VERSION ""

NS_ :

BS_:

BU_: VDM CMR_DSMC SOBDMC_HPCM_FD1 IPMA_ADAS PSCM ABS_ESC TCCM TCM_DSL PCM_HEV PCM ECM_Diesel GENERIC_GWMWakeup GWM _delete TSTR

BO_ 90 Gear_Shift_by_Wire_FD1: 8 GWM
 SG_ TrnGsmNtmState_D_Actl : 55|2@0+ (1,0) [0|3] "SED"  ABS_ESC,PCM,PCM_HEV,TCM_DSL
 SG_ DrQltyDrv_D_StatGsm : 42|3@0+ (1,0) [0|7] "SED"  ABS_ESC,PCM,PCM_HEV,TCM_DSL,IPMA_ADAS
 SG_ TrnBtsiOvrrd_B_Stat : 43|1@0+ (1,0) [0|1] "SED"  PCM,PCM_HEV,TCM_DSL
 SG_ GsmGearMsgTxt_D_Rq : 63|2@0+ (1,0) [0|3] "SED" Vector__XXX
 SG_ TrnRng_D_RqGsm : 51|4@0+ (1,0) [0|15] "SED"  PCM,TCM_DSL
 SG_ PrkBrkActv_D_RqGsmGear : 53|2@0+ (1,0) [0|3] "SED"  ABS_ESC
 SG_ TrnValidGearRq_D_Stat : 25|2@0+ (1,0) [0|3] "SED"  PCM,PCM_HEV,TCM_DSL
 SG_ TrnGearRqCnt_B_Actl : 26|1@0+ (1,0) [0|1] "unitless"  PCM,PCM_HEV,TCM_DSL
 SG_ TrnGearButtn_U_Actl : 23|8@0+ (0.05,0) [0|12.7] "VOLT"  TCM_DSL
 SG_ TrnGearButtn_B_ActlR2 : 8|1@0+ (1,0) [0|1] "SED"  PCM,PCM_HEV,TCM_DSL
 SG_ TrnGearButtn_B_ActlR1 : 9|1@0+ (1,0) [0|1] "SED"  PCM,PCM_HEV,TCM_DSL
 SG_ TrnGearButtn_B_ActlR0 : 10|1@0+ (1,0) [0|1] "SED"  PCM,PCM_HEV,TCM_DSL
 SG_ TrnGearButtn_B_ActlP2 : 11|1@0+ (1,0) [0|1] "SED"  TCM_DSL,PCM,PCM_HEV
 SG_ TrnGearButtn_B_ActlP1 : 12|1@0+ (1,0) [0|1] "SED"  PCM,PCM_HEV,TCM_DSL
 SG_ TrnGearButtn_B_ActlP0 : 13|1@0+ (1,0) [0|1] "SED"  PCM,PCM_HEV,TCM_DSL
 SG_ TrnGearButtn_B_ActlN2 : 14|1@0+ (1,0) [0|1] "SED"  PCM,PCM_HEV,TCM_DSL
 SG_ TrnGearButtn_B_ActlN1 : 15|1@0+ (1,0) [0|1] "SED"  PCM,PCM_HEV,TCM_DSL
 SG_ TrnGearButtn_B_ActlN0 : 0|1@0+ (1,0) [0|1] "SED"  PCM,PCM_HEV,TCM_DSL
 SG_ TrnGearButtn_B_ActlM2 : 1|1@0+ (1,0) [0|1] "SED"  PCM,PCM_HEV,TCM_DSL
 SG_ TrnGearButtn_B_ActlM1 : 2|1@0+ (1,0) [0|1] "SED"  PCM,PCM_HEV,TCM_DSL
 SG_ TrnGearButtn_B_ActlM0 : 3|1@0+ (1,0) [0|1] "SED"  PCM,PCM_HEV,TCM_DSL
 SG_ TrnGearButtn_B_ActlD2 : 4|1@0+ (1,0) [0|1] "SED"  PCM,PCM_HEV,TCM_DSL
 SG_ TrnGearButtn_B_ActlD1 : 5|1@0+ (1,0) [0|1] "SED"  PCM,PCM_HEV,TCM_DSL
 SG_ TrnGearButtn_B_ActlD0 : 6|1@0+ (1,0) [0|1] "SED"  PCM,PCM_HEV,TCM_DSL
 SG_ TrnGear_No_Cs : 39|8@0+ (1,0) [0|255] "Unitless"  SOBDMC_HPCM_FD1,PCM,PCM_HEV,TCM_DSL
 SG_ TrnGear_No_Cnt : 47|4@0+ (1,0) [0|15] "Unitless"  SOBDMC_HPCM_FD1,PCM,PCM_HEV,TCM_DSL
 SG_ TrnGear_D_RqDrv : 31|5@0+ (1,0) [0|31] "SED"  SOBDMC_HPCM_FD1,PCM,PCM_HEV,TCM_DSL
 SG_ BrkSwtchPos_B_ActlGsm : 7|1@0+ (1,0) [0|1] "SED"  PCM,PCM_HEV,TCM_DSL

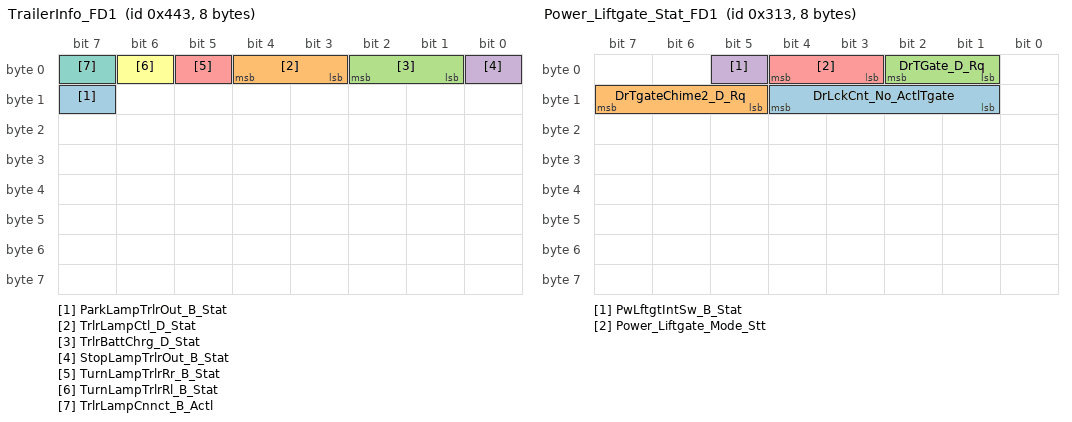
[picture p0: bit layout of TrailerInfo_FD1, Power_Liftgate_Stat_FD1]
BO_ 1091 TrailerInfo_FD1: 8 GWM
 SG_ ParkLampTrlrOut_B_Stat : 15|1@0+ (1,0) [0|1] "SED" Vector__XXX
 SG_ TrlrLampCtl_D_Stat : 4|2@0+ (1,0) [0|3] "SED" Vector__XXX
 SG_ TrlrBattChrg_D_Stat : 2|2@0+ (1,0) [0|3] "SED" Vector__XXX
 SG_ StopLampTrlrOut_B_Stat : 0|1@0+ (1,0) [0|1] "SED" Vector__XXX
 SG_ TurnLampTrlrRr_B_Stat : 5|1@0+ (1,0) [0|1] "SED" Vector__XXX
 SG_ TurnLampTrlrRl_B_Stat : 6|1@0+ (1,0) [0|1] "SED" Vector__XXX
 SG_ TrlrLampCnnct_B_Actl : 7|1@0+ (1,0) [0|1] "SED"  VDM,PCM_HEV,ECM_Diesel,PCM,TCM_DSL,ABS_ESC,IPMA_ADAS,PSCM

BO_ 138 ActiveFrontStrg_Stat2_FD1: 8 GWM
 SG_ SteWhlRelCalib_T_Actl : 7|8@0+ (1,0) [0|255] "ms" Vector__XXX
 SG_ SteWhlRelCalib_An_Sns : 15|15@0+ (0.1,-1600) [-1600|1676.5] "deg"  CMR_DSMC,PSCM,TCCM

BO_ 131 Steering_Data_FD1: 8 GWM
 SG_ AccButtnGapDecPress : 12|1@0+ (1,0) [0|1] "SED"  IPMA_ADAS
 SG_ HeadLghtHiCtrl_D_RqAhb : 43|3@0+ (1,0) [0|7] "SED" Vector__XXX
 SG_ AhbStat_B_Dsply : 33|1@0+ (1,0) [0|1] "SED" Vector__XXX
 SG_ WiprFrontSwtch_D_Stat : 47|4@0+ (1,0) [0|15] "SED" Vector__XXX
 SG_ HeadLghtHiOn_B_StatAhb : 34|1@0+ (1,0) [0|1] "SED"  IPMA_ADAS
 SG_ HeadLghtHiFlash_D_Actl : 36|2@0+ (1,0) [0|3] "SED"  IPMA_ADAS
 SG_ TjaButtnOnOffPress : 40|1@0+ (1,0) [0|1] "SED"  IPMA_ADAS
 SG_ AccButtnGapTogglePress : 32|1@0+ (1,0) [0|1] "SED"  IPMA_ADAS
 SG_ HeadLghtHiFlash_D_Stat : 7|2@0+ (1,0) [0|3] "SED" Vector__XXX
 SG_ WiprFront_D_Stat : 3|4@0+ (1,0) [0|15] "SED"  ABS_ESC,IPMA_ADAS,PCM,PCM_HEV
 SG_ TurnLghtSwtch_D_Stat : 5|2@0+ (1,0) [0|3] "SED"  IPMA_ADAS,PSCM
 SG_ LghtAmb_D_Sns : 15|3@0+ (1,0) [0|7] "SED"  IPMA_ADAS
 SG_ AccButtnGapIncPress : 11|1@0+ (1,0) [0|1] "SED"  IPMA_ADAS
 SG_ AslButtnOnOffPress : 9|1@0+ (1,0) [0|1] "SED"  ECM_Diesel,PCM,PCM_HEV
 SG_ AslButtnOnOffCnclPress : 10|1@0+ (1,0) [0|1] "SED"  ECM_Diesel,PCM,PCM_HEV
 SG_ CcButtnOnPress : 37|1@0+ (1,0) [0|1] "SED"  ECM_Diesel,IPMA_ADAS,PCM,PCM_HEV
 SG_ CcButtnOnOffPress : 38|1@0+ (1,0) [0|1] "SED"  ECM_Diesel,IPMA_ADAS,PCM,PCM_HEV
 SG_ CcButtnOnOffCnclPress : 39|1@0+ (1,0) [0|1] "SED"  ECM_Diesel,IPMA_ADAS,PCM,PCM_HEV
 SG_ CcButtnOffPress : 24|1@0+ (1,0) [0|1] "SED"  ECM_Diesel,IPMA_ADAS,PCM,PCM_HEV
 SG_ CcAsllButtnResPress : 25|1@0+ (1,0) [0|1] "SED"  ECM_Diesel,IPMA_ADAS,PCM,PCM_HEV
 SG_ CcAslButtnSetPress : 26|1@0+ (1,0) [0|1] "SED" Vector__XXX
 SG_ CcAslButtnSetIncPress : 27|1@0+ (1,0) [0|1] "SED"  ABS_ESC,ECM_Diesel,IPMA_ADAS,PCM,PCM_HEV
 SG_ CcAslButtnSetDecPress : 28|1@0+ (1,0) [0|1] "SED"  ABS_ESC,ECM_Diesel,IPMA_ADAS,PCM,PCM_HEV
 SG_ CcAslButtnResIncPress : 29|1@0+ (1,0) [0|1] "SED"  ABS_ESC,ECM_Diesel,IPMA_ADAS,PCM,PCM_HEV
 SG_ CcAslButtnResDecPress : 30|1@0+ (1,0) [0|1] "SED" Vector__XXX
 SG_ CcAslButtnOnPress : 31|1@0+ (1,0) [0|1] "SED"  ECM_Diesel,IPMA_ADAS,PCM,PCM_HEV
 SG_ CcAslButtnOnOffCncl : 16|1@0+ (1,0) [0|1] "SED" Vector__XXX
 SG_ CcAslButtnOffCnclPress : 17|1@0+ (1,0) [0|1] "SED" Vector__XXX
 SG_ CcAslButtnIndxIncPress : 18|1@0+ (1,0) [0|1] "SED"  ECM_Diesel,PCM,PCM_HEV
 SG_ CcAslButtnIndxDecPress : 19|1@0+ (1,0) [0|1] "SED"  ECM_Diesel,PCM,PCM_HEV
 SG_ CcAslButtnDeny_B_Actl : 20|1@0+ (1,0) [0|1] "SED"  ECM_Diesel,IPMA_ADAS,PCM,PCM_HEV
 SG_ CcAslButtnCnclResPress : 21|1@0+ (1,0) [0|1] "SED"  ECM_Diesel,IPMA_ADAS,PCM,PCM_HEV
 SG_ CcAslButtnCnclPress : 8|1@0+ (1,0) [0|1] "SED"  ECM_Diesel,IPMA_ADAS,PCM,PCM_HEV
 SG_ LaSwtchPos_D_Stat : 23|2@0+ (1,0) [0|3] "SED"  IPMA_ADAS

BO_ 787 Power_Liftgate_Stat_FD1: 8 GWM
 SG_ DrLckCnt_No_ActlTgate : 12|4@0+ (1,0) [0|15] "unitless" Vector__XXX
 SG_ DrTgateChime2_D_Rq : 15|3@0+ (1,0) [0|7] "SED" Vector__XXX
 SG_ DrTGate_D_Rq : 2|2@0+ (1,0) [0|3] "SED"  ECM_Diesel
 SG_ PwLftgtIntSw_B_Stat : 5|1@0+ (1,0) [0|1] "SED" Vector__XXX
 SG_ Power_Liftgate_Mode_Stt : 4|2@0+ (1,0) [0|3] "SED" Vector__XXX

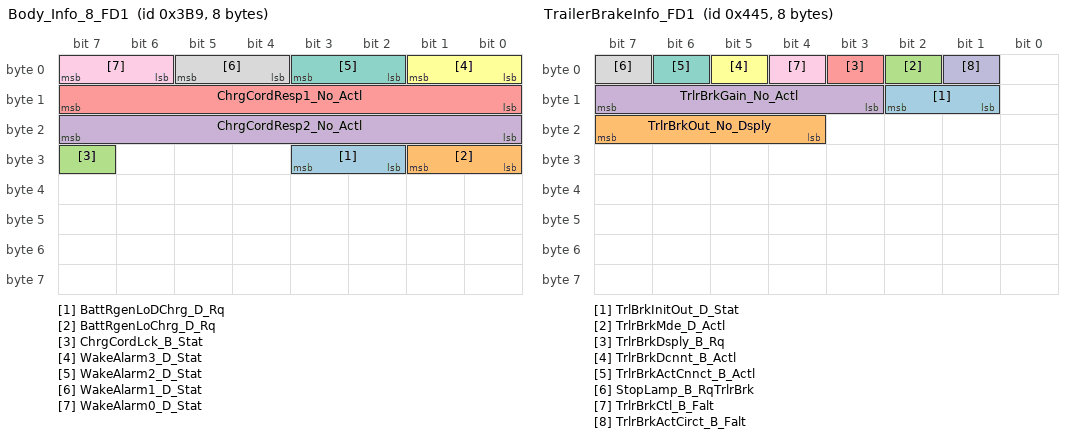
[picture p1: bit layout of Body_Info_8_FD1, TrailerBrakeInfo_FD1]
BO_ 953 Body_Info_8_FD1: 8 GWM
 SG_ BattRgenLoDChrg_D_Rq : 27|2@0+ (1,0) [0|3] "SED"  PCM_HEV,PCM
 SG_ BattRgenLoChrg_D_Rq : 25|2@0+ (1,0) [0|3] "SED"  PCM_HEV,PCM
 SG_ ChrgCordLck_B_Stat : 31|1@0+ (1,0) [0|1] "SED" Vector__XXX
 SG_ ChrgCordResp2_No_Actl : 23|8@0+ (1,0) [0|255] "unitless" Vector__XXX
 SG_ ChrgCordResp1_No_Actl : 15|8@0+ (1,0) [0|255] "unitless" Vector__XXX
 SG_ WakeAlarm3_D_Stat : 1|2@0+ (1,0) [0|3] "SED" Vector__XXX
 SG_ WakeAlarm2_D_Stat : 3|2@0+ (1,0) [0|3] "SED" Vector__XXX
 SG_ WakeAlarm1_D_Stat : 5|2@0+ (1,0) [0|3] "SED"  ECM_Diesel,PCM_HEV
 SG_ WakeAlarm0_D_Stat : 7|2@0+ (1,0) [0|3] "SED"  SOBDMC_HPCM_FD1

BO_ 1093 TrailerBrakeInfo_FD1: 8 GWM
 SG_ TrlBrkInitOut_D_Stat : 10|2@0+ (1,0) [0|3] "SED" Vector__XXX
 SG_ TrlrBrkOut_No_Dsply : 23|4@0+ (1,0) [0|15] "unitless" Vector__XXX
 SG_ TrlrBrkMde_D_Actl : 2|1@0+ (1,0) [0|1] "SED" Vector__XXX
 SG_ TrlrBrkGain_No_Actl : 15|5@0+ (0.5,0) [0|15.5] "unitless" Vector__XXX
 SG_ TrlrBrkDsply_B_Rq : 3|1@0+ (1,0) [0|1] "SED" Vector__XXX
 SG_ TrlrBrkDcnnt_B_Actl : 5|1@0+ (1,0) [0|1] "SED"  VDM
 SG_ TrlrBrkActCnnct_B_Actl : 6|1@0+ (1,0) [0|1] "SED"  VDM,ECM_Diesel,PCM,TCM_DSL,ABS_ESC,PSCM,TCCM,IPMA_ADAS
 SG_ StopLamp_B_RqTrlrBrk : 7|1@0+ (1,0) [0|1] "SED" Vector__XXX
 SG_ TrlrBrkCtl_B_Falt : 4|1@0+ (1,0) [0|1] "SED"  IPMA_ADAS
 SG_ TrlrBrkActCirct_B_Falt : 1|1@0+ (1,0) [0|1] "SED"  IPMA_ADAS

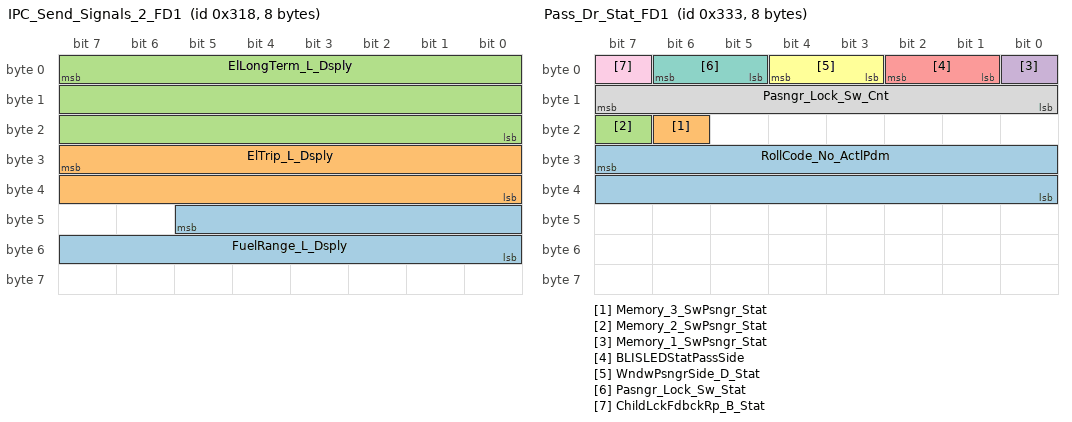
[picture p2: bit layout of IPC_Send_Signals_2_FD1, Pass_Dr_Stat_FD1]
BO_ 792 IPC_Send_Signals_2_FD1: 8 GWM
 SG_ FuelRange_L_Dsply : 45|14@0+ (0.1,0) [0|1638.3] "km"  ECM_Diesel
 SG_ ElTrip_L_Dsply : 31|16@0+ (0.1,0) [0|6553.3] "unitless" Vector__XXX
 SG_ ElLongTerm_L_Dsply : 7|24@0+ (0.1,0) [0|1677721.3] "unitless" Vector__XXX

BO_ 968 Cluster_Lighting_Rq_FD1: 8 GWM
 SG_ SlMde_D_Rq : 27|2@0+ (1,0) [0|3] "SED"  ECM_Diesel
 SG_ IsaOffst_D_Rq : 31|4@0+ (1,0) [0|15] "SED"  ECM_Diesel

BO_ 819 Pass_Dr_Stat_FD1: 8 GWM
 SG_ RollCode_No_ActlPdm : 31|16@0+ (1,0) [0|65535] "Unitless" Vector__XXX
 SG_ Memory_3_SwPsngr_Stat : 22|1@0+ (1,0) [0|1] "SED" Vector__XXX
 SG_ Memory_2_SwPsngr_Stat : 23|1@0+ (1,0) [0|1] "SED" Vector__XXX
 SG_ Memory_1_SwPsngr_Stat : 0|1@0+ (1,0) [0|1] "SED" Vector__XXX
 SG_ BLISLEDStatPassSide : 2|2@0+ (1,0) [0|3] "SED"  IPMA_ADAS
 SG_ WndwPsngrSide_D_Stat : 4|2@0+ (1,0) [0|3] "SED"  ECM_Diesel,PCM
 SG_ Pasngr_Lock_Sw_Stat : 6|2@0+ (1,0) [0|3] "SED" Vector__XXX
 SG_ Pasngr_Lock_Sw_Cnt : 15|8@0+ (1,0) [0|255] "Cnt" Vector__XXX
 SG_ ChildLckFdbckRp_B_Stat : 7|1@0+ (1,0) [0|1] "SED" Vector__XXX

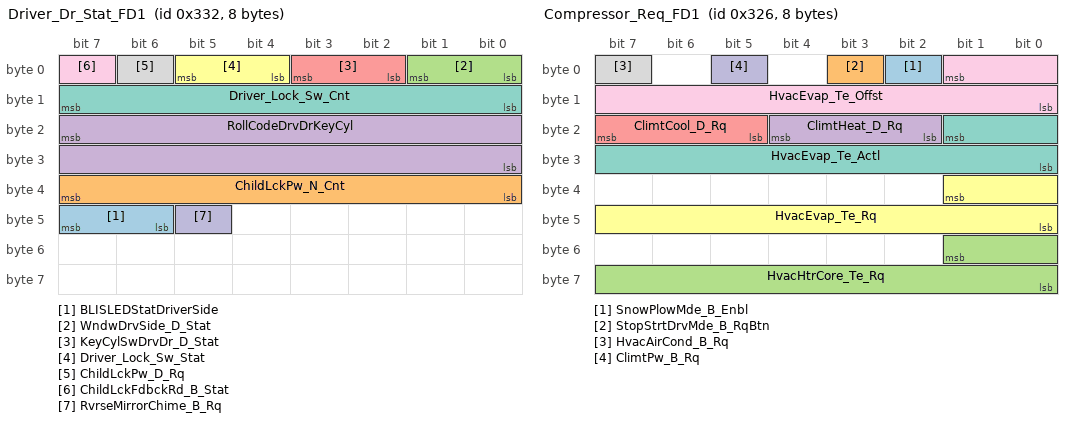
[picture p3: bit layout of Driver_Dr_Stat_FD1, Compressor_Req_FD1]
BO_ 818 Driver_Dr_Stat_FD1: 8 GWM
 SG_ BLISLEDStatDriverSide : 47|2@0+ (1,0) [0|3] "SED"  IPMA_ADAS
 SG_ ChildLckPw_N_Cnt : 39|8@0+ (1,0) [0|255] "unitless" Vector__XXX
 SG_ WndwDrvSide_D_Stat : 1|2@0+ (1,0) [0|3] "SED"  ECM_Diesel,PCM
 SG_ RollCodeDrvDrKeyCyl : 23|16@0+ (1,0) [0|65535] "Unitless" Vector__XXX
 SG_ KeyCylSwDrvDr_D_Stat : 3|2@0+ (1,0) [0|3] "SED" Vector__XXX
 SG_ Driver_Lock_Sw_Stat : 5|2@0+ (1,0) [0|3] "SED" Vector__XXX
 SG_ Driver_Lock_Sw_Cnt : 15|8@0+ (1,0) [0|255] "Cnt" Vector__XXX
 SG_ ChildLckPw_D_Rq : 6|1@0+ (1,0) [0|1] "SED" Vector__XXX
 SG_ ChildLckFdbckRd_B_Stat : 7|1@0+ (1,0) [0|1] "SED" Vector__XXX
 SG_ RvrseMirrorChime_B_Rq : 45|1@0+ (1,0) [0|1] "SED" Vector__XXX

BO_ 806 Compressor_Req_FD1: 8 GWM
 SG_ SnowPlowMde_B_Enbl : 2|1@0+ (1,0) [0|1] "SED" Vector__XXX
 SG_ StopStrtDrvMde_B_RqBtn : 3|1@0+ (1,0) [0|1] "SED"  ECM_Diesel,PCM
 SG_ HvacHtrCore_Te_Rq : 49|10@0+ (0.25,-50) [-50|205.75] "degC"  PCM_HEV,SOBDMC_HPCM_FD1,ECM_Diesel
 SG_ ClimtHeat_D_Rq : 20|3@0+ (1,0) [0|7] "SED"  SOBDMC_HPCM_FD1,ECM_Diesel,PCM,PCM_HEV
 SG_ ClimtCool_D_Rq : 23|3@0+ (1,0) [0|7] "SED"  SOBDMC_HPCM_FD1,ECM_Diesel,PCM,PCM_HEV
 SG_ HvacEvap_Te_Rq : 33|10@0+ (0.125,-50) [-50|77.875] "Degrees C"  SOBDMC_HPCM_FD1,ECM_Diesel,PCM,PCM_HEV
 SG_ HvacEvap_Te_Actl : 17|10@0+ (0.125,-50) [-50|77.75] "Degrees C"  SOBDMC_HPCM_FD1,ECM_Diesel,PCM,PCM_HEV
 SG_ HvacAirCond_B_Rq : 7|1@0+ (1,0) [0|1] "SED"  ECM_Diesel,PCM,PCM_HEV
 SG_ HvacEvap_Te_Offst : 1|10@0+ (0.125,-50) [-50|77.875] "Degrees C"  ECM_Diesel,PCM,PCM_HEV
 SG_ ClimtPw_B_Rq : 5|1@0+ (1,0) [0|1] "SED"  ECM_Diesel,PCM

BO_ 765 Mc_Send_Signals_2_FD1: 8 GWM
 SG_ Mc_VehTimeFrmtUsrSel_St : 1|2@0+ (1,0) [0|3] "SED" Vector__XXX
 SG_ Running_Board_Cmd : 21|2@0+ (1,0) [0|3] "SED" Vector__XXX
 SG_ EngExhMdeQuiet_D2_Rq : 55|3@0+ (1,0) [0|7] "SED"  PCM
 SG_ EdmSailMde_B_RqDrv : 48|1@0+ (1,0) [0|1] "SED"  ECM_Diesel
 SG_ DrvInputRequired_B_Rq : 32|1@0+ (1,0) [0|1] "SED" Vector__XXX
 SG_ AwdRnge_D_ActlIpc : 29|3@0+ (1,0) [0|7] "SED" Vector__XXX
 SG_ BalrSwtch_D_Stat : 57|2@0+ (1,0) [0|3] "SED"  IPMA_ADAS
 SG_ BalrMde_D_Rq : 59|2@0+ (1,0) [0|3] "SED"  IPMA_ADAS
 SG_ WaitToStartLamp_D_Falt : 50|2@0+ (1,0) [0|3] "SED"  ECM_Diesel
 SG_ EsaOn_B_Rq : 15|1@0+ (1,0) [0|1] "SED"  PSCM
 SG_ BttOn_B_Rq : 26|1@0+ (1,0) [0|1] "SED"  IPMA_ADAS
 SG_ Btt_L_Actl : 39|7@0+ (0.1,0) [0|12.5] "meter"  IPMA_ADAS
 SG_ SelDrvMdeTxtReset_B_Rq : 40|1@0+ (1,0) [0|1] "SED"  ABS_ESC
 SG_ SelDrvMdeDsply_B_Avail : 41|1@0+ (1,0) [0|1] "SED"  ABS_ESC
 SG_ Mc_VehUntTrpCoUsrSel_St : 23|1@0+ (1,0) [0|1] "SED" Vector__XXX
 SG_ Mc_VehUnitTempUsrSel_St : 22|1@0+ (1,0) [0|1] "SED" Vector__XXX
 SG_ Mc_VehLangUsrSel_St : 7|6@0+ (1,0) [0|63] "SED" Vector__XXX

BO_ 559 ElecHorizon_Data2_FD1: 8 GWM
 SG_ EhData2_No_Actl : 7|64@0+ (1,0) [0|1.84467440737096E+019] "unitless"  IPMA_ADAS,ECM_Diesel

BO_ 558 ElecHorizon_Data1_FD1: 8 GWM
 SG_ EhData1_No_Actl : 7|64@0+ (1,0) [0|1.84467440737096E+019] "unitless"  IPMA_ADAS,ECM_Diesel

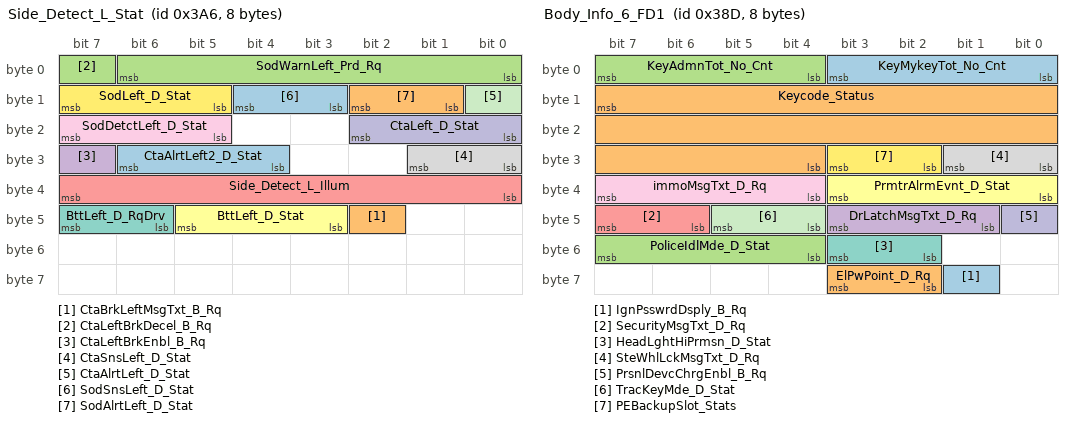
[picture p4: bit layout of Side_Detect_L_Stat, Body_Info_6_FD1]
BO_ 934 Side_Detect_L_Stat: 8 IPMA_ADAS
 SG_ CtaAlrtLeft2_D_Stat : 30|3@0+ (1,0) [0|7] "SED"  GWM
 SG_ CtaBrkLeftMsgTxt_B_Rq : 42|1@0+ (1,0) [0|1] "SED"  GWM
 SG_ CtaLeftBrkDecel_B_Rq : 7|1@0+ (1,0) [0|1] "SED"  GWM,ABS_ESC
 SG_ CtaLeftBrkEnbl_B_Rq : 31|1@0+ (1,0) [0|1] "SED"  GWM,ABS_ESC
 SG_ Side_Detect_L_Illum : 39|8@0+ (1,0) [0|255] "Percent"  GWM
 SG_ BttLeft_D_Stat : 45|3@0+ (1,0) [0|7] "SED"  GWM
 SG_ BttLeft_D_RqDrv : 47|2@0+ (1,0) [0|3] "SED"  GWM
 SG_ CtaSnsLeft_D_Stat : 25|2@0+ (1,0) [0|3] "SED"  GWM
 SG_ SodDetctLeft_D_Stat : 23|3@0+ (1,0) [0|7] "SED"  GWM
 SG_ CtaLeft_D_Stat : 18|3@0+ (1,0) [0|7] "SED"  GWM
 SG_ CtaAlrtLeft_D_Stat : 8|1@0+ (1,0) [0|1] "SED"  GWM
 SG_ SodLeft_D_Stat : 15|3@0+ (1,0) [0|7] "SED"  GWM
 SG_ SodSnsLeft_D_Stat : 12|2@0+ (1,0) [0|3] "SED"  GWM
 SG_ SodAlrtLeft_D_Stat : 10|2@0+ (1,0) [0|3] "SED"  GWM
 SG_ SodWarnLeft_Prd_Rq : 6|7@0+ (1,0) [0|127] "millisecond"  GWM

BO_ 1072 Cluster_Info1_FD1: 8 GWM
 SG_ LscmbbStat_B_Actl : 2|1@0+ (1,0) [0|1] "SED" Vector__XXX
 SG_ HaDsplyCpblty_B_Stat : 42|1@0+ (1,0) [0|1] "SED"  IPMA_ADAS
 SG_ AccDeny_B_RqIpc : 7|1@0+ (1,0) [0|1] "SED"  IPMA_ADAS
 SG_ DrvSlipCtlMde_D_Rq : 33|2@0+ (1,0) [0|3] "SED"  ABS_ESC
 SG_ EngIdlShutDown_B_RqDrv : 3|1@0+ (1,0) [0|1] "SED"  ECM_Diesel,PCM,PCM_HEV
 SG_ HsaMde_D_Rq : 54|2@0+ (1,0) [0|3] "SED"  ABS_ESC
 SG_ NtrlTowMdeEnbl_B_RqDrv : 1|1@0+ (1,0) [0|1] "SED"  TCCM,TCM_DSL,PCM_HEV,PCM
 SG_ BulbChkActv_B_Stat : 55|1@0+ (1,0) [0|1] "SED" Vector__XXX
 SG_ ParkDetect_Stat : 52|1@0+ (1,0) [0|1] "SED"  PCM_HEV,PCM
 SG_ ReducedGuard_D_Rq : 51|2@0+ (1,0) [0|3] "SED" Vector__XXX
 SG_ TrlrBrkMde_D_Rq : 57|1@0+ (1,0) [0|1] "SED" Vector__XXX
 SG_ TRLR_SWAY_CONFIG_CMD : 56|1@0+ (1,0) [0|1] "SED"  ABS_ESC
 SG_ TRAILER_BRAKE_CONFIG : 37|1@0+ (1,0) [0|1] "SED" Vector__XXX
 SG_ Power_Liftgate_Mode_Cmd : 39|1@0+ (1,0) [0|1] "SED" Vector__XXX
 SG_ AccEnbl_B_RqDrv : 35|1@0+ (1,0) [0|1] "SED"  IPMA_ADAS
 SG_ OdometerMasterValue : 15|24@0+ (1,0) [0|16777214] "km"  VDM,SOBDMC_HPCM_FD1,TCCM,CMR_DSMC,ABS_ESC,ECM_Diesel,IPMA_ADAS,PCM,PCM_HEV,PSCM,TCM_DSL
 SG_ EngOilLife_B_RqReset : 43|1@0+ (1,0) [0|1] "SED"  ECM_Diesel,PCM,PCM_HEV
 SG_ ePRNDL_MODE : 0|1@0+ (1,0) [0|1] "SED"  PCM,PCM_HEV,TCM_DSL
 SG_ DrvSlipCtlMde_B_Rq2 : 34|1@0+ (1,0) [0|1] "SED"  ABS_ESC
 SG_ MetricActv_B_Actl : 6|1@0+ (1,0) [0|1] "SED"  ECM_Diesel,IPMA_ADAS,PCM,PCM_HEV
 SG_ KeyTypeChngMykey_D_Rq : 41|2@0+ (1,0) [0|3] "SED" Vector__XXX
 SG_ ManRgen_D_Rq : 5|2@0+ (1,0) [0|3] "SED"  ECM_Diesel

BO_ 909 Body_Info_6_FD1: 8 GWM
 SG_ IgnPsswrdDsply_B_Rq : 57|1@0+ (1,0) [0|1] "SED" Vector__XXX
 SG_ ElPwPoint_D_Rq : 59|2@0+ (1,0) [0|3] "SED" Vector__XXX
 SG_ PoliceIdlMde_D_Stat : 55|4@0+ (1,0) [0|15] "SED" Vector__XXX
 SG_ DrLatchMsgTxt_D_Rq : 43|3@0+ (1,0) [0|7] "SED" Vector__XXX
 SG_ SecurityMsgTxt_D_Rq : 47|2@0+ (1,0) [0|3] "SED" Vector__XXX
 SG_ PrmtrAlrmEvnt_D_Stat : 35|4@0+ (1,0) [0|15] "SED" Vector__XXX
 SG_ HeadLghtHiPrmsn_D_Stat : 51|2@0+ (1,0) [0|3] "SED"  IPMA_ADAS
 SG_ SteWhlLckMsgTxt_D_Rq : 25|2@0+ (1,0) [0|3] "SED" Vector__XXX
 SG_ immoMsgTxt_D_Rq : 39|4@0+ (1,0) [0|15] "SED" Vector__XXX
 SG_ PrsnlDevcChrgEnbl_B_Rq : 40|1@0+ (1,0) [0|1] "SED" Vector__XXX
 SG_ TracKeyMde_D_Stat : 45|2@0+ (1,0) [0|3] "SED" Vector__XXX
 SG_ PEBackupSlot_Stats : 27|2@0+ (1,0) [0|3] "SED" Vector__XXX
 SG_ KeyMykeyTot_No_Cnt : 3|4@0+ (1,0) [0|15] "Counts" Vector__XXX
 SG_ Keycode_Status : 15|20@0+ (1,0) [0|1048575] "unitless" Vector__XXX
 SG_ KeyAdmnTot_No_Cnt : 7|4@0+ (1,0) [0|15] "Counts" Vector__XXX

BO_ 963 BCM_Lamp_Stat_FD1: 8 GWM
 SG_ Illuminated_Entry_Stat : 63|2@0+ (1,0) [0|3] "SED" Vector__XXX
 SG_ Dr_Courtesy_Light_Stat : 49|2@0+ (1,0) [0|3] "SED" Vector__XXX
 SG_ Courtesy_Delay_Status : 51|2@0+ (1,0) [0|3] "SED" Vector__XXX
 SG_ ImpactEvntFdbck_D_Stat : 53|2@0+ (1,0) [0|3] "SED"  CMR_DSMC
 SG_ WrlssAcsyChrgInhbt_B_Rq : 40|1@0+ (1,0) [0|1] "SED" Vector__XXX
 SG_ PudLampPsngr_D_Rq : 57|2@0+ (1,0) [0|3] "SED" Vector__XXX
 SG_ HeadLampLoOut_B_Stat : 32|1@0+ (1,0) [0|1] "SED" Vector__XXX
 SG_ CrnrLghtRight_Pc_Rq : 47|7@0+ (1,0) [0|100] "percent" Vector__XXX
 SG_ CrnrLghtLeft_Pc_Rq : 39|7@0+ (1,0) [0|100] "percent" Vector__XXX
 SG_ HeadLghtHiFdbck_D_Stat : 55|2@0+ (1,0) [0|3] "SED" Vector__XXX
 SG_ PudLampDrv_D_Rq : 59|2@0+ (1,0) [0|3] "SED" Vector__XXX
 SG_ TrnNotInPrkChime_B_Rq : 24|1@0+ (1,0) [0|1] "SED" Vector__XXX
 SG_ PrkLightChime_B_Rq : 25|1@0+ (1,0) [0|1] "SED" Vector__XXX
 SG_ KeyInIgnWarn_B_Cmd : 27|1@0+ (1,0) [0|1] "SED" Vector__XXX
 SG_ HomeSafeLtChime_B_Rq : 28|1@0+ (1,0) [0|1] "SED" Vector__XXX
 SG_ StopLghtOn_B_Stat : 8|1@0+ (1,0) [0|1] "SED" Vector__XXX
 SG_ RvrseLghtOn_B_Stat : 9|1@0+ (1,0) [0|1] "SED" Vector__XXX
 SG_ PrkLght_D_Stat : 13|2@0+ (1,0) [0|3] "SED" Vector__XXX
 SG_ HeadLghtSwtch_D_Stat : 15|2@0+ (1,0) [0|3] "SED"  IPMA_ADAS
 SG_ HeadLampLoFrOn_B_Stat : 2|1@0+ (1,0) [0|1] "SED"  IPMA_ADAS
 SG_ HeadLampLoFlOn_B_Stat : 3|1@0+ (1,0) [0|1] "SED"  IPMA_ADAS
 SG_ HeadLampLoActv_B_Stat : 4|1@0+ (1,0) [0|1] "SED"  IPMA_ADAS,PCM,ECM_Diesel
 SG_ Headlamp_On_Wrning_Cmd : 29|1@0+ (1,0) [0|1] "SED" Vector__XXX
 SG_ Park_Brake_Chime_Rqst : 26|1@0+ (1,0) [0|1] "SED" Vector__XXX
 SG_ HeadLghtHiOn_B_Stat : 1|1@0+ (1,0) [0|1] "SED"  ECM_Diesel,IPMA_ADAS,PCM
 SG_ BrkWarnInd_B_Rq : 20|1@0+ (1,0) [0|1] "SED" Vector__XXX
 SG_ Brk_Fluid_Lvl_Low : 31|2@0+ (1,0) [0|3] "SED" Vector__XXX
 SG_ ReducedGuard_D_Stat : 19|2@0+ (1,0) [0|3] "SED" Vector__XXX
 SG_ Perimeter_Alarm_Status : 17|2@0+ (1,0) [0|3] "SED"  ABS_ESC
 SG_ Courtesy_BSave_Stat : 7|2@0+ (1,0) [0|3] "SED" Vector__XXX
 SG_ DrTgateLck_D_Stat : 61|2@0+ (1,0) [0|3] "SED" Vector__XXX
 SG_ WndwGlbl_D_Cmd : 23|3@0+ (1,0) [0|7] "SED" Vector__XXX
 SG_ PudLamp_D_Rq : 11|2@0+ (1,0) [0|3] "SED" Vector__XXX
 SG_ DayRnngLampOn_B_Stat : 5|1@0+ (1,0) [0|1] "SED" Vector__XXX
 SG_ PerimeterAlarmChimeRq : 0|1@0+ (1,0) [0|1] "SED" Vector__XXX

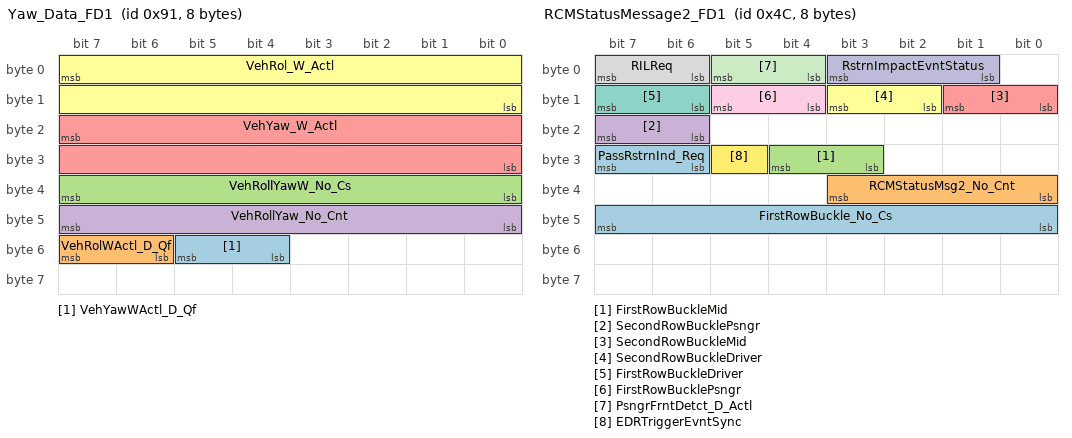
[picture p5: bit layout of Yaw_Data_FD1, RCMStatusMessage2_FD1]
BO_ 145 Yaw_Data_FD1: 8 GWM
 SG_ VehYawWActl_D_Qf : 53|2@0+ (1,0) [0|3] "SED"  VDM,IPMA_ADAS,ABS_ESC
 SG_ VehRolWActl_D_Qf : 55|2@0+ (1,0) [0|3] "SED"  VDM,IPMA_ADAS,ABS_ESC
 SG_ VehRollYawW_No_Cs : 39|8@0+ (1,0) [0|255] "Unitless"  IPMA_ADAS,ABS_ESC
 SG_ VehRollYaw_No_Cnt : 47|8@0+ (1,0) [0|255] "Unitless"  VDM,IPMA_ADAS,ABS_ESC
 SG_ VehYaw_W_Actl : 23|16@0+ (0.0002,-6.5) [-6.5|6.6066] "rad/s"  VDM,ABS_ESC,PSCM,IPMA_ADAS
 SG_ VehRol_W_Actl : 7|16@0+ (0.0002,-6.5) [-6.5|6.6066] "rad/s"  VDM,ABS_ESC,IPMA_ADAS

BO_ 76 RCMStatusMessage2_FD1: 8 GWM
 SG_ FirstRowBuckle_No_Cs : 47|8@0+ (1,0) [0|255] "unitless"  IPMA_ADAS
 SG_ RCMStatusMsg2_No_Cnt : 35|4@0+ (1,0) [0|15] "Unitless"  IPMA_ADAS
 SG_ FirstRowBuckleMid : 28|2@0+ (1,0) [0|3] "SED"  IPMA_ADAS
 SG_ SecondRowBucklePsngr : 23|2@0+ (1,0) [0|3] "SED" Vector__XXX
 SG_ SecondRowBuckleMid : 9|2@0+ (1,0) [0|3] "SED" Vector__XXX
 SG_ SecondRowBuckleDriver : 11|2@0+ (1,0) [0|3] "SED" Vector__XXX
 SG_ FirstRowBuckleDriver : 15|2@0+ (1,0) [0|3] "SED"  CMR_DSMC,ABS_ESC,IPMA_ADAS,ECM_Diesel,PCM,PCM_HEV,TCM_DSL
 SG_ RILReq : 7|2@0+ (1,0) [0|3] "SED" Vector__XXX
 SG_ FirstRowBucklePsngr : 13|2@0+ (1,0) [0|3] "SED"  IPMA_ADAS
 SG_ RstrnImpactEvntStatus : 3|3@0+ (1,0) [0|7] "SED"  CMR_DSMC,SOBDMC_HPCM_FD1,ABS_ESC,IPMA_ADAS,ECM_Diesel,PCM,PCM_HEV,TCM_DSL
 SG_ PsngrFrntDetct_D_Actl : 5|2@0+ (1,0) [0|3] "SED" Vector__XXX
 SG_ EDRTriggerEvntSync : 29|1@0+ (1,0) [0|1] "SED"  IPMA_ADAS
 SG_ PassRstrnInd_Req : 31|2@0+ (1,0) [0|3] "SED" Vector__XXX

BO_ 65 Global_PATS_Cntrl_Info_FD1: 8 GWM
 SG_ immoControlData_T1 : 15|40@0+ (1,0) [0|1099511627775] "Encrypted"  ECM_Diesel,PCM,PCM_HEV
 SG_ immoControlCmd_T1 : 7|3@0+ (1,0) [0|7] "SED"  ECM_Diesel,PCM,PCM_HEV

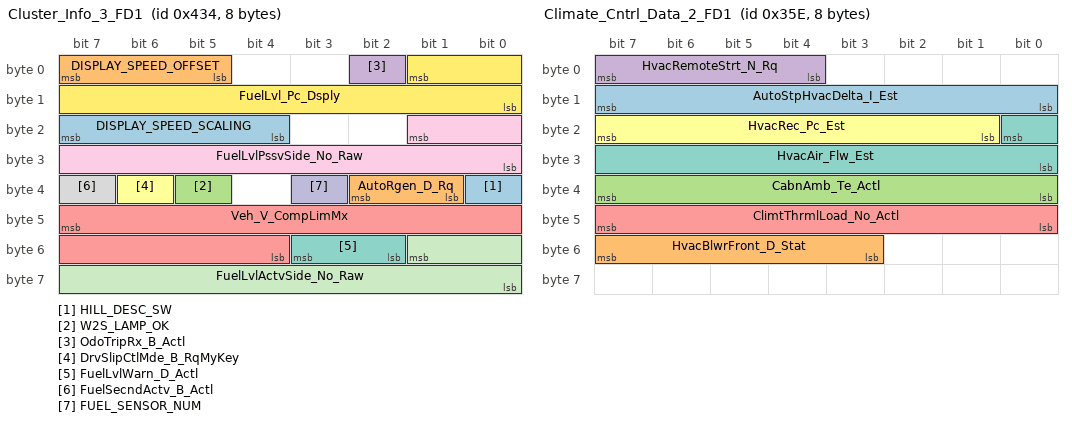
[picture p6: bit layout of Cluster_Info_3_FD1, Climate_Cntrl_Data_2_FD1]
BO_ 1076 Cluster_Info_3_FD1: 8 GWM
 SG_ HILL_DESC_SW : 32|1@0+ (1,0) [0|1] "SED"  ABS_ESC
 SG_ AutoRgen_D_Rq : 34|2@0+ (1,0) [0|3] "SED"  ECM_Diesel
 SG_ W2S_LAMP_OK : 37|1@0+ (1,0) [0|1] "SED" Vector__XXX
 SG_ OdoTripRx_B_Actl : 2|1@0+ (1,0) [0|1] "SED"  ECM_Diesel,PCM,PCM_HEV
 SG_ Veh_V_CompLimMx : 47|12@0+ (0.1,0) [0|409.5] "km/h"  ECM_Diesel,PCM,PCM_HEV
 SG_ DrvSlipCtlMde_B_RqMyKey : 38|1@0+ (1,0) [0|1] "SED"  ABS_ESC
 SG_ FuelLvlWarn_D_Actl : 51|2@0+ (1,0) [0|3] "SED" Vector__XXX
 SG_ FuelSecndActv_B_Actl : 39|1@0+ (1,0) [0|1] "SED" Vector__XXX
 SG_ FuelLvlPssvSide_No_Raw : 17|10@0+ (1,0) [0|1023] "Unitless"  ECM_Diesel,PCM,PCM_HEV
 SG_ FUEL_SENSOR_NUM : 35|1@0+ (1,0) [0|1] "SED"  ECM_Diesel,PCM,PCM_HEV
 SG_ FuelLvlActvSide_No_Raw : 49|10@0+ (1,0) [0|1023] "Unitless"  ECM_Diesel,PCM,PCM_HEV
 SG_ FuelLvl_Pc_Dsply : 1|10@0+ (0.108696,-5.217408) [-5.217408|105.9786] "Percent"  VDM,ECM_Diesel
 SG_ DISPLAY_SPEED_SCALING : 23|4@0+ (0.5,100) [100|107.5] "%"  IPMA_ADAS,ECM_Diesel,PCM,PCM_HEV
 SG_ DISPLAY_SPEED_OFFSET : 7|3@0+ (0.5,0) [0|3.5] "kph"  IPMA_ADAS,ECM_Diesel,PCM,PCM_HEV

BO_ 862 Climate_Cntrl_Data_2_FD1: 8 GWM
 SG_ AutoStpHvacDelta_I_Est : 15|8@0+ (1,-192) [-192|62] "ampere" Vector__XXX
 SG_ HvacBlwrFront_D_Stat : 55|5@0+ (1,0) [0|31] "SED"  ECM_Diesel,PCM,PCM_HEV
 SG_ CabnAmb_Te_Actl : 39|8@0+ (0.5,-57) [-57|70] "degreesC"  SOBDMC_HPCM_FD1,PCM_HEV
 SG_ HvacRemoteStrt_N_Rq : 7|4@0+ (100,450) [450|1950] "RPM"  ECM_Diesel,PCM,PCM_HEV
 SG_ ClimtThrmlLoad_No_Actl : 47|8@0+ (1,0) [0|254] "unitless"  SOBDMC_HPCM_FD1,PCM_HEV
 SG_ HvacRec_Pc_Est : 23|7@0+ (1,0) [0|127] "Percent"  PCM_HEV,SOBDMC_HPCM_FD1
 SG_ HvacAir_Flw_Est : 16|9@0+ (0.5,0) [0|255.5] "liter/second"  PCM_HEV,SOBDMC_HPCM_FD1

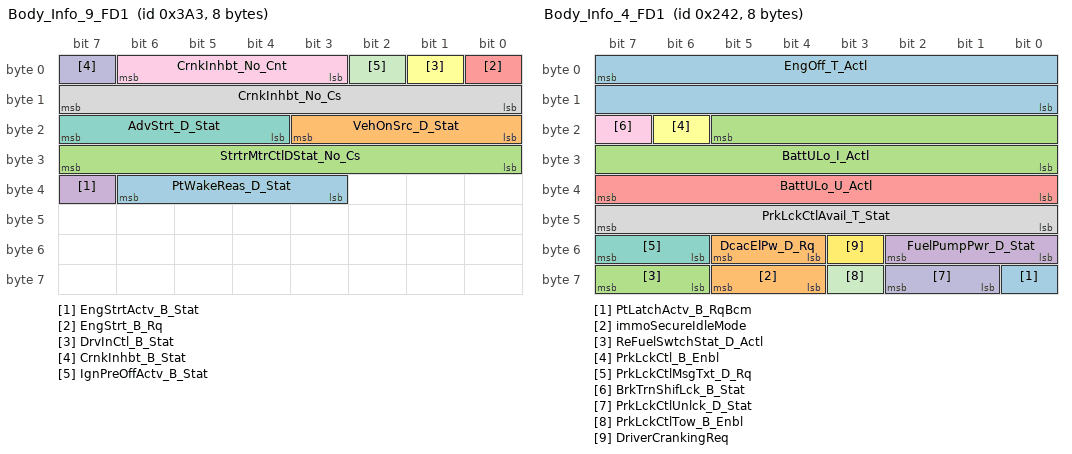
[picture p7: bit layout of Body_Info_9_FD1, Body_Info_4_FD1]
BO_ 931 Body_Info_9_FD1: 8 GWM
 SG_ PtWakeReas_D_Stat : 38|4@0+ (1,0) [0|15] "SED"  PCM_HEV
 SG_ VehOnSrc_D_Stat : 19|4@0+ (1,0) [0|15] "SED"  SOBDMC_HPCM_FD1,ABS_ESC,PCM_HEV,ECM_Diesel,PCM
 SG_ StrtrMtrCtlDStat_No_Cs : 31|8@0+ (1,0) [0|255] "unitless"  SOBDMC_HPCM_FD1,PCM_HEV,ECM_Diesel,PCM
 SG_ EngStrtActv_B_Stat : 39|1@0+ (1,0) [0|1] "SED"  SOBDMC_HPCM_FD1,PCM_HEV,ECM_Diesel,PCM
 SG_ EngStrt_B_Rq : 0|1@0+ (1,0) [0|1] "SED"  SOBDMC_HPCM_FD1,PCM_HEV,ECM_Diesel,PCM
 SG_ DrvInCtl_B_Stat : 1|1@0+ (1,0) [0|1] "SED"  SOBDMC_HPCM_FD1,ECM_Diesel,PCM,PCM_HEV
 SG_ AdvStrt_D_Stat : 23|4@0+ (1,0) [0|15] "SED"  SOBDMC_HPCM_FD1,PCM_HEV,ECM_Diesel,PCM
 SG_ CrnkInhbt_No_Cs : 15|8@0+ (1,0) [0|255] "Unitless"  ECM_Diesel,PCM,PCM_HEV
 SG_ CrnkInhbt_No_Cnt : 6|4@0+ (1,0) [0|15] "Unitless"  SOBDMC_HPCM_FD1,ECM_Diesel,PCM,PCM_HEV
 SG_ CrnkInhbt_B_Stat : 7|1@0+ (1,0) [0|1] "SED"  SOBDMC_HPCM_FD1,ECM_Diesel,PCM,PCM_HEV
 SG_ IgnPreOffActv_B_Stat : 2|1@0+ (1,0) [0|1] "SED"  PCM,PCM_HEV,TCM_DSL

BO_ 578 Body_Info_4_FD1: 8 GWM
 SG_ PtLatchActv_B_RqBcm : 56|1@0+ (1,0) [0|1] "SED"  ECM_Diesel,PCM,PCM_HEV,TCM_DSL
 SG_ immoSecureIdleMode : 61|2@0+ (1,0) [0|3] "SED"  ECM_Diesel,PCM,PCM_HEV
 SG_ ReFuelSwtchStat_D_Actl : 63|2@0+ (1,0) [0|3] "SED" Vector__XXX
 SG_ FuelPumpPwr_D_Stat : 50|3@0+ (1,0) [0|7] "SED"  ECM_Diesel,PCM,PCM_HEV
 SG_ BattULo_U_Actl : 39|8@0+ (0.0625,0) [0|15.875] "volt"  CMR_DSMC,SOBDMC_HPCM_FD1,ABS_ESC,IPMA_ADAS,PSCM,ECM_Diesel,PCM,PCM_HEV
 SG_ PrkLckCtl_B_Enbl : 22|1@0+ (1,0) [0|1] "SED" Vector__XXX
 SG_ PrkLckCtlMsgTxt_D_Rq : 55|2@0+ (1,0) [0|3] "SED" Vector__XXX
 SG_ PrkLckCtlAvail_T_Stat : 47|8@0+ (1,0) [0|255] "second" Vector__XXX
 SG_ BrkTrnShifLck_B_Stat : 23|1@0+ (1,0) [0|1] "SED"  PCM,PCM_HEV,TCM_DSL
 SG_ PrkLckCtlUnlck_D_Stat : 58|2@0+ (1,0) [0|3] "SED" Vector__XXX
 SG_ PrkLckCtlTow_B_Enbl : 59|1@0+ (1,0) [0|1] "SED" Vector__XXX
 SG_ DriverCrankingReq : 51|1@0+ (1,0) [0|1] "SED"  ECM_Diesel,PCM,PCM_HEV
 SG_ EngOff_T_Actl : 7|16@0+ (1,0) [0|65534] "second^0.5"  ABS_ESC,IPMA_ADAS,TCCM,ECM_Diesel,PCM,PCM_HEV,TCM_DSL
 SG_ DcacElPw_D_Rq : 53|2@0+ (1,0) [0|3] "SED"  ECM_Diesel,PCM
 SG_ BattULo_I_Actl : 21|14@0+ (0.0625,-512) [-512|511.875] "ampere"  ECM_Diesel,PCM,PCM_HEV

BO_ 947 BodyInfo_3_FD1: 8 GWM
 SG_ ValetMode_D_Mem : 16|1@0+ (1,0) [0|1] "SED" Vector__XXX
 SG_ DimmingLvlEvnt_No_Actl : 18|2@0+ (1,0) [0|3] "unitless" Vector__XXX
 SG_ DrStatDrvErrCnt_B_Stat : 19|1@0+ (1,0) [0|1] "SED"  ECM_Diesel,PCM,PCM_HEV
 SG_ TurnLghtRight_D_Rq : 63|2@0+ (1,0) [0|3] "SED"  CMR_DSMC,IPMA_ADAS
 SG_ TurnLghtRightOn_B_Stat : 35|1@0+ (1,0) [0|1] "SED" Vector__XXX
 SG_ TurnLghtLeftOn_B_Stat : 54|1@0+ (1,0) [0|1] "SED" Vector__XXX
 SG_ FogLghtRearOn_B_Stat : 1|1@0+ (1,0) [0|1] "SED"  IPMA_ADAS
 SG_ Backlit_LED_Status : 23|4@0+ (1,0) [0|15] "SED" Vector__XXX
 SG_ TurnLghtLeft_D_Rq : 9|2@0+ (1,0) [0|3] "SED"  CMR_DSMC,IPMA_ADAS
 SG_ FogLghtFrontOn_B_Stat : 56|1@0+ (1,0) [0|1] "SED"  IPMA_ADAS
 SG_ IgnKeyType_D_Actl : 39|4@0+ (1,0) [0|15] "SED"  ABS_ESC,ECM_Diesel,IPMA_ADAS,PCM,PCM_HEV
 SG_ Parklamp_Status : 3|2@0+ (1,0) [0|3] "SED"  IPMA_ADAS
 SG_ Litval : 47|8@0+ (1,0) [0|253] "SED"  IPMA_ADAS
 SG_ Key_In_Ignition_Stat : 11|1@0+ (1,0) [0|1] "SED"  ABS_ESC
 SG_ Ignition_Status : 7|4@0+ (1,0) [0|15] "SED"  VDM,CMR_DSMC,SOBDMC_HPCM_FD1,ABS_ESC,ECM_Diesel,IPMA_ADAS,PCM,PCM_HEV,PSCM,TCCM,TCM_DSL
 SG_ Dimming_Lvl : 31|8@0+ (1,0) [0|253] "SED"  IPMA_ADAS
 SG_ Day_Night_Status : 15|2@0+ (1,0) [0|3] "SED"  CMR_DSMC,ECM_Diesel,IPMA_ADAS,PCM
 SG_ Remote_Start_Status : 13|2@0+ (1,0) [0|3] "SED"  CMR_DSMC,IPMA_ADAS
 SG_ DrStatTgate_B_Actl : 0|1@0+ (1,0) [0|1] "SED"  IPMA_ADAS
 SG_ DrStatRr_B_Actl : 49|1@0+ (1,0) [0|1] "SED"  ABS_ESC,IPMA_ADAS
 SG_ DrStatRl_B_Actl : 48|1@0+ (1,0) [0|1] "SED"  ABS_ESC,IPMA_ADAS
 SG_ DrStatPsngr_B_Actl : 60|1@0+ (1,0) [0|1] "SED"  CMR_DSMC,ABS_ESC,IPMA_ADAS
 SG_ DrStatInnrTgate_B_Actl : 58|1@0+ (1,0) [0|1] "SED"  IPMA_ADAS
 SG_ DrStatHood_B_Actl : 59|1@0+ (1,0) [0|1] "SED" Vector__XXX
 SG_ DrStatDrv_B_Actl : 61|1@0+ (1,0) [0|1] "SED"  CMR_DSMC,ABS_ESC,ECM_Diesel,IPMA_ADAS,PCM,PCM_HEV,TCCM
 SG_ PrkBrkActv_B_Actl : 55|1@0+ (1,0) [0|1] "SED"  ABS_ESC,ECM_Diesel,IPMA_ADAS,PCM,PCM_HEV,TCCM,TCM_DSL
 SG_ LifeCycMde_D_Actl : 53|4@0+ (1,0) [0|15] "SED"  VDM,SOBDMC_HPCM_FD1,ABS_ESC,ECM_Diesel,IPMA_ADAS,PCM,PCM_HEV,PSCM,TCM_DSL
 SG_ Delay_Accy : 57|1@0+ (1,0) [0|1] "SED" Vector__XXX
 SG_ CrashEvnt_D_Stat : 34|2@0+ (1,0) [0|3] "SED" Vector__XXX
 SG_ FuelPmpInhbt_B_Stat : 32|1@0+ (1,0) [0|1] "SED" Vector__XXX
 SG_ BodySrvcRqd_B_Rq : 10|1@0+ (1,0) [0|1] "SED" Vector__XXX

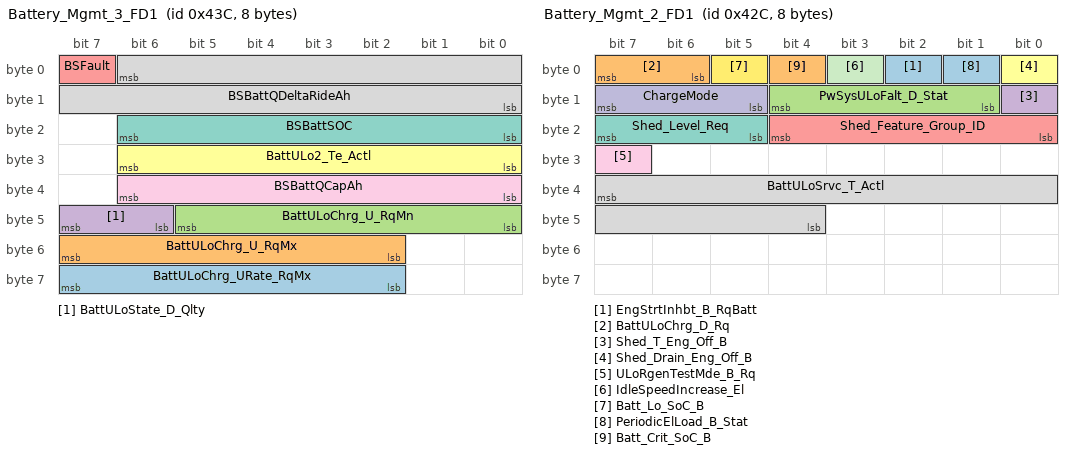
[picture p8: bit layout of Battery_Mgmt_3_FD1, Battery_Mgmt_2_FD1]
BO_ 1084 Battery_Mgmt_3_FD1: 8 GWM
 SG_ BattULoChrg_URate_RqMx : 63|6@0+ (0.1,0) [0|6.3] "volts/second"  ECM_Diesel,PCM,PCM_HEV
 SG_ BattULoChrg_U_RqMx : 55|6@0+ (0.1,10.6) [10.6|16.9] "volt"  ECM_Diesel,PCM,PCM_HEV
 SG_ BattULoChrg_U_RqMn : 45|6@0+ (0.1,10.6) [10.6|16.9] "volt"  ECM_Diesel,PCM,PCM_HEV
 SG_ BattULoState_D_Qlty : 47|2@0+ (1,0) [0|3] "SED"  ECM_Diesel,PCM,PCM_HEV
 SG_ BSFault : 7|1@0+ (1,0) [0|1] "SED"  ECM_Diesel,PCM,PCM_HEV
 SG_ BattULo2_Te_Actl : 30|7@0+ (1,-40) [-40|86] "degC"  ECM_Diesel,PCM,PCM_HEV
 SG_ BSBattSOC : 22|7@0+ (1,0) [0|127] "%"  ECM_Diesel,PCM,PCM_HEV
 SG_ BSBattQDeltaRideAh : 6|15@0+ (0.0078125,-100) [-100|155.9921875] "ampere*hour"  ECM_Diesel,PCM,PCM_HEV
 SG_ BSBattQCapAh : 38|7@0+ (1,0) [0|127] "ampere*hour"  ECM_Diesel,PCM,PCM_HEV

BO_ 1068 Battery_Mgmt_2_FD1: 8 GWM
 SG_ EngStrtInhbt_B_RqBatt : 2|1@0+ (1,0) [0|1] "SED"  ECM_Diesel,PCM
 SG_ BattULoChrg_D_Rq : 7|2@0+ (1,0) [0|3] "SED"  ECM_Diesel,PCM
 SG_ PwSysULoFalt_D_Stat : 12|4@0+ (1,0) [0|15] "SED" Vector__XXX
 SG_ Shed_T_Eng_Off_B : 8|1@0+ (1,0) [0|1] "SED" Vector__XXX
 SG_ Shed_Feature_Group_ID : 20|5@0+ (1,0) [0|31] "SED"  ECM_Diesel,PCM,PCM_HEV,IPMA_ADAS
 SG_ Shed_Drain_Eng_Off_B : 0|1@0+ (1,0) [0|1] "SED" Vector__XXX
 SG_ Shed_Level_Req : 23|3@0+ (1,0) [0|7] "SED"  ECM_Diesel,PCM,PCM_HEV,IPMA_ADAS
 SG_ BattULoSrvc_T_Actl : 39|12@0+ (1,0) [0|4095] "days" Vector__XXX
 SG_ ULoRgenTestMde_B_Rq : 31|1@0+ (1,0) [0|1] "SED"  ECM_Diesel,PCM
 SG_ ChargeMode : 15|3@0+ (1,0) [0|7] "SED"  ECM_Diesel,PCM
 SG_ IdleSpeedIncrease_El : 3|1@0+ (1,0) [0|1] "SED" Vector__XXX
 SG_ Batt_Lo_SoC_B : 5|1@0+ (1,0) [0|1] "SED" Vector__XXX
 SG_ PeriodicElLoad_B_Stat : 1|1@0+ (1,0) [0|1] "SED"  ECM_Diesel
 SG_ Batt_Crit_SoC_B : 4|1@0+ (1,0) [0|1] "SED" Vector__XXX

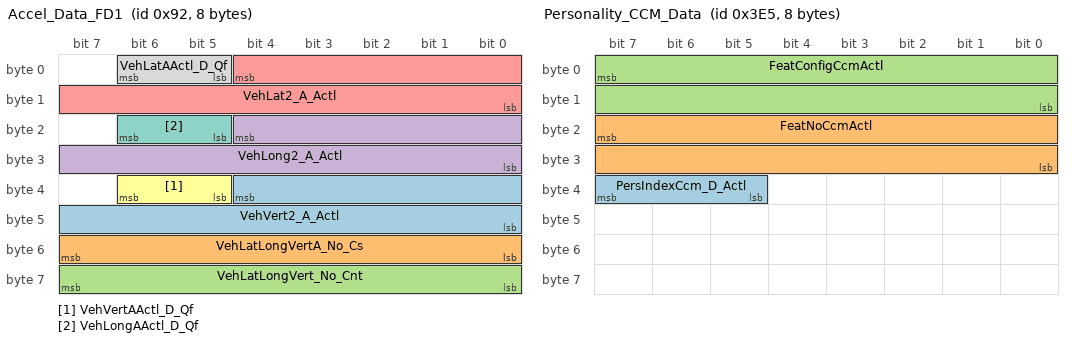
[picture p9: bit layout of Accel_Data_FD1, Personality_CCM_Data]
BO_ 146 Accel_Data_FD1: 8 GWM
 SG_ VehVert2_A_Actl : 36|13@0+ (0.01,-40) [-40|41.89] "m/s^2"  VDM,TCCM,IPMA_ADAS,ABS_ESC,ECM_Diesel
 SG_ VehLatLongVertA_No_Cs : 55|8@0+ (1,0) [0|255] "Unitless"  TCCM,IPMA_ADAS,ABS_ESC
 SG_ VehLatLongVert_No_Cnt : 63|8@0+ (1,0) [0|255] "Unitless"  VDM,TCCM,IPMA_ADAS,ABS_ESC
 SG_ VehLong2_A_Actl : 20|13@0+ (0.01,-40) [-40|41.89] "m/s^2"  VDM,TCCM,ABS_ESC,ECM_Diesel,IPMA_ADAS
 SG_ VehLat2_A_Actl : 4|13@0+ (0.01,-40) [-40|41.89] "m/s^2"  VDM,TCCM,ABS_ESC,ECM_Diesel,IPMA_ADAS
 SG_ VehVertAActl_D_Qf : 38|2@0+ (1,0) [0|3] "SED"  VDM,TCCM,IPMA_ADAS,ABS_ESC
 SG_ VehLongAActl_D_Qf : 22|2@0+ (1,0) [0|3] "SED"  IPMA_ADAS,VDM,TCCM,ABS_ESC,ECM_Diesel
 SG_ VehLatAActl_D_Qf : 6|2@0+ (1,0) [0|3] "SED"  IPMA_ADAS,VDM,TCCM,ABS_ESC

BO_ 1900 TesterPhysicalResCCM: 64 IPMA_ADAS
 SG_ TesterPhysicalResCCM : 7|64@0+ (1,0) [0|1.84467E+019] "unitless"  TSTR

BO_ 1806 TesterPhysicalResIPMA: 64 IPMA_ADAS
 SG_ TesterPhysicalResIPMA : 7|64@0+ (1,0) [0|1.84467E+019] "unitless"  TSTR

BO_ 997 Personality_CCM_Data: 8 IPMA_ADAS
 SG_ PersIndexCcm_D_Actl : 39|3@0+ (1,0) [0|7] "SED"  GWM
 SG_ FeatNoCcmActl : 23|16@0+ (1,0) [0|65535] "Number"  GWM
 SG_ FeatConfigCcmActl : 7|16@0+ (1,0) [0|65535] "Undefined"  GWM

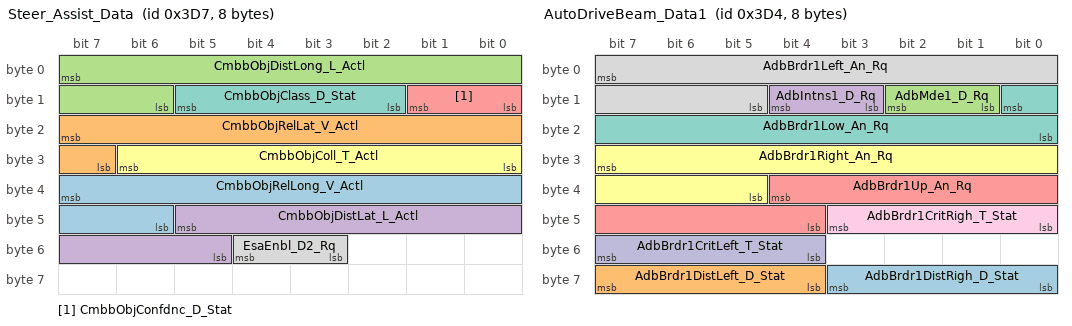
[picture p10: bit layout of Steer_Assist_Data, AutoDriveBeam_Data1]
BO_ 983 Steer_Assist_Data: 8 IPMA_ADAS
 SG_ CmbbObjRelLong_V_Actl : 39|10@0+ (0.1,-102.1) [-102.1|0] "meters/sec"  PSCM
 SG_ CmbbObjRelLat_V_Actl : 23|9@0+ (0.1,-25.5) [-25.5|25.4] "meters/sec"  PSCM
 SG_ CmbbObjDistLong_L_Actl : 7|10@0+ (0.1,0) [0|102.1] "meter"  PSCM
 SG_ CmbbObjDistLat_L_Actl : 45|9@0+ (0.1,-25.5) [-25.5|25.4] "meter"  PSCM
 SG_ CmbbObjConfdnc_D_Stat : 9|2@0+ (1,0) [0|3] "SED"  PSCM
 SG_ CmbbObjColl_T_Actl : 30|7@0+ (0.05,0) [0|6.25] "second"  PSCM
 SG_ CmbbObjClass_D_Stat : 13|4@0+ (1,0) [0|15] "SED"  PSCM
 SG_ EsaEnbl_D2_Rq : 52|2@0+ (1,0) [0|3] "SED"  PSCM

BO_ 980 AutoDriveBeam_Data1: 8 IPMA_ADAS
 SG_ AdbBrdr1DistRigh_D_Stat : 59|4@0+ (1,0) [0|15] "SED"  GWM
 SG_ AdbBrdr1DistLeft_D_Stat : 63|4@0+ (1,0) [0|15] "SED"  GWM
 SG_ AdbMde1_D_Rq : 10|2@0+ (1,0) [0|3] "SED"  GWM
 SG_ AdbIntns1_D_Rq : 12|2@0+ (1,0) [0|3] "SED"  GWM
 SG_ AdbBrdr1Up_An_Rq : 36|9@0+ (0.02,-8) [-8|2.18] "degrees"  GWM
 SG_ AdbBrdr1Right_An_Rq : 31|11@0+ (0.02,-20) [-20|20.9] "degrees"  GWM
 SG_ AdbBrdr1Low_An_Rq : 8|9@0+ (0.02,-8) [-8|2.18] "degrees"  GWM
 SG_ AdbBrdr1Left_An_Rq : 7|11@0+ (0.02,-20) [-20|20.9] "degrees"  GWM
 SG_ AdbBrdr1CritRigh_T_Stat : 43|4@0+ (100,0) [0|1500] "millisecond"  GWM
 SG_ AdbBrdr1CritLeft_T_Stat : 55|4@0+ (100,0) [0|1500] "millisecond"  GWM

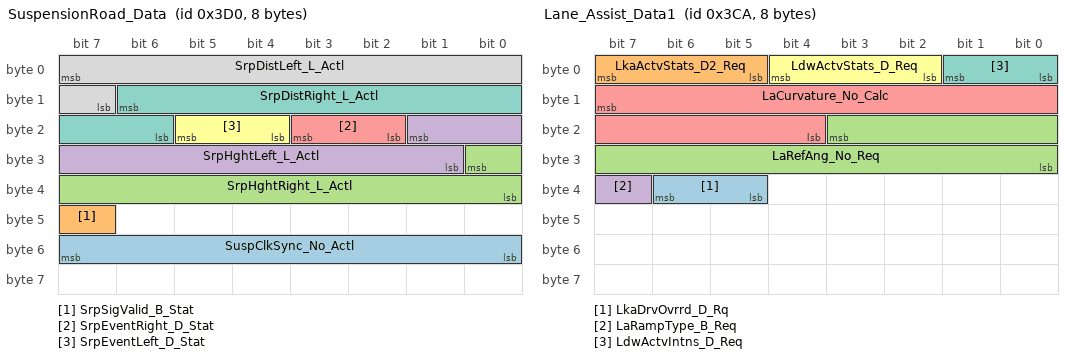
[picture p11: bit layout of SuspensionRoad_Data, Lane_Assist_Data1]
BO_ 976 SuspensionRoad_Data: 8 IPMA_ADAS
 SG_ SuspClkSync_No_Actl : 55|8@0+ (1,0) [0|253] "unitless"  GWM
 SG_ SrpSigValid_B_Stat : 47|1@0+ (1,0) [0|1] "SED"  GWM
 SG_ SrpHghtRight_L_Actl : 24|9@0+ (0.000625,-0.16) [-0.16|0.158125] "meter"  GWM
 SG_ SrpHghtLeft_L_Actl : 17|9@0+ (0.000625,-0.16) [-0.16|0.158125] "meter"  GWM
 SG_ SrpEventRight_D_Stat : 19|2@0+ (1,0) [0|3] "SED"  GWM
 SG_ SrpEventLeft_D_Stat : 21|2@0+ (1,0) [0|3] "SED"  GWM
 SG_ SrpDistRight_L_Actl : 14|9@0+ (0.02,0) [0|10.18] "meter"  GWM
 SG_ SrpDistLeft_L_Actl : 7|9@0+ (0.02,0) [0|10.18] "meter"  GWM

BO_ 973 Traffic_RecognitnData: 8 IPMA_ADAS
 SG_ LaSysOffStat_D_Dsply : 58|2@0+ (1,0) [0|3] "SED"  GWM
 SG_ TsrVl2PrmntMsgTxt_D_Rq : 60|2@0+ (1,0) [0|3] "SED"  GWM
 SG_ TsrVl1PrmntMsgTxt_D_Rq : 41|2@0+ (1,0) [0|3] "SED"  GWM
 SG_ TsrVl2RstrcMsgTxt2_D_Rq : 63|3@0+ (1,0) [0|7] "SED"  GWM
 SG_ TsrVl1RstrcMsgTxt2_D_Rq : 51|3@0+ (1,0) [0|7] "SED"  GWM
 SG_ TsrOvtkMsgTxt2_D_Rq : 55|4@0+ (1,0) [0|15] "SED"  GWM
 SG_ WwaWarn_B_Rq : 48|1@0+ (1,0) [0|1] "SED"  GWM
 SG_ TsrVlUnitMsgTxt_D_Rq : 43|2@0+ (1,0) [0|3] "SED"  GWM
 SG_ TsrVLim2MsgTxt_D_Rq : 39|8@0+ (1,0) [0|255] "SED"  GWM
 SG_ TsrVLim1MsgTxt_D_Rq : 31|8@0+ (1,0) [0|255] "SED"  GWM
 SG_ TsrVl2StatMsgTxt_D_Rq : 47|2@0+ (1,0) [0|3] "SED"  GWM
 SG_ TsrVl2RstrcMsgTxt_D_Rq : 17|2@0+ (1,0) [0|3] "SED"  GWM
 SG_ TsrVl1StatMsgTxt_D_Rq : 21|2@0+ (1,0) [0|3] "SED"  GWM
 SG_ TsrVl1RstrcMsgTxt_D_Rq : 23|2@0+ (1,0) [0|3] "SED"  GWM
 SG_ TsrStatMsgTxt_D_Rq : 10|3@0+ (1,0) [0|7] "SED"  GWM
 SG_ TsrOvtkStatMsgTxt_D_Rq : 1|2@0+ (1,0) [0|3] "SED"  GWM
 SG_ TsrOvtkMsgTxt_D_Rq : 15|3@0+ (1,0) [0|7] "SED"  GWM
 SG_ TsrOswWarnMsgTxt_D_Rq : 3|2@0+ (1,0) [0|3] "SED"  GWM
 SG_ TsrMsgTxt_D_Rq : 7|4@0+ (1,0) [0|15] "SED"  GWM

BO_ 970 Lane_Assist_Data1: 8 IPMA_ADAS
 SG_ LkaDrvOvrrd_D_Rq : 38|2@0+ (1,0) [0|3] "SED"  PSCM
 SG_ LkaActvStats_D2_Req : 7|3@0+ (1,0) [0|7] "SED"  PSCM
 SG_ LaRefAng_No_Req : 19|12@0+ (0.05,-102.4) [-102.4|102.3] "mrad"  PSCM
 SG_ LaRampType_B_Req : 39|1@0+ (1,0) [0|1] "SED"  PSCM
 SG_ LaCurvature_No_Calc : 15|12@0+ (5E-006,-0.01024) [-0.01024|0.01023] "1/m"  PSCM
 SG_ LdwActvStats_D_Req : 4|3@0+ (1,0) [0|7] "SED"  PSCM
 SG_ LdwActvIntns_D_Req : 1|2@0+ (1,0) [0|3] "SED"  PSCM

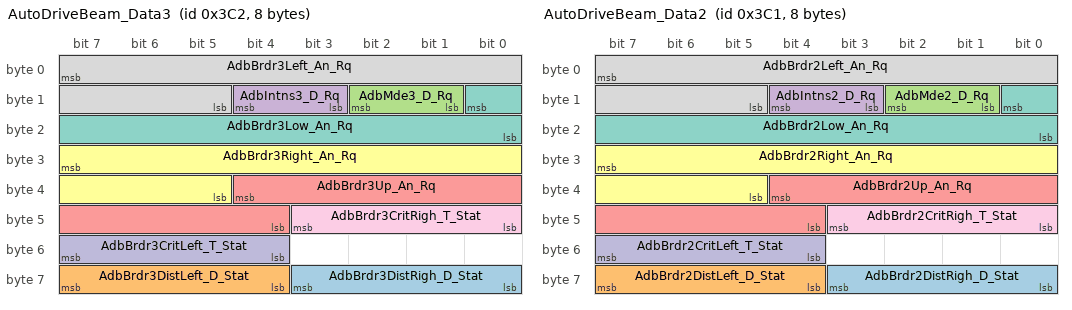
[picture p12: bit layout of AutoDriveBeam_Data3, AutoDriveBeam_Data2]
BO_ 962 AutoDriveBeam_Data3: 8 IPMA_ADAS
 SG_ AdbBrdr3DistRigh_D_Stat : 59|4@0+ (1,0) [0|15] "SED"  GWM
 SG_ AdbBrdr3DistLeft_D_Stat : 63|4@0+ (1,0) [0|15] "SED"  GWM
 SG_ AdbMde3_D_Rq : 10|2@0+ (1,0) [0|3] "SED"  GWM
 SG_ AdbIntns3_D_Rq : 12|2@0+ (1,0) [0|3] "SED"  GWM
 SG_ AdbBrdr3Up_An_Rq : 36|9@0+ (0.02,-8) [-8|2.18] "degrees"  GWM
 SG_ AdbBrdr3Right_An_Rq : 31|11@0+ (0.02,-20) [-20|20.9] "degrees"  GWM
 SG_ AdbBrdr3Low_An_Rq : 8|9@0+ (0.02,-8) [-8|2.18] "degrees"  GWM
 SG_ AdbBrdr3Left_An_Rq : 7|11@0+ (0.02,-20) [-20|20.9] "degrees"  GWM
 SG_ AdbBrdr3CritRigh_T_Stat : 43|4@0+ (100,0) [0|1500] "millisecond"  GWM
 SG_ AdbBrdr3CritLeft_T_Stat : 55|4@0+ (100,0) [0|1500] "millisecond"  GWM

BO_ 961 AutoDriveBeam_Data2: 8 IPMA_ADAS
 SG_ AdbBrdr2DistRigh_D_Stat : 59|4@0+ (1,0) [0|15] "SED"  GWM
 SG_ AdbBrdr2DistLeft_D_Stat : 63|4@0+ (1,0) [0|15] "SED"  GWM
 SG_ AdbMde2_D_Rq : 10|2@0+ (1,0) [0|3] "SED"  GWM
 SG_ AdbIntns2_D_Rq : 12|2@0+ (1,0) [0|3] "SED"  GWM
 SG_ AdbBrdr2Up_An_Rq : 36|9@0+ (0.02,-8) [-8|2.18] "degrees"  GWM
 SG_ AdbBrdr2Right_An_Rq : 31|11@0+ (0.02,-20) [-20|20.9] "degrees"  GWM
 SG_ AdbBrdr2Low_An_Rq : 8|9@0+ (0.02,-8) [-8|2.18] "degrees"  GWM
 SG_ AdbBrdr2Left_An_Rq : 7|11@0+ (0.02,-20) [-20|20.9] "degrees"  GWM
 SG_ AdbBrdr2CritRigh_T_Stat : 43|4@0+ (100,0) [0|1500] "millisecond"  GWM
 SG_ AdbBrdr2CritLeft_T_Stat : 55|4@0+ (100,0) [0|1500] "millisecond"  GWM

BO_ 394 ACCDATA_3: 8 IPMA_ADAS
 SG_ HaDsply_No_Cs : 63|8@0+ (1,0) [0|255] "Unitless"  GWM
 SG_ HaDsply_No_Cnt : 4|4@0+ (1,0) [0|15] "Unitless"  GWM
 SG_ AccStopStat_D_Dsply : 41|2@0+ (1,0) [0|3] "SED"  GWM
 SG_ AccTrgDist2_D_Dsply : 27|4@0+ (1,0) [0|15] "SED"  GWM
 SG_ AccStopRes_B_Dsply : 54|1@0+ (1,0) [0|1] "SED"  GWM
 SG_ TjaWarn_D_Rq : 50|3@0+ (1,0) [0|7] "SED"  GWM
 SG_ Tja_D_Stat : 44|3@0+ (1,0) [0|7] "SED"  CMR_DSMC,GWM
 SG_ TjaMsgTxt_D_Dsply : 53|3@0+ (1,0) [0|7] "SED"  GWM
 SG_ IaccLamp_D_Rq : 46|2@0+ (1,0) [0|3] "SED"  GWM
 SG_ AccMsgTxt_D2_Rq : 31|4@0+ (1,0) [0|15] "SED"  GWM
 SG_ FcwDeny_B_Dsply : 10|1@0+ (1,0) [0|1] "SED"  GWM
 SG_ FcwMemStat_B_Actl : 13|1@0+ (1,0) [0|1] "SED"  GWM
 SG_ AccTGap_B_Dsply : 35|1@0+ (1,0) [0|1] "SED"  GWM
 SG_ CadsAlignIncplt_B_Actl : 11|1@0+ (1,0) [0|1] "SED"  GWM
 SG_ AccFllwMde_B_Dsply : 17|1@0+ (1,0) [0|1] "SED"  GWM
 SG_ CadsRadrBlck_B_Actl : 22|1@0+ (1,0) [0|1] "SED"  GWM
 SG_ CmbbPostEvnt_B_Dsply : 15|1@0+ (1,0) [0|1] "SED"  GWM
 SG_ AccStopMde_B_Dsply : 0|1@0+ (1,0) [0|1] "SED"  GWM
 SG_ FcwMemSens_D_Actl : 20|2@0+ (1,0) [0|3] "SED"  GWM
 SG_ FcwMsgTxt_D_Rq : 7|3@0+ (1,0) [0|7] "SED"  GWM
 SG_ AccWarn_D_Dsply : 39|2@0+ (1,0) [0|3] "SED"  GWM
 SG_ FcwVisblWarn_B_Rq : 47|1@0+ (1,0) [0|1] "SED"  GWM
 SG_ FcwAudioWarn_B_Rq : 8|1@0+ (1,0) [0|1] "SED"  GWM
 SG_ AccTGap_D_Dsply : 34|3@0+ (1,0) [0|7] "SED"  GWM
 SG_ AccMemEnbl_B_RqDrv : 36|1@0+ (1,0) [0|1] "SED"  GWM

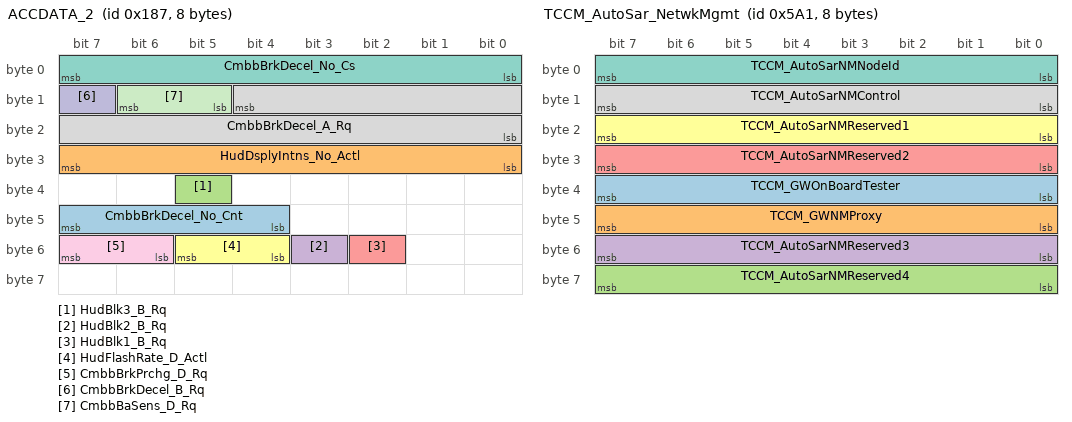
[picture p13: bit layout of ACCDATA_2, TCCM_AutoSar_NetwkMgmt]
BO_ 391 ACCDATA_2: 8 IPMA_ADAS
 SG_ CmbbBrkDecel_No_Cnt : 47|4@0+ (1,0) [0|15] "Unitless"  GWM,ABS_ESC
 SG_ HudDsplyIntns_No_Actl : 31|8@0+ (0.5,0) [0|100] "%"  GWM
 SG_ HudBlk3_B_Rq : 37|1@0+ (1,0) [0|1] "SED"  GWM
 SG_ HudBlk2_B_Rq : 51|1@0+ (1,0) [0|1] "SED"  GWM
 SG_ HudBlk1_B_Rq : 50|1@0+ (1,0) [0|1] "SED"  GWM
 SG_ HudFlashRate_D_Actl : 53|2@0+ (1,0) [0|3] "SED"  GWM
 SG_ CmbbBrkDecel_No_Cs : 7|8@0+ (1,0) [0|255] "Unitless"  GWM,ABS_ESC
 SG_ CmbbBrkDecel_A_Rq : 12|13@0+ (0.0039,-20) [-20|11.9449] "m/s^2"  ABS_ESC,GWM
 SG_ CmbbBrkPrchg_D_Rq : 55|2@0+ (1,0) [0|3] "SED"  ABS_ESC,GWM
 SG_ CmbbBrkDecel_B_Rq : 15|1@0+ (1,0) [0|1] "SED"  CMR_DSMC,ABS_ESC,GWM
 SG_ CmbbBaSens_D_Rq : 14|2@0+ (1,0) [0|3] "SED"  ABS_ESC,GWM

BO_ 390 ACCDATA: 8 IPMA_ADAS
 SG_ AccBrkPulse_B_Rq : 36|1@0+ (1,0) [0|1] "SED"  ABS_ESC,GWM
 SG_ AccAutoResum_D_Rq : 7|2@0+ (1,0) [0|3] "SED"  PCM_HEV,PCM,ECM_Diesel
 SG_ AccBrkTot_A_Rq : 4|13@0+ (0.0039,-20) [-20|11.9449] "m/s^2"  GWM,ABS_ESC
 SG_ AccPrpl_A_Pred : 17|10@0+ (0.01,-5) [-5|5.23] "m/s^2"  GWM,ECM_Diesel,PCM,PCM_HEV
 SG_ AccVeh_V_Trg : 32|9@0+ (0.5,0) [0|255.5] "kph"  GWM,ECM_Diesel,PCM,PCM_HEV,TCM_DSL
 SG_ AccBrkPrkEl_B_Rq : 38|1@0+ (1,0) [0|1] "SED"  GWM,ABS_ESC
 SG_ Cmbb_B_Enbl : 50|1@0+ (1,0) [0|1] "SED"  GWM
 SG_ CmbbOvrrd_B_RqDrv : 51|1@0+ (1,0) [0|1] "SED"  GWM
 SG_ CmbbDeny_B_Actl : 37|1@0+ (1,0) [0|1] "SED"  GWM,ABS_ESC
 SG_ CmbbEngTqMn_B_Rq : 52|1@0+ (1,0) [0|1] "SED"  ECM_Diesel,PCM,PCM_HEV,GWM
 SG_ AccPrpl_A_Rq : 49|10@0+ (0.01,-5) [-5|5.23] "m/s^2"  GWM,ECM_Diesel,PCM,PCM_HEV
 SG_ AccDeny_B_Rq : 53|1@0+ (1,0) [0|1] "SED"  GWM,ECM_Diesel,PCM,PCM_HEV
 SG_ AccResumEnbl_B_Rq : 33|1@0+ (1,0) [0|1] "SED"  GWM,ECM_Diesel,PCM,PCM_HEV
 SG_ AccCancl_B_Rq : 39|1@0+ (1,0) [0|1] "SED"  GWM,ABS_ESC,ECM_Diesel,PCM,PCM_HEV
 SG_ AccBrkPrchg_B_Rq : 54|1@0+ (1,0) [0|1] "SED"  GWM,ABS_ESC
 SG_ AccBrkDecel_B_Rq : 55|1@0+ (1,0) [0|1] "SED"  GWM,ABS_ESC
 SG_ AccStopStat_B_Rq : 34|1@0+ (1,0) [0|1] "SED"  GWM,ECM_Diesel,PCM,PCM_HEV,ABS_ESC

BO_ 1441 TCCM_AutoSar_NetwkMgmt: 8 TCCM
 SG_ TCCM_GWOnBoardTester : 39|8@0+ (1,0) [0|255] "unitless" Vector__XXX
 SG_ TCCM_GWNMProxy : 47|8@0+ (1,0) [0|255] "unitless" Vector__XXX
 SG_ TCCM_AutoSarNMReserved4 : 63|8@0+ (1,0) [0|255] "unitless" Vector__XXX
 SG_ TCCM_AutoSarNMReserved3 : 55|8@0+ (1,0) [0|255] "unitless" Vector__XXX
 SG_ TCCM_AutoSarNMReserved2 : 31|8@0+ (1,0) [0|255] "unitless" Vector__XXX
 SG_ TCCM_AutoSarNMReserved1 : 23|8@0+ (1,0) [0|255] "unitless" Vector__XXX
 SG_ TCCM_AutoSarNMNodeId : 7|8@0+ (1,0) [0|255] "unitless" Vector__XXX
 SG_ TCCM_AutoSarNMControl : 15|8@0+ (1,0) [0|255] "unitless" Vector__XXX

BO_ 1787 TesterPhysicalResSODCMD: 64 IPMA_ADAS
 SG_ TesterPhysicalResSODCMD : 7|64@0+ (1,0) [0|1.84467E+019] "unitless"  TSTR

BO_ 1779 TesterPhysicalReqSODCMD: 64 TSTR
 SG_ TesterPhysicalReqSODCMD : 7|64@0+ (1,0) [0|1.84467E+019] "unitless"  IPMA_ADAS

BO_ 1786 TesterPhysicalResSODCMC: 64 IPMA_ADAS
 SG_ TesterPhysicalResSODCMC : 7|64@0+ (1,0) [0|1.84467E+019] "unitless"  TSTR

BO_ 1778 TesterPhysicalReqSODCMC: 64 TSTR
 SG_ TesterPhysicalReqSODCMC : 7|64@0+ (1,0) [0|1.84467E+019] "unitless"  IPMA_ADAS

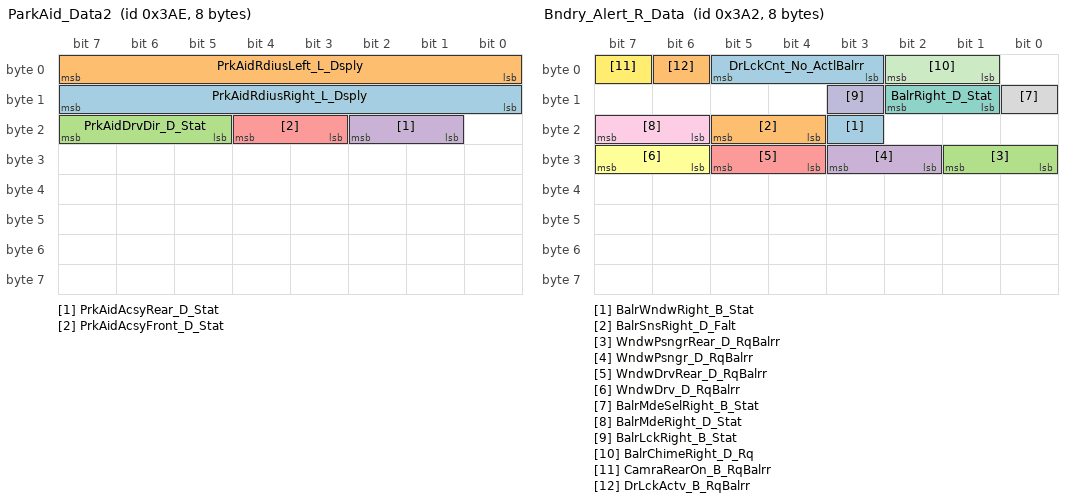
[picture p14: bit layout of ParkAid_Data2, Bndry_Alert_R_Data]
BO_ 942 ParkAid_Data2: 8 IPMA_ADAS
 SG_ PrkAidRdiusRight_L_Dsply : 15|8@0+ (1,0) [0|255] "unitless"  GWM
 SG_ PrkAidRdiusLeft_L_Dsply : 7|8@0+ (1,0) [0|255] "unitless"  GWM
 SG_ PrkAidDrvDir_D_Stat : 23|3@0+ (1,0) [0|7] "SED"  GWM
 SG_ PrkAidAcsyRear_D_Stat : 18|2@0+ (1,0) [0|3] "SED"  GWM
 SG_ PrkAidAcsyFront_D_Stat : 20|2@0+ (1,0) [0|3] "SED"  GWM

BO_ 930 Bndry_Alert_R_Data: 8 IPMA_ADAS
 SG_ BalrWndwRight_B_Stat : 19|1@0+ (1,0) [0|1] "SED"  GWM
 SG_ BalrSnsRight_D_Falt : 21|2@0+ (1,0) [0|3] "SED"  GWM
 SG_ WndwPsngrRear_D_RqBalrr : 25|2@0+ (1,0) [0|3] "SED"  GWM
 SG_ WndwPsngr_D_RqBalrr : 27|2@0+ (1,0) [0|3] "SED"  GWM
 SG_ WndwDrvRear_D_RqBalrr : 29|2@0+ (1,0) [0|3] "SED"  GWM
 SG_ WndwDrv_D_RqBalrr : 31|2@0+ (1,0) [0|3] "SED"  GWM
 SG_ BalrRight_D_Stat : 10|2@0+ (1,0) [0|3] "SED"  GWM
 SG_ BalrMdeSelRight_B_Stat : 8|1@0+ (1,0) [0|1] "SED"  GWM
 SG_ BalrMdeRight_D_Stat : 23|2@0+ (1,0) [0|3] "SED"  GWM
 SG_ BalrLckRight_B_Stat : 11|1@0+ (1,0) [0|1] "SED"  GWM
 SG_ BalrChimeRight_D_Rq : 2|2@0+ (1,0) [0|3] "SED"  GWM
 SG_ CamraRearOn_B_RqBalrr : 7|1@0+ (1,0) [0|1] "SED"  GWM
 SG_ DrLckCnt_No_ActlBalrr : 5|3@0+ (1,0) [0|7] "unitless"  GWM
 SG_ DrLckActv_B_RqBalrr : 6|1@0+ (1,0) [0|1] "SED"  GWM

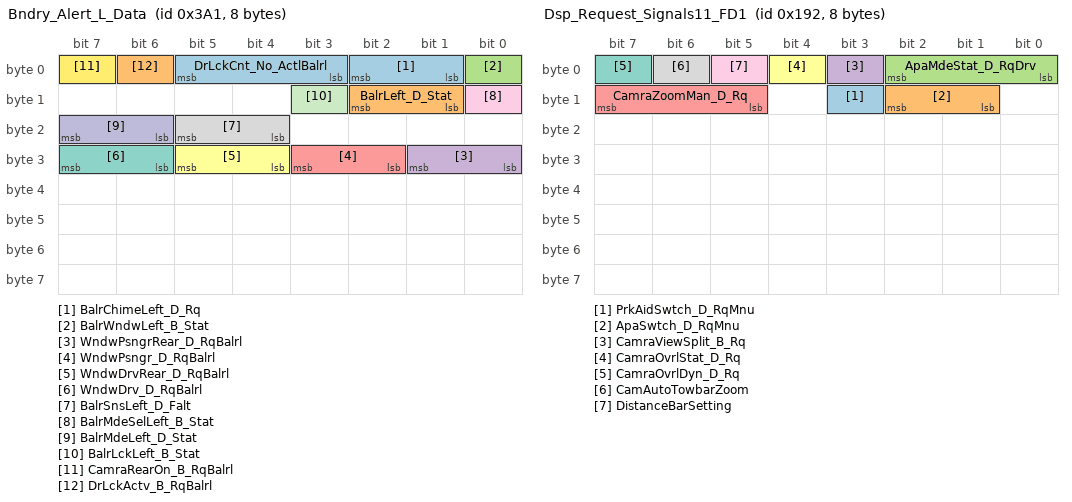
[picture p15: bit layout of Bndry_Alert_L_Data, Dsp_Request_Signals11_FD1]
BO_ 929 Bndry_Alert_L_Data: 8 IPMA_ADAS
 SG_ BalrChimeLeft_D_Rq : 2|2@0+ (1,0) [0|3] "SED"  GWM
 SG_ BalrLeft_D_Stat : 10|2@0+ (1,0) [0|3] "SED"  GWM
 SG_ BalrWndwLeft_B_Stat : 0|1@0+ (1,0) [0|1] "SED"  GWM
 SG_ WndwPsngrRear_D_RqBalrl : 25|2@0+ (1,0) [0|3] "SED"  GWM
 SG_ WndwPsngr_D_RqBalrl : 27|2@0+ (1,0) [0|3] "SED"  GWM
 SG_ WndwDrvRear_D_RqBalrl : 29|2@0+ (1,0) [0|3] "SED"  GWM
 SG_ WndwDrv_D_RqBalrl : 31|2@0+ (1,0) [0|3] "SED"  GWM
 SG_ BalrSnsLeft_D_Falt : 21|2@0+ (1,0) [0|3] "SED"  GWM
 SG_ BalrMdeSelLeft_B_Stat : 8|1@0+ (1,0) [0|1] "SED"  GWM
 SG_ BalrMdeLeft_D_Stat : 23|2@0+ (1,0) [0|3] "SED"  GWM
 SG_ BalrLckLeft_B_Stat : 11|1@0+ (1,0) [0|1] "SED"  GWM
 SG_ CamraRearOn_B_RqBalrl : 7|1@0+ (1,0) [0|1] "SED"  GWM
 SG_ DrLckCnt_No_ActlBalrl : 5|3@0+ (1,0) [0|7] "unitless"  GWM
 SG_ DrLckActv_B_RqBalrl : 6|1@0+ (1,0) [0|1] "SED"  GWM

BO_ 402 Dsp_Request_Signals11_FD1: 8 GWM
 SG_ PrkAidSwtch_D_RqMnu : 11|1@0+ (1,0) [0|1] "SED"  IPMA_ADAS
 SG_ ApaSwtch_D_RqMnu : 10|2@0+ (1,0) [0|3] "SED"  IPMA_ADAS
 SG_ ApaMdeStat_D_RqDrv : 2|3@0+ (1,0) [0|7] "SED"  IPMA_ADAS
 SG_ CamraViewSplit_B_Rq : 3|1@0+ (1,0) [0|1] "SED" Vector__XXX
 SG_ CamraZoomMan_D_Rq : 15|3@0+ (1,0) [0|7] "SED" Vector__XXX
 SG_ CamraOvrlStat_D_Rq : 4|1@0+ (1,0) [0|1] "SED" Vector__XXX
 SG_ CamraOvrlDyn_D_Rq : 7|1@0+ (1,0) [0|1] "SED" Vector__XXX
 SG_ CamAutoTowbarZoom : 6|1@0+ (1,0) [0|1] "SED" Vector__XXX
 SG_ DistanceBarSetting : 5|1@0+ (1,0) [0|1] "SED" Vector__XXX

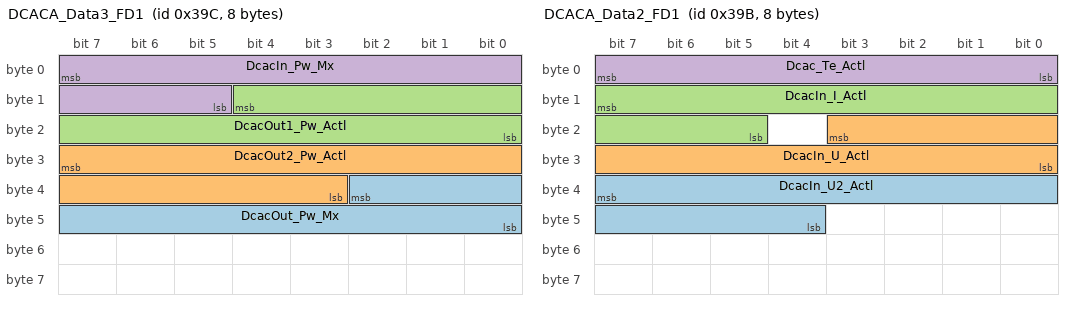
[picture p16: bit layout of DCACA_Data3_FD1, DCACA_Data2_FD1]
BO_ 924 DCACA_Data3_FD1: 8 GWM
 SG_ DcacOut_Pw_Mx : 34|11@0+ (5,0) [0|10225] "watts"  PCM,PCM_HEV
 SG_ DcacOut2_Pw_Actl : 31|13@0+ (1,0) [0|8189] "watts"  PCM_HEV
 SG_ DcacOut1_Pw_Actl : 12|13@0+ (1,0) [0|8189] "watts"  PCM,PCM_HEV
 SG_ DcacIn_Pw_Mx : 7|11@0+ (5,0) [0|10225] "watts"  PCM,PCM_HEV

BO_ 923 DCACA_Data2_FD1: 8 GWM
 SG_ DcacIn_U2_Actl : 39|12@0+ (0.01,0) [0|40.93] "volt"  PCM
 SG_ DcacIn_U_Actl : 19|12@0+ (0.1,0) [0|409.3] "volt"  SOBDMC_HPCM_FD1,PCM,PCM_HEV
 SG_ DcacIn_I_Actl : 15|11@0+ (0.1,0) [0|204.5] "Amps"  SOBDMC_HPCM_FD1,PCM,PCM_HEV
 SG_ Dcac_Te_Actl : 7|8@0+ (1,-60) [-60|193] "degC"  PCM

BO_ 1998 TesterPhysicalResSODR: 64 IPMA_ADAS
 SG_ TesterPhysicalResSODR : 7|64@0+ (1,0) [0|1.84467E+019] "unitless"  TSTR

BO_ 1996 TesterPhysicalResSODL: 64 IPMA_ADAS
 SG_ TesterPhysicalResSODL : 7|64@0+ (1,0) [0|1.84467E+019] "unitless"  TSTR

BO_ 1988 TesterPhysicalReqSODL: 64 TSTR
 SG_ TesterPhysicalReqSODL : 7|64@0+ (1,0) [0|1.84467E+019] "unitless"  IPMA_ADAS

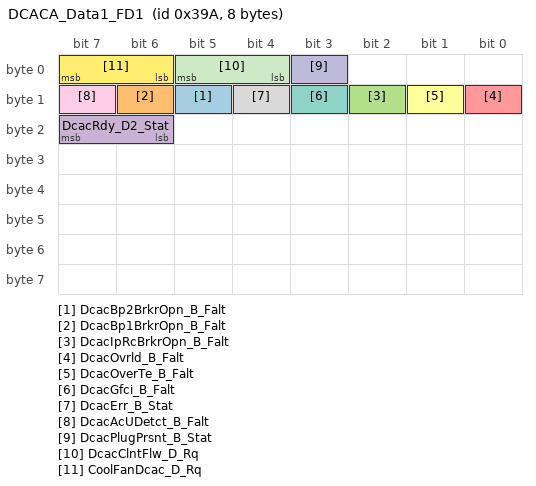
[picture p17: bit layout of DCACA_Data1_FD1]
BO_ 922 DCACA_Data1_FD1: 8 GWM
 SG_ DcacBp2BrkrOpn_B_Falt : 13|1@0+ (1,0) [0|1] "SED"  PCM,PCM_HEV
 SG_ DcacBp1BrkrOpn_B_Falt : 14|1@0+ (1,0) [0|1] "SED"  PCM,PCM_HEV
 SG_ DcacIpRcBrkrOpn_B_Falt : 10|1@0+ (1,0) [0|1] "SED"  PCM,PCM_HEV
 SG_ DcacRdy_D2_Stat : 23|2@0+ (1,0) [0|3] "SED"  PCM,PCM_HEV
 SG_ DcacOvrld_B_Falt : 8|1@0+ (1,0) [0|1] "SED"  PCM,PCM_HEV
 SG_ DcacOverTe_B_Falt : 9|1@0+ (1,0) [0|1] "SED"  PCM,PCM_HEV
 SG_ DcacGfci_B_Falt : 11|1@0+ (1,0) [0|1] "SED"  PCM,PCM_HEV
 SG_ DcacErr_B_Stat : 12|1@0+ (1,0) [0|1] "SED"  PCM,PCM_HEV
 SG_ DcacAcUDetct_B_Falt : 15|1@0+ (1,0) [0|1] "SED"  PCM,PCM_HEV
 SG_ DcacPlugPrsnt_B_Stat : 3|1@0+ (1,0) [0|1] "SED"  PCM,PCM_HEV
 SG_ DcacClntFlw_D_Rq : 5|2@0+ (1,0) [0|3] "SED"  SOBDMC_HPCM_FD1
 SG_ CoolFanDcac_D_Rq : 7|2@0+ (1,0) [0|3] "SED"  SOBDMC_HPCM_FD1

CM_ SG_ 90 TrnGsmNtmState_D_Actl "Signal not transmitted on vehicles that do not have shift by wire.";
CM_ SG_ 90 DrQltyDrv_D_StatGsm "Signal not transmitted on vehicles that do not have shift by wire.";
CM_ SG_ 90 TrnBtsiOvrrd_B_Stat "Signal not transmitted on vehicles that do not have shift by wire.";
CM_ SG_ 90 TrnValidGearRq_D_Stat "Signal not transmitted on vehicles that do not have shift by wire.";
CM_ SG_ 90 TrnGearRqCnt_B_Actl "Signal not transmitted on vehicles that do not have shift by wire.";
CM_ SG_ 90 TrnGearButtn_U_Actl "Signal not transmitted on vehicles that do not have shift by wire.";
CM_ SG_ 90 TrnGearButtn_B_ActlR2 "Signal not transmitted on vehicles that do not have shift by wire.";
CM_ SG_ 90 TrnGearButtn_B_ActlR1 "Signal not transmitted on vehicles that do not have shift by wire.";
CM_ SG_ 90 TrnGearButtn_B_ActlR0 "Signal not transmitted on vehicles that do not have shift by wire.";
CM_ SG_ 90 TrnGearButtn_B_ActlP2 "Signal not transmitted on vehicles that do not have shift by wire.";
CM_ SG_ 90 TrnGearButtn_B_ActlP1 "Signal not transmitted on vehicles that do not have shift by wire.";
CM_ SG_ 90 TrnGearButtn_B_ActlP0 "Signal not transmitted on vehicles that do not have shift by wire.";
CM_ SG_ 90 TrnGearButtn_B_ActlN2 "Signal not transmitted on vehicles that do not have shift by wire.";
CM_ SG_ 90 TrnGearButtn_B_ActlN1 "Signal not transmitted on vehicles that do not have shift by wire.";
CM_ SG_ 90 TrnGearButtn_B_ActlN0 "Signal not transmitted on vehicles that do not have shift by wire.";
CM_ SG_ 90 TrnGearButtn_B_ActlM2 "Signal not transmitted on vehicles that do not have shift by wire.";
CM_ SG_ 90 TrnGearButtn_B_ActlM1 "Signal not transmitted on vehicles that do not have shift by wire.";
CM_ SG_ 90 TrnGearButtn_B_ActlM0 "Signal not transmitted on vehicles that do not have shift by wire.";
CM_ SG_ 90 TrnGearButtn_B_ActlD2 "Signal not transmitted on vehicles that do not have shift by wire.";
CM_ SG_ 90 TrnGearButtn_B_ActlD1 "Signal not transmitted on vehicles that do not have shift by wire.";
CM_ SG_ 90 TrnGearButtn_B_ActlD0 "Signal not transmitted on vehicles that do not have shift by wire.";
CM_ SG_ 90 TrnGear_No_Cs "Signal not transmitted on vehicles that do not have shift by wire.";
CM_ SG_ 90 TrnGear_No_Cnt "Signal not transmitted on vehicles that do not have shift by wire.";
CM_ SG_ 90 TrnGear_D_RqDrv "Signal not transmitted on vehicles that do not have shift by wire.";
CM_ SG_ 90 BrkSwtchPos_B_ActlGsm "Signal not transmitted on vehicles that do not have shift by wire.";
CM_ SG_ 138 SteWhlRelCalib_An_Sns "Signal is not transmitted on vehicles where PSCM is transmitting the message that contains this signal.
Signal data set to 0x0 for ABS only vehicle option content";
CM_ SG_ 1093 StopLamp_B_RqTrlrBrk "Signal not transmitted on all variants.";
CM_ SG_ 792 ElTrip_L_Dsply "Key cycle trip distance driven with the engine off (Trip EV Miles)";
CM_ SG_ 792 ElLongTerm_L_Dsply "Long term distance distance driven with the engine off since the last long term reset (Long Term EV Miles).";
CM_ SG_ 765 Mc_VehTimeFrmtUsrSel_St "Object.BodyInterface.Settings.VehicleTimeFormatUserSelection";
CM_ SG_ 765 Mc_VehUntTrpCoUsrSel_St "Object.VehicleSettings.Disp_Miles_Kilometers.Rq";
CM_ SG_ 765 Mc_VehUnitTempUsrSel_St "Object.VehicleSettings.Disp_Temperature.Rq";
CM_ SG_ 765 Mc_VehLangUsrSel_St "Object.BodyInterface.Settings.VehicleLanguageUserSelection
Object Vehicle Settings.Disp_LangSel
";
CM_ BO_ 559 "APIM Tx";
CM_ BO_ 558 "APIM Tx";
CM_ SG_ 934 Side_Detect_L_Illum "DDMGenSigTimeoutTime=2000";
CM_ SG_ 934 SodLeft_D_Stat "IPCGenSigTimeoutTime=1600";
CM_ SG_ 934 SodSnsLeft_D_Stat "IPCGenSigTimeoutTime=1600";
CM_ SG_ 934 SodAlrtLeft_D_Stat "DDMGenSigTimeoutTime=2000";
CM_ SG_ 1072 MetricActv_B_Actl "0 =Inactive(English), 1=Active(Metric)";
CM_ SG_ 145 VehYaw_W_Actl "CCMGenSigTimeoutTime=1000";
CM_ BO_ 65 "Provide control function information to the target function of the Passive Anti-Theft Subsystem";
CM_ SG_ 931 CrnkInhbt_No_Cs "Signal not transmitted on gas and HEV variants.";
CM_ SG_ 931 CrnkInhbt_No_Cnt "Signal not transmitted on gas and HEV variants.";
CM_ SG_ 947 Dimming_Lvl "Refer to Vehicle Interior Illum Dimming Ctrl Sys Eng Spec, Table 2

";
CM_ SG_ 947 PrkBrkActv_B_Actl "Signal not transmitted on vehicles with electric park brake. ";
CM_ SG_ 394 HaDsply_No_Cs "Signal not transmitted on gas variants.";
CM_ SG_ 394 HaDsply_No_Cnt "Signal not transmitted on gas variants.";
CM_ SG_ 391 CmbbBrkDecel_A_Rq "ABSGenSigTimeoutTime=1000";
CM_ SG_ 391 CmbbBrkPrchg_D_Rq "ABSGenSigTimeoutTime=1000";
CM_ SG_ 391 CmbbBrkDecel_B_Rq "ABSGenSigTimeoutTime=1000";
CM_ SG_ 391 CmbbBaSens_D_Rq "ABSGenSigTimeoutTime=1000";
CM_ SG_ 390 AccBrkTot_A_Rq "ABSGenSigTimeoutTime=1000";
CM_ SG_ 390 AccBrkPrkEl_B_Rq "ABSGenSigTimeoutTime=1000";
CM_ SG_ 390 AccPrpl_A_Rq "PCMGenSigTimeoutTime=1000";
CM_ SG_ 390 AccBrkPrchg_B_Rq "ABSGenSigTimeoutTime=1000";
CM_ SG_ 390 AccBrkDecel_B_Rq "ABSGenSigTimeoutTime=1000";
CM_ SG_ 390 AccStopStat_B_Rq "ABSGenSigTimeoutTime=1000";
CM_ SG_ 942 PrkAidRdiusRight_L_Dsply "MSGDCR 679, set all signals to OnChange";
CM_ SG_ 942 PrkAidRdiusLeft_L_Dsply "MSGDCR 679, set all signals to OnChange";
CM_ SG_ 942 PrkAidDrvDir_D_Stat "MSGDCR 679, set all signals to OnChange";
CM_ BO_ 402 "FCDIM,APIM Tx";
BA_DEF_ SG_  "U_CD542_MY2021_Rx" ENUM  "No","Yes";
BA_DEF_ SG_  "U_CD542_MY2021_Tx" ENUM  "No","Yes";
BA_DEF_ SG_  "U_U55X_MY2022_Tx" ENUM  "No","Yes";
BA_DEF_ BO_  "OvtpPushApplication" ENUM  "FALSE","TRUE";
BA_DEF_ SG_  "ECGUsedRxSignal" ENUM  "No","Yes";
BA_DEF_ SG_  "ECGUsedTxSignal" ENUM  "No","Yes";
BA_DEF_ BO_  "VFrameFormat" ENUM  "StandardCAN","ExtendedCAN","reserved","reserved","reserved","reserved","reserved","reserved","reserved","reserved","reserved","reserved","reserved","reserved","StandardCAN_FD","ExtendedCAN_FD";
BA_DEF_ BO_  "FrameRouting" STRING ;
BA_DEF_ BO_  "FrameGatewayNetwork" STRING ;
BA_DEF_ BO_  "NetworkInitialization" ENUM  "No","Yes";
BA_DEF_ BO_  "FrameGatewayId" HEX 0 1407;
BA_DEF_ BO_  "EventRateOfChange" INT 10 10000;
BA_DEF_ BO_  "GenMsgStartDelayTime" INT 0 10000;
BA_DEF_ BO_  "GenMsgNrOfRepetition" INT 0 100;
BA_DEF_ BO_  "GenMsgDelayTime" INT 0 1000;
BA_DEF_ BO_  "GenMsgCycleTime" INT 0 100000;
BA_DEF_ BO_  "GenMsgSendType" ENUM  "FixedPeriodic","Event","EnabledPeriodic","NotUsed","NotUsed","EventPeriodic","NotUsed","NotUsed","NoMsgSendType";
BA_DEF_ SG_  "U_T6_MCA_MY2020_Tx" ENUM  "No","Yes";
BA_DEF_ SG_  "U_P702_MY2021_Tx" ENUM  "No","Yes";
BA_DEF_ SG_  "U_CX727_MY2021_Tx" ENUM  "No","Yes";
BA_DEF_ SG_  "U_T6_MCA_MY2020_Rx" ENUM  "No","Yes";
BA_DEF_ SG_  "U_P702_MY2021_Rx" ENUM  "No","Yes";
BA_DEF_ SG_  "U_CX727_MY2021_Rx" ENUM  "No","Yes";
BA_DEF_ SG_  "GenSigStartValue" HEX 0 268435455;
BA_DEF_ SG_  "MetaData" ENUM  "No","Yes";
BA_DEF_ SG_  "ContentDependant" ENUM  "No","Yes";
BA_DEF_ SG_  "GenSigStartValueInteger" INT 0 1000000000;
BA_DEF_ SG_  "UsedOnPgmDBC" ENUM  "No","Yes";
BA_DEF_ SG_  "CrossOver_InfoCAN" ENUM  "No","Yes";
BA_DEF_ SG_  "WakeupSignal" ENUM  "No","Yes";
BA_DEF_ SG_  "GenSigInactiveValue" INT 0 100000;
BA_DEF_ SG_  "GenSigSendType" ENUM  "Cyclic","OnWrite","vector_leerstring","OnChange","vector_leerstring","IfActive","vector_leerstring","NoSigSendType";
BA_DEF_ BO_  "SCP_FreshnessValueLength" INT 0 512;
BA_DEF_ BO_  "AuthFreshnessCounterSyncAttempt" INT 0 512;
BA_DEF_ BO_  "SCP_FreshnessValueTxLength" INT 0 512;
BA_DEF_ BO_  "SCP_AuthInfoTxLength" INT 0 512;
BA_DEF_ BO_  "ProgBWConditional" STRING ;
BA_DEF_ BO_  "NmAsrMessage" ENUM  "No","Yes";
BA_DEF_ BO_  "TpApplType" STRING ;
BA_DEF_ BO_  "DiagState" ENUM  "No","Yes";
BA_DEF_ BO_  "TpTxIndex" INT 0 536870911;
BA_DEF_ BO_  "DiagRequest" ENUM  "No","Yes";
BA_DEF_ BO_  "DiagResponse" ENUM  "No","Yes";
BA_DEF_ BO_  "GenMsgILSupport" ENUM  "No","Yes";
BA_DEF_DEF_  "U_CD542_MY2021_Rx" "No";
BA_DEF_DEF_  "U_CD542_MY2021_Tx" "No";
BA_DEF_DEF_  "U_U55X_MY2022_Tx" "No";
BA_DEF_DEF_  "OvtpPushApplication" "FALSE";
BA_DEF_DEF_  "ECGUsedRxSignal" "No";
BA_DEF_DEF_  "ECGUsedTxSignal" "No";
BA_DEF_DEF_  "VFrameFormat" "ExtendedCAN_FD";
BA_DEF_DEF_  "FrameRouting" "NONE";
BA_DEF_DEF_  "FrameGatewayNetwork" "NONE";
BA_DEF_DEF_  "NetworkInitialization" "Yes";
BA_DEF_DEF_  "FrameGatewayId" 0;
BA_DEF_DEF_  "EventRateOfChange" 10000;
BA_DEF_DEF_  "GenMsgStartDelayTime" 0;
BA_DEF_DEF_  "GenMsgNrOfRepetition" 1;
BA_DEF_DEF_  "GenMsgDelayTime" 20;
BA_DEF_DEF_  "GenMsgCycleTime" 0;
BA_DEF_DEF_  "GenMsgSendType" "NoMsgSendType";
BA_DEF_DEF_  "U_T6_MCA_MY2020_Tx" "No";
BA_DEF_DEF_  "U_P702_MY2021_Tx" "No";
BA_DEF_DEF_  "U_CX727_MY2021_Tx" "No";
BA_DEF_DEF_  "U_T6_MCA_MY2020_Rx" "No";
BA_DEF_DEF_  "U_P702_MY2021_Rx" "No";
BA_DEF_DEF_  "U_CX727_MY2021_Rx" "No";
BA_DEF_DEF_  "GenSigStartValue" 0;
BA_DEF_DEF_  "MetaData" "No";
BA_DEF_DEF_  "ContentDependant" "No";
BA_DEF_DEF_  "GenSigStartValueInteger" 0;
BA_DEF_DEF_  "UsedOnPgmDBC" "Yes";
BA_DEF_DEF_  "CrossOver_InfoCAN" "No";
BA_DEF_DEF_  "WakeupSignal" "No";
BA_DEF_DEF_  "GenSigInactiveValue" 0;
BA_DEF_DEF_  "GenSigSendType" "NoSigSendType";
BA_DEF_DEF_  "SCP_FreshnessValueLength" 64;
BA_DEF_DEF_  "AuthFreshnessCounterSyncAttempt" 2;
BA_DEF_DEF_  "SCP_FreshnessValueTxLength" 11;
BA_DEF_DEF_  "SCP_AuthInfoTxLength" 53;
BA_DEF_DEF_  "ProgBWConditional" "NONE";
BA_DEF_DEF_  "NmAsrMessage" "No";
BA_DEF_DEF_  "TpApplType" "";
BA_DEF_DEF_  "DiagState" "No";
BA_DEF_DEF_  "TpTxIndex" 0;
BA_DEF_DEF_  "DiagRequest" "No";
BA_DEF_DEF_  "DiagResponse" "No";
BA_DEF_DEF_  "GenMsgILSupport" "Yes";
BA_ "FrameGatewayNetwork" BO_ 90 "HS2_CAN";
BA_ "FrameGatewayId" BO_ 90 90;
BA_ "FrameRouting" BO_ 90 "";
BA_ "VFrameFormat" BO_ 90 14;
BA_ "FrameGatewayNetwork" BO_ 1091 "HS3_CAN";
BA_ "FrameGatewayId" BO_ 1091 1091;
BA_ "FrameRouting" BO_ 1091 "";
BA_ "VFrameFormat" BO_ 1091 14;
BA_ "FrameGatewayNetwork" BO_ 138 "HS2_CAN";
BA_ "FrameGatewayId" BO_ 138 138;
BA_ "FrameRouting" BO_ 138 "";
BA_ "VFrameFormat" BO_ 138 14;
BA_ "FrameGatewayNetwork" BO_ 131 "HS2_CAN";
BA_ "FrameGatewayId" BO_ 131 131;
BA_ "FrameRouting" BO_ 131 "";
BA_ "VFrameFormat" BO_ 131 14;
BA_ "FrameGatewayNetwork" BO_ 787 "MS2_CAN";
BA_ "FrameGatewayId" BO_ 787 787;
BA_ "FrameRouting" BO_ 787 "";
BA_ "VFrameFormat" BO_ 787 14;
BA_ "FrameGatewayNetwork" BO_ 953 "HS1_CAN";
BA_ "FrameGatewayId" BO_ 953 953;
BA_ "FrameRouting" BO_ 953 "";
BA_ "VFrameFormat" BO_ 953 14;
BA_ "FrameGatewayNetwork" BO_ 1093 "HS3_CAN";
BA_ "FrameGatewayId" BO_ 1093 1093;
BA_ "FrameRouting" BO_ 1093 "";
BA_ "VFrameFormat" BO_ 1093 14;
BA_ "FrameGatewayNetwork" BO_ 792 "HS3_CAN";
BA_ "FrameGatewayId" BO_ 792 792;
BA_ "FrameRouting" BO_ 792 "";
BA_ "VFrameFormat" BO_ 792 14;
BA_ "FrameGatewayNetwork" BO_ 968 "HS3_CAN";
BA_ "FrameGatewayId" BO_ 968 968;
BA_ "FrameRouting" BO_ 968 "";
BA_ "VFrameFormat" BO_ 968 14;
BA_ "FrameGatewayNetwork" BO_ 819 "MS1_CAN";
BA_ "FrameGatewayId" BO_ 819 819;
BA_ "FrameRouting" BO_ 819 "";
BA_ "VFrameFormat" BO_ 819 14;
BA_ "FrameGatewayNetwork" BO_ 818 "MS1_CAN";
BA_ "FrameGatewayId" BO_ 818 818;
BA_ "FrameRouting" BO_ 818 "";
BA_ "VFrameFormat" BO_ 818 14;
BA_ "FrameGatewayNetwork" BO_ 806 "MS1_CAN";
BA_ "FrameGatewayId" BO_ 806 806;
BA_ "FrameRouting" BO_ 806 "";
BA_ "VFrameFormat" BO_ 806 14;
BA_ "FrameGatewayNetwork" BO_ 765 "HS3_CAN";
BA_ "FrameGatewayId" BO_ 765 765;
BA_ "FrameRouting" BO_ 765 "";
BA_ "VFrameFormat" BO_ 765 14;
BA_ "FrameGatewayNetwork" BO_ 559 "HS3_CAN";
BA_ "FrameGatewayId" BO_ 559 559;
BA_ "FrameRouting" BO_ 559 "";
BA_ "VFrameFormat" BO_ 559 14;
BA_ "FrameGatewayNetwork" BO_ 558 "HS3_CAN";
BA_ "FrameGatewayId" BO_ 558 558;
BA_ "FrameRouting" BO_ 558 "";
BA_ "VFrameFormat" BO_ 558 14;
BA_ "GenMsgCycleTime" BO_ 934 200;
BA_ "GenMsgSendType" BO_ 934 5;
BA_ "FrameRouting" BO_ 934 "";
BA_ "VFrameFormat" BO_ 934 14;
BA_ "FrameGatewayNetwork" BO_ 1072 "HS3_CAN";
BA_ "FrameGatewayId" BO_ 1072 1072;
BA_ "FrameRouting" BO_ 1072 "";
BA_ "VFrameFormat" BO_ 1072 14;
BA_ "FrameGatewayNetwork" BO_ 909 "HS1_CAN";
BA_ "FrameGatewayId" BO_ 909 909;
BA_ "FrameRouting" BO_ 909 "";
BA_ "VFrameFormat" BO_ 909 14;
BA_ "FrameGatewayNetwork" BO_ 963 "HS1_CAN";
BA_ "FrameGatewayId" BO_ 963 963;
BA_ "FrameRouting" BO_ 963 "";
BA_ "VFrameFormat" BO_ 963 14;
BA_ "FrameGatewayNetwork" BO_ 145 "HS2_CAN";
BA_ "FrameGatewayId" BO_ 145 145;
BA_ "FrameRouting" BO_ 145 "";
BA_ "VFrameFormat" BO_ 145 14;
BA_ "FrameGatewayNetwork" BO_ 76 "HS2_CAN";
BA_ "FrameGatewayId" BO_ 76 76;
BA_ "FrameRouting" BO_ 76 "";
BA_ "VFrameFormat" BO_ 76 14;
BA_ "FrameGatewayNetwork" BO_ 65 "HS1_CAN";
BA_ "FrameGatewayId" BO_ 65 65;
BA_ "FrameRouting" BO_ 65 "";
BA_ "VFrameFormat" BO_ 65 14;
BA_ "FrameGatewayNetwork" BO_ 1076 "HS3_CAN";
BA_ "FrameGatewayId" BO_ 1076 1076;
BA_ "FrameRouting" BO_ 1076 "";
BA_ "VFrameFormat" BO_ 1076 14;
BA_ "FrameGatewayNetwork" BO_ 862 "MS1_CAN";
BA_ "FrameGatewayId" BO_ 862 862;
BA_ "FrameRouting" BO_ 862 "";
BA_ "VFrameFormat" BO_ 862 14;
BA_ "FrameGatewayNetwork" BO_ 931 "HS1_CAN";
BA_ "FrameGatewayId" BO_ 931 931;
BA_ "FrameRouting" BO_ 931 "";
BA_ "VFrameFormat" BO_ 931 14;
BA_ "FrameGatewayNetwork" BO_ 578 "HS1_CAN";
BA_ "FrameGatewayId" BO_ 578 578;
BA_ "FrameRouting" BO_ 578 "";
BA_ "VFrameFormat" BO_ 578 14;
BA_ "FrameGatewayNetwork" BO_ 947 "HS1_CAN";
BA_ "FrameGatewayId" BO_ 947 947;
BA_ "FrameRouting" BO_ 947 "";
BA_ "VFrameFormat" BO_ 947 14;
BA_ "FrameGatewayNetwork" BO_ 1084 "HS1_CAN";
BA_ "FrameGatewayId" BO_ 1084 1084;
BA_ "FrameRouting" BO_ 1084 "";
BA_ "VFrameFormat" BO_ 1084 14;
BA_ "FrameGatewayNetwork" BO_ 1068 "HS1_CAN";
BA_ "FrameGatewayId" BO_ 1068 1068;
BA_ "FrameRouting" BO_ 1068 "";
BA_ "VFrameFormat" BO_ 1068 14;
BA_ "FrameGatewayNetwork" BO_ 146 "HS2_CAN";
BA_ "FrameGatewayId" BO_ 146 146;
BA_ "FrameRouting" BO_ 146 "";
BA_ "VFrameFormat" BO_ 146 14;
BA_ "NetworkInitialization" BO_ 1900 0;
BA_ "GenMsgDelayTime" BO_ 1900 0;
BA_ "GenMsgSendType" BO_ 1900 1;
BA_ "DiagResponse" BO_ 1900 1;
BA_ "GenMsgILSupport" BO_ 1900 0;
BA_ "FrameRouting" BO_ 1900 "";
BA_ "VFrameFormat" BO_ 1900 14;
BA_ "NetworkInitialization" BO_ 1806 0;
BA_ "GenMsgDelayTime" BO_ 1806 0;
BA_ "GenMsgSendType" BO_ 1806 1;
BA_ "DiagResponse" BO_ 1806 1;
BA_ "GenMsgILSupport" BO_ 1806 0;
BA_ "FrameRouting" BO_ 1806 "";
BA_ "VFrameFormat" BO_ 1806 14;
BA_ "GenMsgCycleTime" BO_ 997 1000;
BA_ "GenMsgSendType" BO_ 997 5;
BA_ "FrameRouting" BO_ 997 "";
BA_ "VFrameFormat" BO_ 997 14;
BA_ "GenMsgCycleTime" BO_ 983 50;
BA_ "GenMsgSendType" BO_ 983 0;
BA_ "FrameRouting" BO_ 983 "";
BA_ "VFrameFormat" BO_ 983 14;
BA_ "GenMsgDelayTime" BO_ 980 10;
BA_ "GenMsgCycleTime" BO_ 980 30;
BA_ "GenMsgSendType" BO_ 980 0;
BA_ "FrameRouting" BO_ 980 "";
BA_ "VFrameFormat" BO_ 980 14;
BA_ "GenMsgCycleTime" BO_ 976 100;
BA_ "GenMsgSendType" BO_ 976 0;
BA_ "FrameRouting" BO_ 976 "";
BA_ "VFrameFormat" BO_ 976 14;
BA_ "GenMsgCycleTime" BO_ 973 1000;
BA_ "GenMsgSendType" BO_ 973 5;
BA_ "FrameRouting" BO_ 973 "";
BA_ "VFrameFormat" BO_ 973 14;
BA_ "GenMsgDelayTime" BO_ 970 10;
BA_ "GenMsgCycleTime" BO_ 970 30;
BA_ "GenMsgSendType" BO_ 970 0;
BA_ "FrameRouting" BO_ 970 "";
BA_ "VFrameFormat" BO_ 970 14;
BA_ "GenMsgCycleTime" BO_ 962 1000;
BA_ "GenMsgSendType" BO_ 962 5;
BA_ "FrameRouting" BO_ 962 "";
BA_ "VFrameFormat" BO_ 962 14;
BA_ "GenMsgCycleTime" BO_ 961 1000;
BA_ "GenMsgSendType" BO_ 961 5;
BA_ "FrameRouting" BO_ 961 "";
BA_ "VFrameFormat" BO_ 961 14;
BA_ "GenMsgCycleTime" BO_ 394 200;
BA_ "GenMsgSendType" BO_ 394 5;
BA_ "FrameRouting" BO_ 394 "";
BA_ "VFrameFormat" BO_ 394 14;
BA_ "GenMsgDelayTime" BO_ 391 10;
BA_ "GenMsgCycleTime" BO_ 391 20;
BA_ "GenMsgSendType" BO_ 391 0;
BA_ "FrameRouting" BO_ 391 "";
BA_ "VFrameFormat" BO_ 391 14;
BA_ "GenMsgDelayTime" BO_ 390 10;
BA_ "GenMsgCycleTime" BO_ 390 20;
BA_ "GenMsgSendType" BO_ 390 0;
BA_ "FrameRouting" BO_ 390 "";
BA_ "VFrameFormat" BO_ 390 14;
BA_ "NetworkInitialization" BO_ 1441 0;
BA_ "GenMsgCycleTime" BO_ 1441 1000;
BA_ "GenMsgSendType" BO_ 1441 0;
BA_ "NmAsrMessage" BO_ 1441 1;
BA_ "GenMsgILSupport" BO_ 1441 0;
BA_ "FrameRouting" BO_ 1441 "";
BA_ "VFrameFormat" BO_ 1441 14;
BA_ "GenMsgDelayTime" BO_ 1787 0;
BA_ "GenMsgSendType" BO_ 1787 1;
BA_ "DiagResponse" BO_ 1787 1;
BA_ "GenMsgILSupport" BO_ 1787 0;
BA_ "FrameRouting" BO_ 1787 "";
BA_ "VFrameFormat" BO_ 1787 14;
BA_ "GenMsgDelayTime" BO_ 1779 0;
BA_ "GenMsgSendType" BO_ 1779 1;
BA_ "DiagRequest" BO_ 1779 1;
BA_ "GenMsgILSupport" BO_ 1779 0;
BA_ "FrameRouting" BO_ 1779 "";
BA_ "VFrameFormat" BO_ 1779 14;
BA_ "GenMsgDelayTime" BO_ 1786 0;
BA_ "GenMsgSendType" BO_ 1786 1;
BA_ "DiagResponse" BO_ 1786 1;
BA_ "GenMsgILSupport" BO_ 1786 0;
BA_ "FrameRouting" BO_ 1786 "";
BA_ "VFrameFormat" BO_ 1786 14;
BA_ "GenMsgDelayTime" BO_ 1778 0;
BA_ "GenMsgSendType" BO_ 1778 1;
BA_ "DiagRequest" BO_ 1778 1;
BA_ "GenMsgILSupport" BO_ 1778 0;
BA_ "FrameRouting" BO_ 1778 "";
BA_ "VFrameFormat" BO_ 1778 14;
BA_ "GenMsgCycleTime" BO_ 942 200;
BA_ "GenMsgSendType" BO_ 942 5;
BA_ "FrameRouting" BO_ 942 "";
BA_ "VFrameFormat" BO_ 942 14;
BA_ "GenMsgCycleTime" BO_ 930 1000;
BA_ "GenMsgSendType" BO_ 930 5;
BA_ "FrameRouting" BO_ 930 "";
BA_ "VFrameFormat" BO_ 930 14;
BA_ "GenMsgCycleTime" BO_ 929 1000;
BA_ "GenMsgSendType" BO_ 929 5;
BA_ "FrameRouting" BO_ 929 "";
BA_ "VFrameFormat" BO_ 929 14;
BA_ "FrameGatewayNetwork" BO_ 402 "HS3_CAN";
BA_ "FrameGatewayId" BO_ 402 402;
BA_ "FrameRouting" BO_ 402 "";
BA_ "VFrameFormat" BO_ 402 14;
BA_ "FrameGatewayNetwork" BO_ 924 "HS1_CAN";
BA_ "FrameGatewayId" BO_ 924 924;
BA_ "FrameRouting" BO_ 924 "";
BA_ "VFrameFormat" BO_ 924 14;
BA_ "FrameGatewayNetwork" BO_ 923 "HS1_CAN";
BA_ "FrameGatewayId" BO_ 923 923;
BA_ "FrameRouting" BO_ 923 "";
BA_ "VFrameFormat" BO_ 923 14;
BA_ "NetworkInitialization" BO_ 1998 0;
BA_ "GenMsgDelayTime" BO_ 1998 0;
BA_ "GenMsgSendType" BO_ 1998 1;
BA_ "DiagResponse" BO_ 1998 1;
BA_ "GenMsgILSupport" BO_ 1998 0;
BA_ "FrameRouting" BO_ 1998 "";
BA_ "VFrameFormat" BO_ 1998 14;
BA_ "NetworkInitialization" BO_ 1996 0;
BA_ "GenMsgDelayTime" BO_ 1996 0;
BA_ "GenMsgSendType" BO_ 1996 1;
BA_ "DiagResponse" BO_ 1996 1;
BA_ "GenMsgILSupport" BO_ 1996 0;
BA_ "FrameRouting" BO_ 1996 "";
BA_ "VFrameFormat" BO_ 1996 14;
BA_ "NetworkInitialization" BO_ 1988 0;
BA_ "GenMsgDelayTime" BO_ 1988 0;
BA_ "GenMsgSendType" BO_ 1988 1;
BA_ "DiagRequest" BO_ 1988 1;
BA_ "GenMsgILSupport" BO_ 1988 0;
BA_ "FrameRouting" BO_ 1988 "";
BA_ "VFrameFormat" BO_ 1988 14;
BA_ "FrameGatewayNetwork" BO_ 922 "HS1_CAN";
BA_ "FrameGatewayId" BO_ 922 922;
BA_ "FrameRouting" BO_ 922 "";
BA_ "VFrameFormat" BO_ 922 14;
BA_ "U_CX727_MY2021_Rx" SG_ 90 TrnGsmNtmState_D_Actl 1;
BA_ "U_T6_MCA_MY2020_Rx" SG_ 90 TrnGsmNtmState_D_Actl 1;
BA_ "U_P702_MY2021_Rx" SG_ 90 TrnGsmNtmState_D_Actl 1;
BA_ "ContentDependant" SG_ 90 TrnGsmNtmState_D_Actl 1;
BA_ "CrossOver_InfoCAN" SG_ 90 TrnGsmNtmState_D_Actl 1;
BA_ "U_CX727_MY2021_Rx" SG_ 90 DrQltyDrv_D_StatGsm 1;
BA_ "U_T6_MCA_MY2020_Rx" SG_ 90 DrQltyDrv_D_StatGsm 1;
BA_ "U_P702_MY2021_Rx" SG_ 90 DrQltyDrv_D_StatGsm 1;
BA_ "GenSigStartValue" SG_ 90 DrQltyDrv_D_StatGsm 6;
BA_ "ContentDependant" SG_ 90 DrQltyDrv_D_StatGsm 1;
BA_ "U_T6_MCA_MY2020_Rx" SG_ 90 TrnBtsiOvrrd_B_Stat 1;
BA_ "U_P702_MY2021_Rx" SG_ 90 TrnBtsiOvrrd_B_Stat 1;
BA_ "ContentDependant" SG_ 90 TrnBtsiOvrrd_B_Stat 1;
BA_ "U_T6_MCA_MY2020_Rx" SG_ 90 TrnRng_D_RqGsm 1;
BA_ "U_P702_MY2021_Rx" SG_ 90 TrnRng_D_RqGsm 1;
BA_ "GenSigStartValue" SG_ 90 TrnRng_D_RqGsm 14;
BA_ "GenSigStartValueInteger" SG_ 90 TrnRng_D_RqGsm 14;
BA_ "U_P702_MY2021_Rx" SG_ 90 PrkBrkActv_D_RqGsmGear 1;
BA_ "U_CX727_MY2021_Rx" SG_ 90 PrkBrkActv_D_RqGsmGear 1;
BA_ "U_T6_MCA_MY2020_Rx" SG_ 90 TrnValidGearRq_D_Stat 1;
BA_ "U_P702_MY2021_Rx" SG_ 90 TrnValidGearRq_D_Stat 1;
BA_ "ContentDependant" SG_ 90 TrnValidGearRq_D_Stat 1;
BA_ "U_T6_MCA_MY2020_Rx" SG_ 90 TrnGearRqCnt_B_Actl 1;
BA_ "U_P702_MY2021_Rx" SG_ 90 TrnGearRqCnt_B_Actl 1;
BA_ "ContentDependant" SG_ 90 TrnGearRqCnt_B_Actl 1;
BA_ "U_T6_MCA_MY2020_Rx" SG_ 90 TrnGearButtn_U_Actl 1;
BA_ "U_P702_MY2021_Rx" SG_ 90 TrnGearButtn_U_Actl 1;
BA_ "ContentDependant" SG_ 90 TrnGearButtn_U_Actl 1;
BA_ "WakeupSignal" SG_ 90 TrnGearButtn_U_Actl 1;
BA_ "U_T6_MCA_MY2020_Rx" SG_ 90 TrnGearButtn_B_ActlR2 1;
BA_ "U_P702_MY2021_Rx" SG_ 90 TrnGearButtn_B_ActlR2 1;
BA_ "ContentDependant" SG_ 90 TrnGearButtn_B_ActlR2 1;
BA_ "WakeupSignal" SG_ 90 TrnGearButtn_B_ActlR2 1;
BA_ "U_T6_MCA_MY2020_Rx" SG_ 90 TrnGearButtn_B_ActlR1 1;
BA_ "U_P702_MY2021_Rx" SG_ 90 TrnGearButtn_B_ActlR1 1;
BA_ "ContentDependant" SG_ 90 TrnGearButtn_B_ActlR1 1;
BA_ "WakeupSignal" SG_ 90 TrnGearButtn_B_ActlR1 1;
BA_ "U_T6_MCA_MY2020_Rx" SG_ 90 TrnGearButtn_B_ActlR0 1;
BA_ "U_P702_MY2021_Rx" SG_ 90 TrnGearButtn_B_ActlR0 1;
BA_ "ContentDependant" SG_ 90 TrnGearButtn_B_ActlR0 1;
BA_ "WakeupSignal" SG_ 90 TrnGearButtn_B_ActlR0 1;
BA_ "U_T6_MCA_MY2020_Rx" SG_ 90 TrnGearButtn_B_ActlP2 1;
BA_ "U_P702_MY2021_Rx" SG_ 90 TrnGearButtn_B_ActlP2 1;
BA_ "ContentDependant" SG_ 90 TrnGearButtn_B_ActlP2 1;
BA_ "WakeupSignal" SG_ 90 TrnGearButtn_B_ActlP2 1;
BA_ "U_T6_MCA_MY2020_Rx" SG_ 90 TrnGearButtn_B_ActlP1 1;
BA_ "U_P702_MY2021_Rx" SG_ 90 TrnGearButtn_B_ActlP1 1;
BA_ "ContentDependant" SG_ 90 TrnGearButtn_B_ActlP1 1;
BA_ "WakeupSignal" SG_ 90 TrnGearButtn_B_ActlP1 1;
BA_ "U_T6_MCA_MY2020_Rx" SG_ 90 TrnGearButtn_B_ActlP0 1;
BA_ "U_P702_MY2021_Rx" SG_ 90 TrnGearButtn_B_ActlP0 1;
BA_ "ContentDependant" SG_ 90 TrnGearButtn_B_ActlP0 1;
BA_ "WakeupSignal" SG_ 90 TrnGearButtn_B_ActlP0 1;
BA_ "U_T6_MCA_MY2020_Rx" SG_ 90 TrnGearButtn_B_ActlN2 1;
BA_ "U_P702_MY2021_Rx" SG_ 90 TrnGearButtn_B_ActlN2 1;
BA_ "ContentDependant" SG_ 90 TrnGearButtn_B_ActlN2 1;
BA_ "WakeupSignal" SG_ 90 TrnGearButtn_B_ActlN2 1;
BA_ "U_T6_MCA_MY2020_Rx" SG_ 90 TrnGearButtn_B_ActlN1 1;
BA_ "U_P702_MY2021_Rx" SG_ 90 TrnGearButtn_B_ActlN1 1;
BA_ "ContentDependant" SG_ 90 TrnGearButtn_B_ActlN1 1;
BA_ "WakeupSignal" SG_ 90 TrnGearButtn_B_ActlN1 1;
BA_ "U_T6_MCA_MY2020_Rx" SG_ 90 TrnGearButtn_B_ActlN0 1;
BA_ "U_P702_MY2021_Rx" SG_ 90 TrnGearButtn_B_ActlN0 1;
BA_ "ContentDependant" SG_ 90 TrnGearButtn_B_ActlN0 1;
BA_ "WakeupSignal" SG_ 90 TrnGearButtn_B_ActlN0 1;
BA_ "U_T6_MCA_MY2020_Rx" SG_ 90 TrnGearButtn_B_ActlM2 1;
BA_ "U_P702_MY2021_Rx" SG_ 90 TrnGearButtn_B_ActlM2 1;
BA_ "ContentDependant" SG_ 90 TrnGearButtn_B_ActlM2 1;
BA_ "WakeupSignal" SG_ 90 TrnGearButtn_B_ActlM2 1;
BA_ "U_T6_MCA_MY2020_Rx" SG_ 90 TrnGearButtn_B_ActlM1 1;
BA_ "U_P702_MY2021_Rx" SG_ 90 TrnGearButtn_B_ActlM1 1;
BA_ "ContentDependant" SG_ 90 TrnGearButtn_B_ActlM1 1;
BA_ "WakeupSignal" SG_ 90 TrnGearButtn_B_ActlM1 1;
BA_ "U_T6_MCA_MY2020_Rx" SG_ 90 TrnGearButtn_B_ActlM0 1;
BA_ "U_P702_MY2021_Rx" SG_ 90 TrnGearButtn_B_ActlM0 1;
BA_ "ContentDependant" SG_ 90 TrnGearButtn_B_ActlM0 1;
BA_ "WakeupSignal" SG_ 90 TrnGearButtn_B_ActlM0 1;
BA_ "U_T6_MCA_MY2020_Rx" SG_ 90 TrnGearButtn_B_ActlD2 1;
BA_ "U_P702_MY2021_Rx" SG_ 90 TrnGearButtn_B_ActlD2 1;
BA_ "ContentDependant" SG_ 90 TrnGearButtn_B_ActlD2 1;
BA_ "WakeupSignal" SG_ 90 TrnGearButtn_B_ActlD2 1;
BA_ "U_T6_MCA_MY2020_Rx" SG_ 90 TrnGearButtn_B_ActlD1 1;
BA_ "U_P702_MY2021_Rx" SG_ 90 TrnGearButtn_B_ActlD1 1;
BA_ "ContentDependant" SG_ 90 TrnGearButtn_B_ActlD1 1;
BA_ "WakeupSignal" SG_ 90 TrnGearButtn_B_ActlD1 1;
BA_ "U_T6_MCA_MY2020_Rx" SG_ 90 TrnGearButtn_B_ActlD0 1;
BA_ "U_P702_MY2021_Rx" SG_ 90 TrnGearButtn_B_ActlD0 1;
BA_ "ContentDependant" SG_ 90 TrnGearButtn_B_ActlD0 1;
BA_ "WakeupSignal" SG_ 90 TrnGearButtn_B_ActlD0 1;
BA_ "U_T6_MCA_MY2020_Rx" SG_ 90 TrnGear_No_Cs 1;
BA_ "U_P702_MY2021_Rx" SG_ 90 TrnGear_No_Cs 1;
BA_ "MetaData" SG_ 90 TrnGear_No_Cs 1;
BA_ "ContentDependant" SG_ 90 TrnGear_No_Cs 1;
BA_ "U_T6_MCA_MY2020_Rx" SG_ 90 TrnGear_No_Cnt 1;
BA_ "U_P702_MY2021_Rx" SG_ 90 TrnGear_No_Cnt 1;
BA_ "MetaData" SG_ 90 TrnGear_No_Cnt 1;
BA_ "ContentDependant" SG_ 90 TrnGear_No_Cnt 1;
BA_ "U_T6_MCA_MY2020_Rx" SG_ 90 TrnGear_D_RqDrv 1;
BA_ "U_P702_MY2021_Rx" SG_ 90 TrnGear_D_RqDrv 1;
BA_ "ContentDependant" SG_ 90 TrnGear_D_RqDrv 1;
BA_ "WakeupSignal" SG_ 90 TrnGear_D_RqDrv 1;
BA_ "U_T6_MCA_MY2020_Rx" SG_ 90 BrkSwtchPos_B_ActlGsm 1;
BA_ "U_P702_MY2021_Rx" SG_ 90 BrkSwtchPos_B_ActlGsm 1;
BA_ "ContentDependant" SG_ 90 BrkSwtchPos_B_ActlGsm 1;
BA_ "CrossOver_InfoCAN" SG_ 1091 ParkLampTrlrOut_B_Stat 1;
BA_ "CrossOver_InfoCAN" SG_ 1091 TrlrLampCtl_D_Stat 1;
BA_ "CrossOver_InfoCAN" SG_ 1091 TrlrBattChrg_D_Stat 1;
BA_ "CrossOver_InfoCAN" SG_ 1091 StopLampTrlrOut_B_Stat 1;
BA_ "CrossOver_InfoCAN" SG_ 1091 TurnLampTrlrRr_B_Stat 1;
BA_ "CrossOver_InfoCAN" SG_ 1091 TurnLampTrlrRl_B_Stat 1;
BA_ "U_T6_MCA_MY2020_Rx" SG_ 1091 TrlrLampCnnct_B_Actl 1;
BA_ "U_CX727_MY2021_Rx" SG_ 1091 TrlrLampCnnct_B_Actl 1;
BA_ "U_P702_MY2021_Rx" SG_ 1091 TrlrLampCnnct_B_Actl 1;
BA_ "CrossOver_InfoCAN" SG_ 1091 TrlrLampCnnct_B_Actl 1;
BA_ "U_P702_MY2021_Rx" SG_ 138 SteWhlRelCalib_T_Actl 1;
BA_ "U_CX727_MY2021_Rx" SG_ 138 SteWhlRelCalib_An_Sns 1;
BA_ "U_P702_MY2021_Rx" SG_ 138 SteWhlRelCalib_An_Sns 1;
BA_ "ContentDependant" SG_ 138 SteWhlRelCalib_An_Sns 1;
BA_ "U_P702_MY2021_Rx" SG_ 131 HeadLghtHiCtrl_D_RqAhb 1;
BA_ "WakeupSignal" SG_ 131 HeadLghtHiCtrl_D_RqAhb 1;
BA_ "GenSigStartValue" SG_ 131 WiprFrontSwtch_D_Stat 9;
BA_ "GenSigStartValueInteger" SG_ 131 WiprFrontSwtch_D_Stat 9;
BA_ "CrossOver_InfoCAN" SG_ 131 HeadLghtHiOn_B_StatAhb 1;
BA_ "WakeupSignal" SG_ 131 HeadLghtHiOn_B_StatAhb 1;
BA_ "WakeupSignal" SG_ 131 HeadLghtHiFlash_D_Stat 1;
BA_ "U_CX727_MY2021_Rx" SG_ 131 WiprFront_D_Stat 1;
BA_ "U_T6_MCA_MY2020_Rx" SG_ 131 WiprFront_D_Stat 1;
BA_ "U_P702_MY2021_Rx" SG_ 131 WiprFront_D_Stat 1;
BA_ "GenSigStartValue" SG_ 131 WiprFront_D_Stat 15;
BA_ "GenSigStartValueInteger" SG_ 131 WiprFront_D_Stat 15;
BA_ "U_P702_MY2021_Rx" SG_ 131 TurnLghtSwtch_D_Stat 1;
BA_ "U_CX727_MY2021_Rx" SG_ 131 TurnLghtSwtch_D_Stat 1;
BA_ "CrossOver_InfoCAN" SG_ 131 TurnLghtSwtch_D_Stat 1;
BA_ "WakeupSignal" SG_ 131 TurnLghtSwtch_D_Stat 1;
BA_ "U_P702_MY2021_Rx" SG_ 131 LghtAmb_D_Sns 1;
BA_ "GenSigStartValue" SG_ 131 LghtAmb_D_Sns 7;
BA_ "GenSigStartValueInteger" SG_ 131 LghtAmb_D_Sns 7;
BA_ "U_T6_MCA_MY2020_Rx" SG_ 131 AslButtnOnOffPress 1;
BA_ "U_P702_MY2021_Rx" SG_ 131 AslButtnOnOffPress 1;
BA_ "U_T6_MCA_MY2020_Rx" SG_ 131 AslButtnOnOffCnclPress 1;
BA_ "U_P702_MY2021_Rx" SG_ 131 AslButtnOnOffCnclPress 1;
BA_ "U_T6_MCA_MY2020_Rx" SG_ 131 CcButtnOnPress 1;
BA_ "U_P702_MY2021_Rx" SG_ 131 CcButtnOnPress 1;
BA_ "U_T6_MCA_MY2020_Rx" SG_ 131 CcButtnOnOffPress 1;
BA_ "U_P702_MY2021_Rx" SG_ 131 CcButtnOnOffPress 1;
BA_ "U_T6_MCA_MY2020_Rx" SG_ 131 CcButtnOnOffCnclPress 1;
BA_ "U_P702_MY2021_Rx" SG_ 131 CcButtnOnOffCnclPress 1;
BA_ "U_T6_MCA_MY2020_Rx" SG_ 131 CcButtnOffPress 1;
BA_ "U_P702_MY2021_Rx" SG_ 131 CcButtnOffPress 1;
BA_ "U_T6_MCA_MY2020_Rx" SG_ 131 CcAsllButtnResPress 1;
BA_ "U_P702_MY2021_Rx" SG_ 131 CcAsllButtnResPress 1;
BA_ "U_T6_MCA_MY2020_Rx" SG_ 131 CcAslButtnSetIncPress 1;
BA_ "U_P702_MY2021_Rx" SG_ 131 CcAslButtnSetIncPress 1;
BA_ "U_T6_MCA_MY2020_Rx" SG_ 131 CcAslButtnSetDecPress 1;
BA_ "U_P702_MY2021_Rx" SG_ 131 CcAslButtnSetDecPress 1;
BA_ "U_T6_MCA_MY2020_Rx" SG_ 131 CcAslButtnResIncPress 1;
BA_ "U_P702_MY2021_Rx" SG_ 131 CcAslButtnResIncPress 1;
BA_ "U_T6_MCA_MY2020_Rx" SG_ 131 CcAslButtnOnPress 1;
BA_ "U_P702_MY2021_Rx" SG_ 131 CcAslButtnOnPress 1;
BA_ "U_T6_MCA_MY2020_Rx" SG_ 131 CcAslButtnIndxIncPress 1;
BA_ "U_P702_MY2021_Rx" SG_ 131 CcAslButtnIndxIncPress 1;
BA_ "U_T6_MCA_MY2020_Rx" SG_ 131 CcAslButtnIndxDecPress 1;
BA_ "U_P702_MY2021_Rx" SG_ 131 CcAslButtnIndxDecPress 1;
BA_ "U_T6_MCA_MY2020_Rx" SG_ 131 CcAslButtnDeny_B_Actl 1;
BA_ "U_P702_MY2021_Rx" SG_ 131 CcAslButtnDeny_B_Actl 1;
BA_ "U_T6_MCA_MY2020_Rx" SG_ 131 CcAslButtnCnclResPress 1;
BA_ "U_P702_MY2021_Rx" SG_ 131 CcAslButtnCnclResPress 1;
BA_ "U_T6_MCA_MY2020_Rx" SG_ 131 CcAslButtnCnclPress 1;
BA_ "U_P702_MY2021_Rx" SG_ 131 CcAslButtnCnclPress 1;
BA_ "WakeupSignal" SG_ 787 DrLckCnt_No_ActlTgate 1;
BA_ "WakeupSignal" SG_ 787 DrTgateChime2_D_Rq 1;
BA_ "U_T6_MCA_MY2020_Rx" SG_ 787 DrTGate_D_Rq 1;
BA_ "U_P702_MY2021_Rx" SG_ 787 DrTGate_D_Rq 1;
BA_ "WakeupSignal" SG_ 787 DrTGate_D_Rq 1;
BA_ "WakeupSignal" SG_ 787 PwLftgtIntSw_B_Stat 1;
BA_ "CrossOver_InfoCAN" SG_ 787 Power_Liftgate_Mode_Stt 1;
BA_ "U_P702_MY2021_Rx" SG_ 953 BattRgenLoDChrg_D_Rq 1;
BA_ "U_P702_MY2021_Rx" SG_ 953 BattRgenLoChrg_D_Rq 1;
BA_ "GenSigStartValue" SG_ 953 WakeAlarm3_D_Stat 3;
BA_ "GenSigStartValueInteger" SG_ 953 WakeAlarm3_D_Stat 3;
BA_ "GenSigStartValue" SG_ 953 WakeAlarm2_D_Stat 3;
BA_ "GenSigStartValueInteger" SG_ 953 WakeAlarm2_D_Stat 3;
BA_ "U_T6_MCA_MY2020_Rx" SG_ 953 WakeAlarm1_D_Stat 1;
BA_ "U_P702_MY2021_Rx" SG_ 953 WakeAlarm1_D_Stat 1;
BA_ "GenSigStartValue" SG_ 953 WakeAlarm1_D_Stat 3;
BA_ "GenSigStartValueInteger" SG_ 953 WakeAlarm1_D_Stat 3;
BA_ "GenSigStartValue" SG_ 953 WakeAlarm0_D_Stat 3;
BA_ "GenSigStartValueInteger" SG_ 953 WakeAlarm0_D_Stat 3;
BA_ "U_T6_MCA_MY2020_Rx" SG_ 1093 TrlrBrkActCnnct_B_Actl 1;
BA_ "U_CX727_MY2021_Rx" SG_ 1093 TrlrBrkActCnnct_B_Actl 1;
BA_ "U_P702_MY2021_Rx" SG_ 1093 TrlrBrkActCnnct_B_Actl 1;
BA_ "ContentDependant" SG_ 1093 StopLamp_B_RqTrlrBrk 1;
BA_ "U_T6_MCA_MY2020_Rx" SG_ 792 FuelRange_L_Dsply 1;
BA_ "U_P702_MY2021_Rx" SG_ 792 FuelRange_L_Dsply 1;
BA_ "ContentDependant" SG_ 792 ElTrip_L_Dsply 1;
BA_ "ContentDependant" SG_ 792 ElLongTerm_L_Dsply 1;
BA_ "U_T6_MCA_MY2020_Rx" SG_ 968 SlMde_D_Rq 1;
BA_ "U_P702_MY2021_Rx" SG_ 968 SlMde_D_Rq 1;
BA_ "GenSigStartValue" SG_ 968 SlMde_D_Rq 2;
BA_ "GenSigStartValueInteger" SG_ 968 SlMde_D_Rq 2;
BA_ "U_T6_MCA_MY2020_Rx" SG_ 968 IsaOffst_D_Rq 1;
BA_ "U_P702_MY2021_Rx" SG_ 968 IsaOffst_D_Rq 1;
BA_ "GenSigStartValue" SG_ 968 IsaOffst_D_Rq 14;
BA_ "GenSigStartValueInteger" SG_ 968 IsaOffst_D_Rq 14;
BA_ "WakeupSignal" SG_ 819 Memory_3_SwPsngr_Stat 1;
BA_ "WakeupSignal" SG_ 819 Memory_2_SwPsngr_Stat 1;
BA_ "WakeupSignal" SG_ 819 Memory_1_SwPsngr_Stat 1;
BA_ "U_T6_MCA_MY2020_Rx" SG_ 819 WndwPsngrSide_D_Stat 1;
BA_ "U_P702_MY2021_Rx" SG_ 819 WndwPsngrSide_D_Stat 1;
BA_ "WakeupSignal" SG_ 819 Pasngr_Lock_Sw_Stat 1;
BA_ "MetaData" SG_ 819 Pasngr_Lock_Sw_Cnt 1;
BA_ "WakeupSignal" SG_ 819 Pasngr_Lock_Sw_Cnt 1;
BA_ "WakeupSignal" SG_ 819 ChildLckFdbckRp_B_Stat 1;
BA_ "WakeupSignal" SG_ 818 ChildLckPw_N_Cnt 1;
BA_ "U_T6_MCA_MY2020_Rx" SG_ 818 WndwDrvSide_D_Stat 1;
BA_ "U_P702_MY2021_Rx" SG_ 818 WndwDrvSide_D_Stat 1;
BA_ "WakeupSignal" SG_ 818 KeyCylSwDrvDr_D_Stat 1;
BA_ "WakeupSignal" SG_ 818 Driver_Lock_Sw_Stat 1;
BA_ "MetaData" SG_ 818 Driver_Lock_Sw_Cnt 1;
BA_ "WakeupSignal" SG_ 818 Driver_Lock_Sw_Cnt 1;
BA_ "WakeupSignal" SG_ 818 ChildLckPw_D_Rq 1;
BA_ "WakeupSignal" SG_ 818 ChildLckFdbckRd_B_Stat 1;
BA_ "CrossOver_InfoCAN" SG_ 818 RvrseMirrorChime_B_Rq 1;
BA_ "U_T6_MCA_MY2020_Rx" SG_ 806 StopStrtDrvMde_B_RqBtn 1;
BA_ "U_P702_MY2021_Rx" SG_ 806 StopStrtDrvMde_B_RqBtn 1;
BA_ "U_T6_MCA_MY2020_Rx" SG_ 806 HvacHtrCore_Te_Rq 1;
BA_ "U_P702_MY2021_Rx" SG_ 806 HvacHtrCore_Te_Rq 1;
BA_ "U_T6_MCA_MY2020_Rx" SG_ 806 ClimtHeat_D_Rq 1;
BA_ "U_P702_MY2021_Rx" SG_ 806 ClimtHeat_D_Rq 1;
BA_ "U_T6_MCA_MY2020_Rx" SG_ 806 ClimtCool_D_Rq 1;
BA_ "U_P702_MY2021_Rx" SG_ 806 ClimtCool_D_Rq 1;
BA_ "U_T6_MCA_MY2020_Rx" SG_ 806 HvacEvap_Te_Rq 1;
BA_ "U_P702_MY2021_Rx" SG_ 806 HvacEvap_Te_Rq 1;
BA_ "GenSigStartValueInteger" SG_ 806 HvacEvap_Te_Rq 400;
BA_ "U_T6_MCA_MY2020_Rx" SG_ 806 HvacEvap_Te_Actl 1;
BA_ "U_P702_MY2021_Rx" SG_ 806 HvacEvap_Te_Actl 1;
BA_ "GenSigStartValueInteger" SG_ 806 HvacEvap_Te_Actl 400;
BA_ "U_T6_MCA_MY2020_Rx" SG_ 806 HvacAirCond_B_Rq 1;
BA_ "U_P702_MY2021_Rx" SG_ 806 HvacAirCond_B_Rq 1;
BA_ "U_T6_MCA_MY2020_Rx" SG_ 806 HvacEvap_Te_Offst 1;
BA_ "U_P702_MY2021_Rx" SG_ 806 HvacEvap_Te_Offst 1;
BA_ "GenSigStartValueInteger" SG_ 806 HvacEvap_Te_Offst 400;
BA_ "U_T6_MCA_MY2020_Rx" SG_ 806 ClimtPw_B_Rq 1;
BA_ "U_P702_MY2021_Rx" SG_ 806 ClimtPw_B_Rq 1;
BA_ "U_T6_MCA_MY2020_Rx" SG_ 765 EdmSailMde_B_RqDrv 1;
BA_ "WakeupSignal" SG_ 765 DrvInputRequired_B_Rq 1;
BA_ "U_T6_MCA_MY2020_Rx" SG_ 765 AwdRnge_D_ActlIpc 1;
BA_ "U_P702_MY2021_Rx" SG_ 765 AwdRnge_D_ActlIpc 1;
BA_ "GenSigStartValue" SG_ 765 AwdRnge_D_ActlIpc 7;
BA_ "GenSigStartValueInteger" SG_ 765 AwdRnge_D_ActlIpc 7;
BA_ "CrossOver_InfoCAN" SG_ 765 AwdRnge_D_ActlIpc 1;
BA_ "GenSigStartValue" SG_ 765 BalrSwtch_D_Stat 1;
BA_ "GenSigStartValueInteger" SG_ 765 BalrSwtch_D_Stat 1;
BA_ "U_T6_MCA_MY2020_Rx" SG_ 765 WaitToStartLamp_D_Falt 1;
BA_ "U_P702_MY2021_Rx" SG_ 765 WaitToStartLamp_D_Falt 1;
BA_ "GenSigStartValue" SG_ 765 WaitToStartLamp_D_Falt 1;
BA_ "GenSigStartValueInteger" SG_ 765 WaitToStartLamp_D_Falt 1;
BA_ "U_P702_MY2021_Rx" SG_ 765 EsaOn_B_Rq 1;
BA_ "GenSigStartValue" SG_ 765 EsaOn_B_Rq 1;
BA_ "GenSigStartValueInteger" SG_ 765 EsaOn_B_Rq 1;
BA_ "GenSigStartValue" SG_ 765 Btt_L_Actl 126;
BA_ "GenSigStartValueInteger" SG_ 765 Btt_L_Actl 126;
BA_ "U_P702_MY2021_Rx" SG_ 765 SelDrvMdeTxtReset_B_Rq 1;
BA_ "U_P702_MY2021_Rx" SG_ 765 SelDrvMdeDsply_B_Avail 1;
BA_ "CrossOver_InfoCAN" SG_ 765 Mc_VehUnitTempUsrSel_St 1;
BA_ "U_T6_MCA_MY2020_Rx" SG_ 559 EhData2_No_Actl 1;
BA_ "U_P702_MY2021_Rx" SG_ 559 EhData2_No_Actl 1;
BA_ "CrossOver_InfoCAN" SG_ 559 EhData2_No_Actl 1;
BA_ "U_T6_MCA_MY2020_Rx" SG_ 558 EhData1_No_Actl 1;
BA_ "U_P702_MY2021_Rx" SG_ 558 EhData1_No_Actl 1;
BA_ "CrossOver_InfoCAN" SG_ 558 EhData1_No_Actl 1;
BA_ "GenSigSendType" SG_ 934 CtaAlrtLeft2_D_Stat 3;
BA_ "GenSigSendType" SG_ 934 CtaBrkLeftMsgTxt_B_Rq 3;
BA_ "U_P702_MY2021_Rx" SG_ 934 CtaLeftBrkDecel_B_Rq 1;
BA_ "U_CX727_MY2021_Rx" SG_ 934 CtaLeftBrkDecel_B_Rq 1;
BA_ "GenSigSendType" SG_ 934 CtaLeftBrkDecel_B_Rq 3;
BA_ "U_P702_MY2021_Rx" SG_ 934 CtaLeftBrkEnbl_B_Rq 1;
BA_ "U_CX727_MY2021_Rx" SG_ 934 CtaLeftBrkEnbl_B_Rq 1;
BA_ "GenSigSendType" SG_ 934 CtaLeftBrkEnbl_B_Rq 3;
BA_ "GenSigStartValue" SG_ 934 Side_Detect_L_Illum 100;
BA_ "GenSigStartValueInteger" SG_ 934 Side_Detect_L_Illum 100;
BA_ "CrossOver_InfoCAN" SG_ 934 Side_Detect_L_Illum 1;
BA_ "GenSigSendType" SG_ 934 BttLeft_D_Stat 3;
BA_ "GenSigSendType" SG_ 934 BttLeft_D_RqDrv 3;
BA_ "GenSigSendType" SG_ 934 CtaSnsLeft_D_Stat 3;
BA_ "CrossOver_InfoCAN" SG_ 934 CtaSnsLeft_D_Stat 1;
BA_ "GenSigSendType" SG_ 934 SodDetctLeft_D_Stat 3;
BA_ "CrossOver_InfoCAN" SG_ 934 SodDetctLeft_D_Stat 1;
BA_ "GenSigSendType" SG_ 934 CtaLeft_D_Stat 3;
BA_ "CrossOver_InfoCAN" SG_ 934 CtaLeft_D_Stat 1;
BA_ "GenSigSendType" SG_ 934 CtaAlrtLeft_D_Stat 3;
BA_ "CrossOver_InfoCAN" SG_ 934 CtaAlrtLeft_D_Stat 1;
BA_ "GenSigSendType" SG_ 934 SodLeft_D_Stat 3;
BA_ "GenSigStartValue" SG_ 934 SodLeft_D_Stat 2;
BA_ "GenSigStartValueInteger" SG_ 934 SodLeft_D_Stat 2;
BA_ "CrossOver_InfoCAN" SG_ 934 SodLeft_D_Stat 1;
BA_ "GenSigSendType" SG_ 934 SodSnsLeft_D_Stat 3;
BA_ "CrossOver_InfoCAN" SG_ 934 SodSnsLeft_D_Stat 1;
BA_ "GenSigSendType" SG_ 934 SodAlrtLeft_D_Stat 3;
BA_ "CrossOver_InfoCAN" SG_ 934 SodAlrtLeft_D_Stat 1;
BA_ "GenSigStartValue" SG_ 934 SodWarnLeft_Prd_Rq 14;
BA_ "GenSigStartValueInteger" SG_ 934 SodWarnLeft_Prd_Rq 14;
BA_ "CrossOver_InfoCAN" SG_ 934 SodWarnLeft_Prd_Rq 1;
BA_ "U_P702_MY2021_Rx" SG_ 1072 DrvSlipCtlMde_D_Rq 1;
BA_ "CrossOver_InfoCAN" SG_ 1072 DrvSlipCtlMde_D_Rq 1;
BA_ "U_T6_MCA_MY2020_Rx" SG_ 1072 EngIdlShutDown_B_RqDrv 1;
BA_ "U_P702_MY2021_Rx" SG_ 1072 EngIdlShutDown_B_RqDrv 1;
BA_ "GenSigStartValue" SG_ 1072 HsaMde_D_Rq 1;
BA_ "GenSigStartValueInteger" SG_ 1072 HsaMde_D_Rq 1;
BA_ "CrossOver_InfoCAN" SG_ 1072 HsaMde_D_Rq 1;
BA_ "U_T6_MCA_MY2020_Rx" SG_ 1072 NtrlTowMdeEnbl_B_RqDrv 1;
BA_ "U_P702_MY2021_Rx" SG_ 1072 NtrlTowMdeEnbl_B_RqDrv 1;
BA_ "CrossOver_InfoCAN" SG_ 1072 NtrlTowMdeEnbl_B_RqDrv 1;
BA_ "CrossOver_InfoCAN" SG_ 1072 BulbChkActv_B_Stat 1;
BA_ "CrossOver_InfoCAN" SG_ 1072 ParkDetect_Stat 1;
BA_ "CrossOver_InfoCAN" SG_ 1072 ReducedGuard_D_Rq 1;
BA_ "U_P702_MY2021_Rx" SG_ 1072 TRLR_SWAY_CONFIG_CMD 1;
BA_ "CrossOver_InfoCAN" SG_ 1072 Power_Liftgate_Mode_Cmd 1;
BA_ "WakeupSignal" SG_ 1072 Power_Liftgate_Mode_Cmd 1;
BA_ "GenSigStartValue" SG_ 1072 AccEnbl_B_RqDrv 1;
BA_ "GenSigStartValueInteger" SG_ 1072 AccEnbl_B_RqDrv 1;
BA_ "CrossOver_InfoCAN" SG_ 1072 AccEnbl_B_RqDrv 1;
BA_ "U_CX727_MY2021_Rx" SG_ 1072 OdometerMasterValue 1;
BA_ "U_T6_MCA_MY2020_Rx" SG_ 1072 OdometerMasterValue 1;
BA_ "U_P702_MY2021_Rx" SG_ 1072 OdometerMasterValue 1;
BA_ "CrossOver_InfoCAN" SG_ 1072 OdometerMasterValue 1;
BA_ "U_T6_MCA_MY2020_Rx" SG_ 1072 EngOilLife_B_RqReset 1;
BA_ "U_P702_MY2021_Rx" SG_ 1072 EngOilLife_B_RqReset 1;
BA_ "CrossOver_InfoCAN" SG_ 1072 EngOilLife_B_RqReset 1;
BA_ "U_T6_MCA_MY2020_Rx" SG_ 1072 ePRNDL_MODE 1;
BA_ "U_P702_MY2021_Rx" SG_ 1072 ePRNDL_MODE 1;
BA_ "CrossOver_InfoCAN" SG_ 1072 ePRNDL_MODE 1;
BA_ "WakeupSignal" SG_ 1072 ePRNDL_MODE 1;
BA_ "U_P702_MY2021_Rx" SG_ 1072 DrvSlipCtlMde_B_Rq2 1;
BA_ "CrossOver_InfoCAN" SG_ 1072 DrvSlipCtlMde_B_Rq2 1;
BA_ "U_T6_MCA_MY2020_Rx" SG_ 1072 MetricActv_B_Actl 1;
BA_ "U_P702_MY2021_Rx" SG_ 1072 MetricActv_B_Actl 1;
BA_ "CrossOver_InfoCAN" SG_ 1072 MetricActv_B_Actl 1;
BA_ "CrossOver_InfoCAN" SG_ 1072 KeyTypeChngMykey_D_Rq 1;
BA_ "U_T6_MCA_MY2020_Rx" SG_ 1072 ManRgen_D_Rq 1;
BA_ "U_P702_MY2021_Rx" SG_ 1072 ManRgen_D_Rq 1;
BA_ "CrossOver_InfoCAN" SG_ 1072 ManRgen_D_Rq 1;
BA_ "WakeupSignal" SG_ 909 IgnPsswrdDsply_B_Rq 1;
BA_ "WakeupSignal" SG_ 909 ElPwPoint_D_Rq 1;
BA_ "CrossOver_InfoCAN" SG_ 909 SecurityMsgTxt_D_Rq 1;
BA_ "U_P702_MY2021_Rx" SG_ 909 HeadLghtHiPrmsn_D_Stat 1;
BA_ "GenSigStartValue" SG_ 909 HeadLghtHiPrmsn_D_Stat 3;
BA_ "GenSigStartValueInteger" SG_ 909 HeadLghtHiPrmsn_D_Stat 3;
BA_ "CrossOver_InfoCAN" SG_ 909 SteWhlLckMsgTxt_D_Rq 1;
BA_ "CrossOver_InfoCAN" SG_ 909 immoMsgTxt_D_Rq 1;
BA_ "WakeupSignal" SG_ 909 immoMsgTxt_D_Rq 1;
BA_ "CrossOver_InfoCAN" SG_ 909 PEBackupSlot_Stats 1;
BA_ "MetaData" SG_ 909 KeyMykeyTot_No_Cnt 1;
BA_ "CrossOver_InfoCAN" SG_ 909 KeyMykeyTot_No_Cnt 1;
BA_ "CrossOver_InfoCAN" SG_ 909 Keycode_Status 1;
BA_ "MetaData" SG_ 909 KeyAdmnTot_No_Cnt 1;
BA_ "CrossOver_InfoCAN" SG_ 909 KeyAdmnTot_No_Cnt 1;
BA_ "CrossOver_InfoCAN" SG_ 963 ImpactEvntFdbck_D_Stat 1;
BA_ "WakeupSignal" SG_ 963 ImpactEvntFdbck_D_Stat 1;
BA_ "CrossOver_InfoCAN" SG_ 963 HeadLampLoOut_B_Stat 1;
BA_ "U_P702_MY2021_Rx" SG_ 963 CrnrLghtRight_Pc_Rq 1;
BA_ "CrossOver_InfoCAN" SG_ 963 CrnrLghtRight_Pc_Rq 1;
BA_ "U_P702_MY2021_Rx" SG_ 963 CrnrLghtLeft_Pc_Rq 1;
BA_ "CrossOver_InfoCAN" SG_ 963 CrnrLghtLeft_Pc_Rq 1;
BA_ "CrossOver_InfoCAN" SG_ 963 HeadLghtHiFdbck_D_Stat 1;
BA_ "CrossOver_InfoCAN" SG_ 963 TrnNotInPrkChime_B_Rq 1;
BA_ "CrossOver_InfoCAN" SG_ 963 PrkLightChime_B_Rq 1;
BA_ "CrossOver_InfoCAN" SG_ 963 KeyInIgnWarn_B_Cmd 1;
BA_ "WakeupSignal" SG_ 963 KeyInIgnWarn_B_Cmd 1;
BA_ "CrossOver_InfoCAN" SG_ 963 HomeSafeLtChime_B_Rq 1;
BA_ "WakeupSignal" SG_ 963 HomeSafeLtChime_B_Rq 1;
BA_ "U_P702_MY2021_Rx" SG_ 963 StopLghtOn_B_Stat 1;
BA_ "CrossOver_InfoCAN" SG_ 963 StopLghtOn_B_Stat 1;
BA_ "WakeupSignal" SG_ 963 StopLghtOn_B_Stat 1;
BA_ "CrossOver_InfoCAN" SG_ 963 RvrseLghtOn_B_Stat 1;
BA_ "CrossOver_InfoCAN" SG_ 963 PrkLght_D_Stat 1;
BA_ "WakeupSignal" SG_ 963 PrkLght_D_Stat 1;
BA_ "U_P702_MY2021_Rx" SG_ 963 HeadLghtSwtch_D_Stat 1;
BA_ "GenSigStartValue" SG_ 963 HeadLghtSwtch_D_Stat 2;
BA_ "GenSigStartValueInteger" SG_ 963 HeadLghtSwtch_D_Stat 2;
BA_ "CrossOver_InfoCAN" SG_ 963 HeadLghtSwtch_D_Stat 1;
BA_ "WakeupSignal" SG_ 963 HeadLghtSwtch_D_Stat 1;
BA_ "U_P702_MY2021_Rx" SG_ 963 HeadLampLoFrOn_B_Stat 1;
BA_ "GenSigStartValue" SG_ 963 HeadLampLoFrOn_B_Stat 1;
BA_ "GenSigStartValueInteger" SG_ 963 HeadLampLoFrOn_B_Stat 1;
BA_ "CrossOver_InfoCAN" SG_ 963 HeadLampLoFrOn_B_Stat 1;
BA_ "U_P702_MY2021_Rx" SG_ 963 HeadLampLoFlOn_B_Stat 1;
BA_ "GenSigStartValue" SG_ 963 HeadLampLoFlOn_B_Stat 1;
BA_ "GenSigStartValueInteger" SG_ 963 HeadLampLoFlOn_B_Stat 1;
BA_ "CrossOver_InfoCAN" SG_ 963 HeadLampLoFlOn_B_Stat 1;
BA_ "U_T6_MCA_MY2020_Rx" SG_ 963 HeadLampLoActv_B_Stat 1;
BA_ "U_P702_MY2021_Rx" SG_ 963 HeadLampLoActv_B_Stat 1;
BA_ "GenSigStartValue" SG_ 963 HeadLampLoActv_B_Stat 1;
BA_ "GenSigStartValueInteger" SG_ 963 HeadLampLoActv_B_Stat 1;
BA_ "CrossOver_InfoCAN" SG_ 963 HeadLampLoActv_B_Stat 1;
BA_ "CrossOver_InfoCAN" SG_ 963 Headlamp_On_Wrning_Cmd 1;
BA_ "WakeupSignal" SG_ 963 Headlamp_On_Wrning_Cmd 1;
BA_ "CrossOver_InfoCAN" SG_ 963 Park_Brake_Chime_Rqst 1;
BA_ "U_T6_MCA_MY2020_Rx" SG_ 963 HeadLghtHiOn_B_Stat 1;
BA_ "U_P702_MY2021_Rx" SG_ 963 HeadLghtHiOn_B_Stat 1;
BA_ "CrossOver_InfoCAN" SG_ 963 HeadLghtHiOn_B_Stat 1;
BA_ "WakeupSignal" SG_ 963 HeadLghtHiOn_B_Stat 1;
BA_ "CrossOver_InfoCAN" SG_ 963 BrkWarnInd_B_Rq 1;
BA_ "CrossOver_InfoCAN" SG_ 963 Brk_Fluid_Lvl_Low 1;
BA_ "CrossOver_InfoCAN" SG_ 963 ReducedGuard_D_Stat 1;
BA_ "CrossOver_InfoCAN" SG_ 963 Perimeter_Alarm_Status 1;
BA_ "WakeupSignal" SG_ 963 Perimeter_Alarm_Status 1;
BA_ "GenSigStartValue" SG_ 963 Courtesy_BSave_Stat 1;
BA_ "GenSigStartValueInteger" SG_ 963 Courtesy_BSave_Stat 1;
BA_ "CrossOver_InfoCAN" SG_ 963 Courtesy_BSave_Stat 1;
BA_ "WakeupSignal" SG_ 963 Courtesy_BSave_Stat 1;
BA_ "CrossOver_InfoCAN" SG_ 963 WndwGlbl_D_Cmd 1;
BA_ "WakeupSignal" SG_ 963 WndwGlbl_D_Cmd 1;
BA_ "CrossOver_InfoCAN" SG_ 963 PudLamp_D_Rq 1;
BA_ "WakeupSignal" SG_ 963 PudLamp_D_Rq 1;
BA_ "U_P702_MY2021_Rx" SG_ 963 DayRnngLampOn_B_Stat 1;
BA_ "CrossOver_InfoCAN" SG_ 963 DayRnngLampOn_B_Stat 1;
BA_ "CrossOver_InfoCAN" SG_ 963 PerimeterAlarmChimeRq 1;
BA_ "WakeupSignal" SG_ 963 PerimeterAlarmChimeRq 1;
BA_ "U_P702_MY2021_Rx" SG_ 145 VehYawWActl_D_Qf 1;
BA_ "U_CX727_MY2021_Rx" SG_ 145 VehYawWActl_D_Qf 1;
BA_ "GenSigStartValue" SG_ 145 VehYawWActl_D_Qf 1;
BA_ "MetaData" SG_ 145 VehYawWActl_D_Qf 1;
BA_ "GenSigStartValueInteger" SG_ 145 VehYawWActl_D_Qf 1;
BA_ "U_P702_MY2021_Rx" SG_ 145 VehRolWActl_D_Qf 1;
BA_ "U_CX727_MY2021_Rx" SG_ 145 VehRolWActl_D_Qf 1;
BA_ "GenSigStartValue" SG_ 145 VehRolWActl_D_Qf 1;
BA_ "MetaData" SG_ 145 VehRolWActl_D_Qf 1;
BA_ "GenSigStartValueInteger" SG_ 145 VehRolWActl_D_Qf 1;
BA_ "U_P702_MY2021_Rx" SG_ 145 VehRollYawW_No_Cs 1;
BA_ "U_CX727_MY2021_Rx" SG_ 145 VehRollYawW_No_Cs 1;
BA_ "MetaData" SG_ 145 VehRollYawW_No_Cs 1;
BA_ "U_P702_MY2021_Rx" SG_ 145 VehRollYaw_No_Cnt 1;
BA_ "U_CX727_MY2021_Rx" SG_ 145 VehRollYaw_No_Cnt 1;
BA_ "MetaData" SG_ 145 VehRollYaw_No_Cnt 1;
BA_ "U_P702_MY2021_Rx" SG_ 145 VehYaw_W_Actl 1;
BA_ "U_CX727_MY2021_Rx" SG_ 145 VehYaw_W_Actl 1;
BA_ "GenSigStartValue" SG_ 145 VehYaw_W_Actl 65534;
BA_ "GenSigStartValueInteger" SG_ 145 VehYaw_W_Actl 65534;
BA_ "U_P702_MY2021_Rx" SG_ 145 VehRol_W_Actl 1;
BA_ "U_CX727_MY2021_Rx" SG_ 145 VehRol_W_Actl 1;
BA_ "GenSigStartValue" SG_ 145 VehRol_W_Actl 65534;
BA_ "GenSigStartValueInteger" SG_ 145 VehRol_W_Actl 65534;
BA_ "MetaData" SG_ 76 RCMStatusMsg2_No_Cnt 1;
BA_ "GenSigStartValue" SG_ 76 FirstRowBuckleMid 3;
BA_ "GenSigStartValueInteger" SG_ 76 FirstRowBuckleMid 3;
BA_ "CrossOver_InfoCAN" SG_ 76 FirstRowBuckleMid 1;
BA_ "GenSigStartValue" SG_ 76 SecondRowBucklePsngr 3;
BA_ "GenSigStartValueInteger" SG_ 76 SecondRowBucklePsngr 3;
BA_ "CrossOver_InfoCAN" SG_ 76 SecondRowBucklePsngr 1;
BA_ "GenSigStartValue" SG_ 76 SecondRowBuckleMid 3;
BA_ "GenSigStartValueInteger" SG_ 76 SecondRowBuckleMid 3;
BA_ "CrossOver_InfoCAN" SG_ 76 SecondRowBuckleMid 1;
BA_ "GenSigStartValue" SG_ 76 SecondRowBuckleDriver 3;
BA_ "GenSigStartValueInteger" SG_ 76 SecondRowBuckleDriver 3;
BA_ "CrossOver_InfoCAN" SG_ 76 SecondRowBuckleDriver 1;
BA_ "U_CX727_MY2021_Rx" SG_ 76 FirstRowBuckleDriver 1;
BA_ "U_T6_MCA_MY2020_Rx" SG_ 76 FirstRowBuckleDriver 1;
BA_ "U_P702_MY2021_Rx" SG_ 76 FirstRowBuckleDriver 1;
BA_ "GenSigStartValue" SG_ 76 FirstRowBuckleDriver 3;
BA_ "GenSigStartValueInteger" SG_ 76 FirstRowBuckleDriver 3;
BA_ "CrossOver_InfoCAN" SG_ 76 FirstRowBuckleDriver 1;
BA_ "CrossOver_InfoCAN" SG_ 76 RILReq 1;
BA_ "GenSigStartValue" SG_ 76 FirstRowBucklePsngr 3;
BA_ "GenSigStartValueInteger" SG_ 76 FirstRowBucklePsngr 3;
BA_ "CrossOver_InfoCAN" SG_ 76 FirstRowBucklePsngr 1;
BA_ "U_CX727_MY2021_Rx" SG_ 76 RstrnImpactEvntStatus 1;
BA_ "U_T6_MCA_MY2020_Rx" SG_ 76 RstrnImpactEvntStatus 1;
BA_ "U_P702_MY2021_Rx" SG_ 76 RstrnImpactEvntStatus 1;
BA_ "CrossOver_InfoCAN" SG_ 76 RstrnImpactEvntStatus 1;
BA_ "WakeupSignal" SG_ 76 RstrnImpactEvntStatus 1;
BA_ "GenSigStartValue" SG_ 76 PsngrFrntDetct_D_Actl 3;
BA_ "GenSigStartValueInteger" SG_ 76 PsngrFrntDetct_D_Actl 3;
BA_ "CrossOver_InfoCAN" SG_ 76 PsngrFrntDetct_D_Actl 1;
BA_ "CrossOver_InfoCAN" SG_ 76 EDRTriggerEvntSync 1;
BA_ "GenSigStartValue" SG_ 76 PassRstrnInd_Req 3;
BA_ "GenSigStartValueInteger" SG_ 76 PassRstrnInd_Req 3;
BA_ "CrossOver_InfoCAN" SG_ 76 PassRstrnInd_Req 1;
BA_ "U_T6_MCA_MY2020_Rx" SG_ 65 immoControlData_T1 1;
BA_ "U_P702_MY2021_Rx" SG_ 65 immoControlData_T1 1;
BA_ "U_T6_MCA_MY2020_Rx" SG_ 65 immoControlCmd_T1 1;
BA_ "U_P702_MY2021_Rx" SG_ 65 immoControlCmd_T1 1;
BA_ "U_T6_MCA_MY2020_Rx" SG_ 1076 HILL_DESC_SW 1;
BA_ "U_P702_MY2021_Rx" SG_ 1076 HILL_DESC_SW 1;
BA_ "CrossOver_InfoCAN" SG_ 1076 HILL_DESC_SW 1;
BA_ "U_T6_MCA_MY2020_Rx" SG_ 1076 AutoRgen_D_Rq 1;
BA_ "U_P702_MY2021_Rx" SG_ 1076 AutoRgen_D_Rq 1;
BA_ "GenSigStartValue" SG_ 1076 W2S_LAMP_OK 1;
BA_ "GenSigStartValueInteger" SG_ 1076 W2S_LAMP_OK 1;
BA_ "U_T6_MCA_MY2020_Rx" SG_ 1076 OdoTripRx_B_Actl 1;
BA_ "U_P702_MY2021_Rx" SG_ 1076 OdoTripRx_B_Actl 1;
BA_ "CrossOver_InfoCAN" SG_ 1076 OdoTripRx_B_Actl 1;
BA_ "U_T6_MCA_MY2020_Rx" SG_ 1076 Veh_V_CompLimMx 1;
BA_ "U_P702_MY2021_Rx" SG_ 1076 Veh_V_CompLimMx 1;
BA_ "GenSigStartValue" SG_ 1076 Veh_V_CompLimMx 4093;
BA_ "GenSigStartValueInteger" SG_ 1076 Veh_V_CompLimMx 4095;
BA_ "CrossOver_InfoCAN" SG_ 1076 Veh_V_CompLimMx 1;
BA_ "CrossOver_InfoCAN" SG_ 1076 DrvSlipCtlMde_B_RqMyKey 1;
BA_ "CrossOver_InfoCAN" SG_ 1076 FuelLvlWarn_D_Actl 1;
BA_ "CrossOver_InfoCAN" SG_ 1076 FuelSecndActv_B_Actl 1;
BA_ "U_T6_MCA_MY2020_Rx" SG_ 1076 FuelLvlPssvSide_No_Raw 1;
BA_ "U_P702_MY2021_Rx" SG_ 1076 FuelLvlPssvSide_No_Raw 1;
BA_ "CrossOver_InfoCAN" SG_ 1076 FuelLvlPssvSide_No_Raw 1;
BA_ "U_T6_MCA_MY2020_Rx" SG_ 1076 FUEL_SENSOR_NUM 1;
BA_ "U_P702_MY2021_Rx" SG_ 1076 FUEL_SENSOR_NUM 1;
BA_ "CrossOver_InfoCAN" SG_ 1076 FUEL_SENSOR_NUM 1;
BA_ "U_T6_MCA_MY2020_Rx" SG_ 1076 FuelLvlActvSide_No_Raw 1;
BA_ "U_P702_MY2021_Rx" SG_ 1076 FuelLvlActvSide_No_Raw 1;
BA_ "CrossOver_InfoCAN" SG_ 1076 FuelLvlActvSide_No_Raw 1;
BA_ "U_T6_MCA_MY2020_Rx" SG_ 1076 FuelLvl_Pc_Dsply 1;
BA_ "U_P702_MY2021_Rx" SG_ 1076 FuelLvl_Pc_Dsply 1;
BA_ "CrossOver_InfoCAN" SG_ 1076 FuelLvl_Pc_Dsply 1;
BA_ "U_T6_MCA_MY2020_Rx" SG_ 1076 DISPLAY_SPEED_SCALING 1;
BA_ "U_P702_MY2021_Rx" SG_ 1076 DISPLAY_SPEED_SCALING 1;
BA_ "CrossOver_InfoCAN" SG_ 1076 DISPLAY_SPEED_SCALING 1;
BA_ "U_T6_MCA_MY2020_Rx" SG_ 1076 DISPLAY_SPEED_OFFSET 1;
BA_ "U_P702_MY2021_Rx" SG_ 1076 DISPLAY_SPEED_OFFSET 1;
BA_ "CrossOver_InfoCAN" SG_ 1076 DISPLAY_SPEED_OFFSET 1;
BA_ "GenSigStartValueInteger" SG_ 862 AutoStpHvacDelta_I_Est 192;
BA_ "U_T6_MCA_MY2020_Rx" SG_ 862 HvacBlwrFront_D_Stat 1;
BA_ "U_P702_MY2021_Rx" SG_ 862 HvacBlwrFront_D_Stat 1;
BA_ "U_P702_MY2021_Rx" SG_ 862 CabnAmb_Te_Actl 1;
BA_ "GenSigStartValueInteger" SG_ 862 CabnAmb_Te_Actl 114;
BA_ "U_T6_MCA_MY2020_Rx" SG_ 862 HvacRemoteStrt_N_Rq 1;
BA_ "U_P702_MY2021_Rx" SG_ 862 HvacRemoteStrt_N_Rq 1;
BA_ "U_P702_MY2021_Rx" SG_ 862 ClimtThrmlLoad_No_Actl 1;
BA_ "GenSigStartValue" SG_ 862 ClimtThrmlLoad_No_Actl 255;
BA_ "GenSigStartValueInteger" SG_ 862 ClimtThrmlLoad_No_Actl 255;
BA_ "U_P702_MY2021_Rx" SG_ 931 PtWakeReas_D_Stat 1;
BA_ "U_T6_MCA_MY2020_Rx" SG_ 931 VehOnSrc_D_Stat 1;
BA_ "U_P702_MY2021_Rx" SG_ 931 VehOnSrc_D_Stat 1;
BA_ "U_T6_MCA_MY2020_Rx" SG_ 931 StrtrMtrCtlDStat_No_Cs 1;
BA_ "U_P702_MY2021_Rx" SG_ 931 StrtrMtrCtlDStat_No_Cs 1;
BA_ "U_T6_MCA_MY2020_Rx" SG_ 931 EngStrtActv_B_Stat 1;
BA_ "U_P702_MY2021_Rx" SG_ 931 EngStrtActv_B_Stat 1;
BA_ "U_T6_MCA_MY2020_Rx" SG_ 931 EngStrt_B_Rq 1;
BA_ "U_P702_MY2021_Rx" SG_ 931 EngStrt_B_Rq 1;
BA_ "U_T6_MCA_MY2020_Rx" SG_ 931 DrvInCtl_B_Stat 1;
BA_ "U_P702_MY2021_Rx" SG_ 931 DrvInCtl_B_Stat 1;
BA_ "U_T6_MCA_MY2020_Rx" SG_ 931 AdvStrt_D_Stat 1;
BA_ "U_P702_MY2021_Rx" SG_ 931 AdvStrt_D_Stat 1;
BA_ "U_T6_MCA_MY2020_Rx" SG_ 931 CrnkInhbt_No_Cs 1;
BA_ "U_P702_MY2021_Rx" SG_ 931 CrnkInhbt_No_Cs 1;
BA_ "MetaData" SG_ 931 CrnkInhbt_No_Cs 1;
BA_ "ContentDependant" SG_ 931 CrnkInhbt_No_Cs 1;
BA_ "U_T6_MCA_MY2020_Rx" SG_ 931 CrnkInhbt_No_Cnt 1;
BA_ "U_P702_MY2021_Rx" SG_ 931 CrnkInhbt_No_Cnt 1;
BA_ "MetaData" SG_ 931 CrnkInhbt_No_Cnt 1;
BA_ "ContentDependant" SG_ 931 CrnkInhbt_No_Cnt 1;
BA_ "U_T6_MCA_MY2020_Rx" SG_ 931 CrnkInhbt_B_Stat 1;
BA_ "U_P702_MY2021_Rx" SG_ 931 CrnkInhbt_B_Stat 1;
BA_ "GenSigStartValue" SG_ 931 CrnkInhbt_B_Stat 1;
BA_ "GenSigStartValueInteger" SG_ 931 CrnkInhbt_B_Stat 1;
BA_ "U_T6_MCA_MY2020_Rx" SG_ 931 IgnPreOffActv_B_Stat 1;
BA_ "U_P702_MY2021_Rx" SG_ 931 IgnPreOffActv_B_Stat 1;
BA_ "U_T6_MCA_MY2020_Rx" SG_ 578 PtLatchActv_B_RqBcm 1;
BA_ "U_P702_MY2021_Rx" SG_ 578 PtLatchActv_B_RqBcm 1;
BA_ "U_T6_MCA_MY2020_Rx" SG_ 578 immoSecureIdleMode 1;
BA_ "U_P702_MY2021_Rx" SG_ 578 immoSecureIdleMode 1;
BA_ "WakeupSignal" SG_ 578 ReFuelSwtchStat_D_Actl 1;
BA_ "U_T6_MCA_MY2020_Rx" SG_ 578 FuelPumpPwr_D_Stat 1;
BA_ "U_P702_MY2021_Rx" SG_ 578 FuelPumpPwr_D_Stat 1;
BA_ "U_CX727_MY2021_Rx" SG_ 578 BattULo_U_Actl 1;
BA_ "U_T6_MCA_MY2020_Rx" SG_ 578 BattULo_U_Actl 1;
BA_ "U_P702_MY2021_Rx" SG_ 578 BattULo_U_Actl 1;
BA_ "GenSigStartValue" SG_ 578 BattULo_U_Actl 255;
BA_ "GenSigStartValueInteger" SG_ 578 BattULo_U_Actl 255;
BA_ "CrossOver_InfoCAN" SG_ 578 PrkLckCtl_B_Enbl 1;
BA_ "CrossOver_InfoCAN" SG_ 578 PrkLckCtlMsgTxt_D_Rq 1;
BA_ "WakeupSignal" SG_ 578 PrkLckCtlMsgTxt_D_Rq 1;
BA_ "CrossOver_InfoCAN" SG_ 578 PrkLckCtlAvail_T_Stat 1;
BA_ "WakeupSignal" SG_ 578 PrkLckCtlAvail_T_Stat 1;
BA_ "U_T6_MCA_MY2020_Rx" SG_ 578 BrkTrnShifLck_B_Stat 1;
BA_ "U_P702_MY2021_Rx" SG_ 578 BrkTrnShifLck_B_Stat 1;
BA_ "U_T6_MCA_MY2020_Rx" SG_ 578 DriverCrankingReq 1;
BA_ "U_P702_MY2021_Rx" SG_ 578 DriverCrankingReq 1;
BA_ "U_CX727_MY2021_Rx" SG_ 578 EngOff_T_Actl 1;
BA_ "U_T6_MCA_MY2020_Rx" SG_ 578 EngOff_T_Actl 1;
BA_ "U_P702_MY2021_Rx" SG_ 578 EngOff_T_Actl 1;
BA_ "U_T6_MCA_MY2020_Rx" SG_ 578 DcacElPw_D_Rq 1;
BA_ "U_P702_MY2021_Rx" SG_ 578 DcacElPw_D_Rq 1;
BA_ "U_T6_MCA_MY2020_Rx" SG_ 578 BattULo_I_Actl 1;
BA_ "U_P702_MY2021_Rx" SG_ 578 BattULo_I_Actl 1;
BA_ "GenSigStartValue" SG_ 578 BattULo_I_Actl 16383;
BA_ "GenSigStartValueInteger" SG_ 578 BattULo_I_Actl 16383;
BA_ "WakeupSignal" SG_ 947 DimmingLvlEvnt_No_Actl 1;
BA_ "U_T6_MCA_MY2020_Rx" SG_ 947 DrStatDrvErrCnt_B_Stat 1;
BA_ "U_P702_MY2021_Rx" SG_ 947 DrStatDrvErrCnt_B_Stat 1;
BA_ "U_P702_MY2021_Rx" SG_ 947 TurnLghtRight_D_Rq 1;
BA_ "CrossOver_InfoCAN" SG_ 947 TurnLghtRight_D_Rq 1;
BA_ "WakeupSignal" SG_ 947 TurnLghtRight_D_Rq 1;
BA_ "CrossOver_InfoCAN" SG_ 947 TurnLghtRightOn_B_Stat 1;
BA_ "CrossOver_InfoCAN" SG_ 947 TurnLghtLeftOn_B_Stat 1;
BA_ "U_P702_MY2021_Rx" SG_ 947 FogLghtRearOn_B_Stat 1;
BA_ "CrossOver_InfoCAN" SG_ 947 FogLghtRearOn_B_Stat 1;
BA_ "CrossOver_InfoCAN" SG_ 947 Backlit_LED_Status 1;
BA_ "WakeupSignal" SG_ 947 Backlit_LED_Status 1;
BA_ "U_P702_MY2021_Rx" SG_ 947 TurnLghtLeft_D_Rq 1;
BA_ "CrossOver_InfoCAN" SG_ 947 TurnLghtLeft_D_Rq 1;
BA_ "WakeupSignal" SG_ 947 TurnLghtLeft_D_Rq 1;
BA_ "U_P702_MY2021_Rx" SG_ 947 FogLghtFrontOn_B_Stat 1;
BA_ "CrossOver_InfoCAN" SG_ 947 FogLghtFrontOn_B_Stat 1;
BA_ "U_CX727_MY2021_Rx" SG_ 947 IgnKeyType_D_Actl 1;
BA_ "U_T6_MCA_MY2020_Rx" SG_ 947 IgnKeyType_D_Actl 1;
BA_ "U_P702_MY2021_Rx" SG_ 947 IgnKeyType_D_Actl 1;
BA_ "GenSigStartValue" SG_ 947 IgnKeyType_D_Actl 14;
BA_ "GenSigStartValueInteger" SG_ 947 IgnKeyType_D_Actl 14;
BA_ "CrossOver_InfoCAN" SG_ 947 IgnKeyType_D_Actl 1;
BA_ "GenSigStartValue" SG_ 947 Parklamp_Status 1;
BA_ "GenSigStartValueInteger" SG_ 947 Parklamp_Status 1;
BA_ "CrossOver_InfoCAN" SG_ 947 Parklamp_Status 1;
BA_ "WakeupSignal" SG_ 947 Parklamp_Status 1;
BA_ "U_P702_MY2021_Rx" SG_ 947 Litval 1;
BA_ "CrossOver_InfoCAN" SG_ 947 Litval 1;
BA_ "WakeupSignal" SG_ 947 Litval 1;
BA_ "U_P702_MY2021_Rx" SG_ 947 Key_In_Ignition_Stat 1;
BA_ "U_CX727_MY2021_Rx" SG_ 947 Key_In_Ignition_Stat 1;
BA_ "CrossOver_InfoCAN" SG_ 947 Key_In_Ignition_Stat 1;
BA_ "WakeupSignal" SG_ 947 Key_In_Ignition_Stat 1;
BA_ "U_CX727_MY2021_Rx" SG_ 947 Ignition_Status 1;
BA_ "U_T6_MCA_MY2020_Rx" SG_ 947 Ignition_Status 1;
BA_ "U_P702_MY2021_Rx" SG_ 947 Ignition_Status 1;
BA_ "CrossOver_InfoCAN" SG_ 947 Ignition_Status 1;
BA_ "WakeupSignal" SG_ 947 Ignition_Status 1;
BA_ "GenSigStartValue" SG_ 947 Dimming_Lvl 12;
BA_ "GenSigStartValueInteger" SG_ 947 Dimming_Lvl 12;
BA_ "CrossOver_InfoCAN" SG_ 947 Dimming_Lvl 1;
BA_ "WakeupSignal" SG_ 947 Dimming_Lvl 1;
BA_ "U_T6_MCA_MY2020_Rx" SG_ 947 Day_Night_Status 1;
BA_ "U_P702_MY2021_Rx" SG_ 947 Day_Night_Status 1;
BA_ "CrossOver_InfoCAN" SG_ 947 Day_Night_Status 1;
BA_ "WakeupSignal" SG_ 947 Day_Night_Status 1;
BA_ "CrossOver_InfoCAN" SG_ 947 Remote_Start_Status 1;
BA_ "WakeupSignal" SG_ 947 Remote_Start_Status 1;
BA_ "CrossOver_InfoCAN" SG_ 947 DrStatTgate_B_Actl 1;
BA_ "WakeupSignal" SG_ 947 DrStatTgate_B_Actl 1;
BA_ "U_P702_MY2021_Rx" SG_ 947 DrStatRr_B_Actl 1;
BA_ "CrossOver_InfoCAN" SG_ 947 DrStatRr_B_Actl 1;
BA_ "WakeupSignal" SG_ 947 DrStatRr_B_Actl 1;
BA_ "U_P702_MY2021_Rx" SG_ 947 DrStatRl_B_Actl 1;
BA_ "CrossOver_InfoCAN" SG_ 947 DrStatRl_B_Actl 1;
BA_ "WakeupSignal" SG_ 947 DrStatRl_B_Actl 1;
BA_ "U_P702_MY2021_Rx" SG_ 947 DrStatPsngr_B_Actl 1;
BA_ "CrossOver_InfoCAN" SG_ 947 DrStatPsngr_B_Actl 1;
BA_ "WakeupSignal" SG_ 947 DrStatPsngr_B_Actl 1;
BA_ "CrossOver_InfoCAN" SG_ 947 DrStatInnrTgate_B_Actl 1;
BA_ "WakeupSignal" SG_ 947 DrStatInnrTgate_B_Actl 1;
BA_ "CrossOver_InfoCAN" SG_ 947 DrStatHood_B_Actl 1;
BA_ "WakeupSignal" SG_ 947 DrStatHood_B_Actl 1;
BA_ "U_CX727_MY2021_Rx" SG_ 947 DrStatDrv_B_Actl 1;
BA_ "U_T6_MCA_MY2020_Rx" SG_ 947 DrStatDrv_B_Actl 1;
BA_ "U_P702_MY2021_Rx" SG_ 947 DrStatDrv_B_Actl 1;
BA_ "CrossOver_InfoCAN" SG_ 947 DrStatDrv_B_Actl 1;
BA_ "WakeupSignal" SG_ 947 DrStatDrv_B_Actl 1;
BA_ "U_CX727_MY2021_Rx" SG_ 947 PrkBrkActv_B_Actl 1;
BA_ "U_T6_MCA_MY2020_Rx" SG_ 947 PrkBrkActv_B_Actl 1;
BA_ "U_P702_MY2021_Rx" SG_ 947 PrkBrkActv_B_Actl 1;
BA_ "ContentDependant" SG_ 947 PrkBrkActv_B_Actl 1;
BA_ "CrossOver_InfoCAN" SG_ 947 PrkBrkActv_B_Actl 1;
BA_ "WakeupSignal" SG_ 947 PrkBrkActv_B_Actl 1;
BA_ "U_CX727_MY2021_Rx" SG_ 947 LifeCycMde_D_Actl 1;
BA_ "U_T6_MCA_MY2020_Rx" SG_ 947 LifeCycMde_D_Actl 1;
BA_ "U_P702_MY2021_Rx" SG_ 947 LifeCycMde_D_Actl 1;
BA_ "CrossOver_InfoCAN" SG_ 947 LifeCycMde_D_Actl 1;
BA_ "CrossOver_InfoCAN" SG_ 947 Delay_Accy 1;
BA_ "WakeupSignal" SG_ 947 Delay_Accy 1;
BA_ "GenSigStartValue" SG_ 947 CrashEvnt_D_Stat 3;
BA_ "GenSigStartValueInteger" SG_ 947 CrashEvnt_D_Stat 3;
BA_ "CrossOver_InfoCAN" SG_ 947 CrashEvnt_D_Stat 1;
BA_ "WakeupSignal" SG_ 947 CrashEvnt_D_Stat 1;
BA_ "CrossOver_InfoCAN" SG_ 947 FuelPmpInhbt_B_Stat 1;
BA_ "CrossOver_InfoCAN" SG_ 947 BodySrvcRqd_B_Rq 1;
BA_ "U_T6_MCA_MY2020_Rx" SG_ 1084 BattULoChrg_URate_RqMx 1;
BA_ "U_P702_MY2021_Rx" SG_ 1084 BattULoChrg_URate_RqMx 1;
BA_ "GenSigStartValue" SG_ 1084 BattULoChrg_URate_RqMx 5;
BA_ "GenSigStartValueInteger" SG_ 1084 BattULoChrg_URate_RqMx 5;
BA_ "U_T6_MCA_MY2020_Rx" SG_ 1084 BattULoChrg_U_RqMx 1;
BA_ "U_P702_MY2021_Rx" SG_ 1084 BattULoChrg_U_RqMx 1;
BA_ "GenSigStartValue" SG_ 1084 BattULoChrg_U_RqMx 34;
BA_ "GenSigStartValueInteger" SG_ 1084 BattULoChrg_U_RqMx 34;
BA_ "U_T6_MCA_MY2020_Rx" SG_ 1084 BattULoChrg_U_RqMn 1;
BA_ "U_P702_MY2021_Rx" SG_ 1084 BattULoChrg_U_RqMn 1;
BA_ "U_T6_MCA_MY2020_Rx" SG_ 1084 BattULoState_D_Qlty 1;
BA_ "U_P702_MY2021_Rx" SG_ 1084 BattULoState_D_Qlty 1;
BA_ "U_T6_MCA_MY2020_Rx" SG_ 1084 BSFault 1;
BA_ "U_P702_MY2021_Rx" SG_ 1084 BSFault 1;
BA_ "U_T6_MCA_MY2020_Rx" SG_ 1084 BattULo2_Te_Actl 1;
BA_ "U_P702_MY2021_Rx" SG_ 1084 BattULo2_Te_Actl 1;
BA_ "GenSigStartValue" SG_ 1084 BattULo2_Te_Actl 127;
BA_ "GenSigStartValueInteger" SG_ 1084 BattULo2_Te_Actl 127;
BA_ "U_T6_MCA_MY2020_Rx" SG_ 1084 BSBattSOC 1;
BA_ "U_P702_MY2021_Rx" SG_ 1084 BSBattSOC 1;
BA_ "U_T6_MCA_MY2020_Rx" SG_ 1084 BSBattQDeltaRideAh 1;
BA_ "U_P702_MY2021_Rx" SG_ 1084 BSBattQDeltaRideAh 1;
BA_ "GenSigStartValueInteger" SG_ 1084 BSBattQDeltaRideAh 12800;
BA_ "U_T6_MCA_MY2020_Rx" SG_ 1084 BSBattQCapAh 1;
BA_ "U_P702_MY2021_Rx" SG_ 1084 BSBattQCapAh 1;
BA_ "U_T6_MCA_MY2020_Rx" SG_ 1068 EngStrtInhbt_B_RqBatt 1;
BA_ "U_P702_MY2021_Rx" SG_ 1068 EngStrtInhbt_B_RqBatt 1;
BA_ "U_T6_MCA_MY2020_Rx" SG_ 1068 BattULoChrg_D_Rq 1;
BA_ "U_P702_MY2021_Rx" SG_ 1068 BattULoChrg_D_Rq 1;
BA_ "CrossOver_InfoCAN" SG_ 1068 PwSysULoFalt_D_Stat 1;
BA_ "WakeupSignal" SG_ 1068 PwSysULoFalt_D_Stat 1;
BA_ "CrossOver_InfoCAN" SG_ 1068 Shed_T_Eng_Off_B 1;
BA_ "U_T6_MCA_MY2020_Rx" SG_ 1068 Shed_Feature_Group_ID 1;
BA_ "U_P702_MY2021_Rx" SG_ 1068 Shed_Feature_Group_ID 1;
BA_ "WakeupSignal" SG_ 1068 Shed_Feature_Group_ID 1;
BA_ "CrossOver_InfoCAN" SG_ 1068 Shed_Drain_Eng_Off_B 1;
BA_ "U_T6_MCA_MY2020_Rx" SG_ 1068 Shed_Level_Req 1;
BA_ "U_P702_MY2021_Rx" SG_ 1068 Shed_Level_Req 1;
BA_ "CrossOver_InfoCAN" SG_ 1068 Shed_Level_Req 1;
BA_ "WakeupSignal" SG_ 1068 Shed_Level_Req 1;
BA_ "U_T6_MCA_MY2020_Rx" SG_ 1068 ULoRgenTestMde_B_Rq 1;
BA_ "U_P702_MY2021_Rx" SG_ 1068 ULoRgenTestMde_B_Rq 1;
BA_ "U_T6_MCA_MY2020_Rx" SG_ 1068 ChargeMode 1;
BA_ "U_P702_MY2021_Rx" SG_ 1068 ChargeMode 1;
BA_ "CrossOver_InfoCAN" SG_ 1068 Batt_Lo_SoC_B 1;
BA_ "U_T6_MCA_MY2020_Rx" SG_ 1068 PeriodicElLoad_B_Stat 1;
BA_ "U_P702_MY2021_Rx" SG_ 1068 PeriodicElLoad_B_Stat 1;
BA_ "CrossOver_InfoCAN" SG_ 1068 Batt_Crit_SoC_B 1;
BA_ "U_CX727_MY2021_Rx" SG_ 146 VehVert2_A_Actl 1;
BA_ "U_T6_MCA_MY2020_Rx" SG_ 146 VehVert2_A_Actl 1;
BA_ "U_P702_MY2021_Rx" SG_ 146 VehVert2_A_Actl 1;
BA_ "GenSigStartValue" SG_ 146 VehVert2_A_Actl 8190;
BA_ "GenSigStartValueInteger" SG_ 146 VehVert2_A_Actl 8190;
BA_ "U_P702_MY2021_Rx" SG_ 146 VehLatLongVertA_No_Cs 1;
BA_ "U_CX727_MY2021_Rx" SG_ 146 VehLatLongVertA_No_Cs 1;
BA_ "MetaData" SG_ 146 VehLatLongVertA_No_Cs 1;
BA_ "U_P702_MY2021_Rx" SG_ 146 VehLatLongVert_No_Cnt 1;
BA_ "U_CX727_MY2021_Rx" SG_ 146 VehLatLongVert_No_Cnt 1;
BA_ "MetaData" SG_ 146 VehLatLongVert_No_Cnt 1;
BA_ "U_CX727_MY2021_Rx" SG_ 146 VehLong2_A_Actl 1;
BA_ "U_T6_MCA_MY2020_Rx" SG_ 146 VehLong2_A_Actl 1;
BA_ "U_P702_MY2021_Rx" SG_ 146 VehLong2_A_Actl 1;
BA_ "GenSigStartValue" SG_ 146 VehLong2_A_Actl 8190;
BA_ "GenSigStartValueInteger" SG_ 146 VehLong2_A_Actl 8190;
BA_ "U_CX727_MY2021_Rx" SG_ 146 VehLat2_A_Actl 1;
BA_ "U_T6_MCA_MY2020_Rx" SG_ 146 VehLat2_A_Actl 1;
BA_ "U_P702_MY2021_Rx" SG_ 146 VehLat2_A_Actl 1;
BA_ "GenSigStartValue" SG_ 146 VehLat2_A_Actl 8190;
BA_ "GenSigStartValueInteger" SG_ 146 VehLat2_A_Actl 8190;
BA_ "U_P702_MY2021_Rx" SG_ 146 VehVertAActl_D_Qf 1;
BA_ "U_CX727_MY2021_Rx" SG_ 146 VehVertAActl_D_Qf 1;
BA_ "GenSigStartValue" SG_ 146 VehVertAActl_D_Qf 1;
BA_ "MetaData" SG_ 146 VehVertAActl_D_Qf 1;
BA_ "GenSigStartValueInteger" SG_ 146 VehVertAActl_D_Qf 1;
BA_ "U_CX727_MY2021_Rx" SG_ 146 VehLongAActl_D_Qf 1;
BA_ "U_T6_MCA_MY2020_Rx" SG_ 146 VehLongAActl_D_Qf 1;
BA_ "U_P702_MY2021_Rx" SG_ 146 VehLongAActl_D_Qf 1;
BA_ "GenSigStartValue" SG_ 146 VehLongAActl_D_Qf 1;
BA_ "MetaData" SG_ 146 VehLongAActl_D_Qf 1;
BA_ "GenSigStartValueInteger" SG_ 146 VehLongAActl_D_Qf 1;
BA_ "U_P702_MY2021_Rx" SG_ 146 VehLatAActl_D_Qf 1;
BA_ "U_CX727_MY2021_Rx" SG_ 146 VehLatAActl_D_Qf 1;
BA_ "GenSigStartValue" SG_ 146 VehLatAActl_D_Qf 1;
BA_ "MetaData" SG_ 146 VehLatAActl_D_Qf 1;
BA_ "GenSigStartValueInteger" SG_ 146 VehLatAActl_D_Qf 1;
BA_ "GenSigSendType" SG_ 1900 TesterPhysicalResCCM 3;
BA_ "GenSigSendType" SG_ 1806 TesterPhysicalResIPMA 3;
BA_ "GenSigSendType" SG_ 997 PersIndexCcm_D_Actl 3;
BA_ "GenSigStartValue" SG_ 997 PersIndexCcm_D_Actl 4;
BA_ "GenSigStartValueInteger" SG_ 997 PersIndexCcm_D_Actl 4;
BA_ "CrossOver_InfoCAN" SG_ 997 PersIndexCcm_D_Actl 1;
BA_ "GenSigSendType" SG_ 997 FeatNoCcmActl 3;
BA_ "CrossOver_InfoCAN" SG_ 997 FeatNoCcmActl 1;
BA_ "GenSigSendType" SG_ 997 FeatConfigCcmActl 3;
BA_ "CrossOver_InfoCAN" SG_ 997 FeatConfigCcmActl 1;
BA_ "U_P702_MY2021_Rx" SG_ 983 CmbbObjRelLong_V_Actl 1;
BA_ "U_CX727_MY2021_Rx" SG_ 983 CmbbObjRelLong_V_Actl 1;
BA_ "GenSigStartValueInteger" SG_ 983 CmbbObjRelLong_V_Actl 1022;
BA_ "U_P702_MY2021_Rx" SG_ 983 CmbbObjRelLat_V_Actl 1;
BA_ "U_CX727_MY2021_Rx" SG_ 983 CmbbObjRelLat_V_Actl 1;
BA_ "GenSigStartValue" SG_ 983 CmbbObjRelLat_V_Actl 510;
BA_ "GenSigStartValueInteger" SG_ 983 CmbbObjRelLat_V_Actl 510;
BA_ "U_P702_MY2021_Rx" SG_ 983 CmbbObjDistLong_L_Actl 1;
BA_ "U_CX727_MY2021_Rx" SG_ 983 CmbbObjDistLong_L_Actl 1;
BA_ "GenSigStartValue" SG_ 983 CmbbObjDistLong_L_Actl 1022;
BA_ "GenSigStartValueInteger" SG_ 983 CmbbObjDistLong_L_Actl 1022;
BA_ "U_P702_MY2021_Rx" SG_ 983 CmbbObjDistLat_L_Actl 1;
BA_ "U_CX727_MY2021_Rx" SG_ 983 CmbbObjDistLat_L_Actl 1;
BA_ "GenSigStartValue" SG_ 983 CmbbObjDistLat_L_Actl 510;
BA_ "GenSigStartValueInteger" SG_ 983 CmbbObjDistLat_L_Actl 510;
BA_ "U_P702_MY2021_Rx" SG_ 983 CmbbObjConfdnc_D_Stat 1;
BA_ "U_CX727_MY2021_Rx" SG_ 983 CmbbObjConfdnc_D_Stat 1;
BA_ "U_P702_MY2021_Rx" SG_ 983 CmbbObjColl_T_Actl 1;
BA_ "U_CX727_MY2021_Rx" SG_ 983 CmbbObjColl_T_Actl 1;
BA_ "GenSigStartValue" SG_ 983 CmbbObjColl_T_Actl 125;
BA_ "GenSigStartValueInteger" SG_ 983 CmbbObjColl_T_Actl 126;
BA_ "U_P702_MY2021_Rx" SG_ 983 CmbbObjClass_D_Stat 1;
BA_ "U_CX727_MY2021_Rx" SG_ 983 CmbbObjClass_D_Stat 1;
BA_ "U_P702_MY2021_Rx" SG_ 983 EsaEnbl_D2_Rq 1;
BA_ "U_CX727_MY2021_Rx" SG_ 983 EsaEnbl_D2_Rq 1;
BA_ "U_P702_MY2021_Rx" SG_ 980 AdbBrdr1DistRigh_D_Stat 1;
BA_ "U_P702_MY2021_Rx" SG_ 980 AdbBrdr1DistLeft_D_Stat 1;
BA_ "U_P702_MY2021_Rx" SG_ 980 AdbMde1_D_Rq 1;
BA_ "U_P702_MY2021_Rx" SG_ 980 AdbIntns1_D_Rq 1;
BA_ "U_P702_MY2021_Rx" SG_ 980 AdbBrdr1Up_An_Rq 1;
BA_ "GenSigStartValue" SG_ 980 AdbBrdr1Up_An_Rq 509;
BA_ "GenSigStartValueInteger" SG_ 980 AdbBrdr1Up_An_Rq 510;
BA_ "U_P702_MY2021_Rx" SG_ 980 AdbBrdr1Right_An_Rq 1;
BA_ "GenSigStartValue" SG_ 980 AdbBrdr1Right_An_Rq 2046;
BA_ "GenSigStartValueInteger" SG_ 980 AdbBrdr1Right_An_Rq 2046;
BA_ "U_P702_MY2021_Rx" SG_ 980 AdbBrdr1Low_An_Rq 1;
BA_ "GenSigStartValue" SG_ 980 AdbBrdr1Low_An_Rq 509;
BA_ "GenSigStartValueInteger" SG_ 980 AdbBrdr1Low_An_Rq 510;
BA_ "U_P702_MY2021_Rx" SG_ 980 AdbBrdr1Left_An_Rq 1;
BA_ "GenSigStartValue" SG_ 980 AdbBrdr1Left_An_Rq 2046;
BA_ "GenSigStartValueInteger" SG_ 980 AdbBrdr1Left_An_Rq 2046;
BA_ "U_P702_MY2021_Rx" SG_ 980 AdbBrdr1CritRigh_T_Stat 1;
BA_ "U_P702_MY2021_Rx" SG_ 980 AdbBrdr1CritLeft_T_Stat 1;
BA_ "GenSigStartValueInteger" SG_ 976 SrpHghtRight_L_Actl 256;
BA_ "GenSigStartValueInteger" SG_ 976 SrpHghtLeft_L_Actl 256;
BA_ "GenSigSendType" SG_ 973 LaSysOffStat_D_Dsply 3;
BA_ "U_T6_MCA_MY2020_Tx" SG_ 973 LaSysOffStat_D_Dsply 1;
BA_ "GenSigSendType" SG_ 973 TsrVl2PrmntMsgTxt_D_Rq 3;
BA_ "GenSigSendType" SG_ 973 TsrVl1PrmntMsgTxt_D_Rq 3;
BA_ "GenSigSendType" SG_ 973 TsrVl2RstrcMsgTxt2_D_Rq 3;
BA_ "GenSigStartValue" SG_ 973 TsrVl2RstrcMsgTxt2_D_Rq 1;
BA_ "GenSigStartValueInteger" SG_ 973 TsrVl2RstrcMsgTxt2_D_Rq 1;
BA_ "GenSigSendType" SG_ 973 TsrVl1RstrcMsgTxt2_D_Rq 3;
BA_ "GenSigStartValue" SG_ 973 TsrVl1RstrcMsgTxt2_D_Rq 1;
BA_ "GenSigStartValueInteger" SG_ 973 TsrVl1RstrcMsgTxt2_D_Rq 1;
BA_ "GenSigSendType" SG_ 973 TsrOvtkMsgTxt2_D_Rq 3;
BA_ "GenSigSendType" SG_ 973 WwaWarn_B_Rq 3;
BA_ "GenSigSendType" SG_ 973 TsrVlUnitMsgTxt_D_Rq 3;
BA_ "GenSigStartValue" SG_ 973 TsrVlUnitMsgTxt_D_Rq 2;
BA_ "GenSigStartValueInteger" SG_ 973 TsrVlUnitMsgTxt_D_Rq 2;
BA_ "CrossOver_InfoCAN" SG_ 973 TsrVlUnitMsgTxt_D_Rq 1;
BA_ "GenSigSendType" SG_ 973 TsrVLim2MsgTxt_D_Rq 3;
BA_ "GenSigStartValue" SG_ 973 TsrVLim2MsgTxt_D_Rq 255;
BA_ "GenSigStartValueInteger" SG_ 973 TsrVLim2MsgTxt_D_Rq 255;
BA_ "CrossOver_InfoCAN" SG_ 973 TsrVLim2MsgTxt_D_Rq 1;
BA_ "GenSigSendType" SG_ 973 TsrVLim1MsgTxt_D_Rq 3;
BA_ "GenSigStartValue" SG_ 973 TsrVLim1MsgTxt_D_Rq 255;
BA_ "GenSigStartValueInteger" SG_ 973 TsrVLim1MsgTxt_D_Rq 255;
BA_ "CrossOver_InfoCAN" SG_ 973 TsrVLim1MsgTxt_D_Rq 1;
BA_ "GenSigSendType" SG_ 973 TsrVl2StatMsgTxt_D_Rq 3;
BA_ "CrossOver_InfoCAN" SG_ 973 TsrVl2StatMsgTxt_D_Rq 1;
BA_ "GenSigSendType" SG_ 973 TsrVl2RstrcMsgTxt_D_Rq 3;
BA_ "CrossOver_InfoCAN" SG_ 973 TsrVl2RstrcMsgTxt_D_Rq 1;
BA_ "GenSigSendType" SG_ 973 TsrVl1StatMsgTxt_D_Rq 3;
BA_ "CrossOver_InfoCAN" SG_ 973 TsrVl1StatMsgTxt_D_Rq 1;
BA_ "GenSigSendType" SG_ 973 TsrVl1RstrcMsgTxt_D_Rq 3;
BA_ "CrossOver_InfoCAN" SG_ 973 TsrVl1RstrcMsgTxt_D_Rq 1;
BA_ "GenSigSendType" SG_ 973 TsrStatMsgTxt_D_Rq 3;
BA_ "CrossOver_InfoCAN" SG_ 973 TsrStatMsgTxt_D_Rq 1;
BA_ "GenSigSendType" SG_ 973 TsrOvtkStatMsgTxt_D_Rq 3;
BA_ "CrossOver_InfoCAN" SG_ 973 TsrOvtkStatMsgTxt_D_Rq 1;
BA_ "GenSigSendType" SG_ 973 TsrOvtkMsgTxt_D_Rq 3;
BA_ "GenSigStartValue" SG_ 973 TsrOvtkMsgTxt_D_Rq 1;
BA_ "GenSigStartValueInteger" SG_ 973 TsrOvtkMsgTxt_D_Rq 1;
BA_ "CrossOver_InfoCAN" SG_ 973 TsrOvtkMsgTxt_D_Rq 1;
BA_ "GenSigSendType" SG_ 973 TsrOswWarnMsgTxt_D_Rq 3;
BA_ "GenSigStartValue" SG_ 973 TsrOswWarnMsgTxt_D_Rq 1;
BA_ "GenSigStartValueInteger" SG_ 973 TsrOswWarnMsgTxt_D_Rq 1;
BA_ "CrossOver_InfoCAN" SG_ 973 TsrOswWarnMsgTxt_D_Rq 1;
BA_ "GenSigSendType" SG_ 973 TsrMsgTxt_D_Rq 3;
BA_ "GenSigStartValue" SG_ 973 TsrMsgTxt_D_Rq 1;
BA_ "GenSigStartValueInteger" SG_ 973 TsrMsgTxt_D_Rq 1;
BA_ "CrossOver_InfoCAN" SG_ 973 TsrMsgTxt_D_Rq 1;
BA_ "U_P702_MY2021_Rx" SG_ 970 LkaDrvOvrrd_D_Rq 1;
BA_ "U_P702_MY2021_Rx" SG_ 970 LkaActvStats_D2_Req 1;
BA_ "U_CX727_MY2021_Rx" SG_ 970 LkaActvStats_D2_Req 1;
BA_ "U_P702_MY2021_Rx" SG_ 970 LaRefAng_No_Req 1;
BA_ "U_CX727_MY2021_Rx" SG_ 970 LaRefAng_No_Req 1;
BA_ "GenSigStartValueInteger" SG_ 970 LaRefAng_No_Req 2048;
BA_ "U_P702_MY2021_Rx" SG_ 970 LaRampType_B_Req 1;
BA_ "U_CX727_MY2021_Rx" SG_ 970 LaRampType_B_Req 1;
BA_ "U_P702_MY2021_Rx" SG_ 970 LaCurvature_No_Calc 1;
BA_ "U_CX727_MY2021_Rx" SG_ 970 LaCurvature_No_Calc 1;
BA_ "GenSigStartValueInteger" SG_ 970 LaCurvature_No_Calc 2048;
BA_ "U_P702_MY2021_Rx" SG_ 970 LdwActvStats_D_Req 1;
BA_ "U_CX727_MY2021_Rx" SG_ 970 LdwActvStats_D_Req 1;
BA_ "U_P702_MY2021_Rx" SG_ 970 LdwActvIntns_D_Req 1;
BA_ "U_CX727_MY2021_Rx" SG_ 970 LdwActvIntns_D_Req 1;
BA_ "CrossOver_InfoCAN" SG_ 970 LdwActvIntns_D_Req 1;
BA_ "GenSigSendType" SG_ 962 AdbBrdr3DistRigh_D_Stat 3;
BA_ "U_P702_MY2021_Rx" SG_ 962 AdbBrdr3DistRigh_D_Stat 1;
BA_ "GenSigSendType" SG_ 962 AdbBrdr3DistLeft_D_Stat 3;
BA_ "U_P702_MY2021_Rx" SG_ 962 AdbBrdr3DistLeft_D_Stat 1;
BA_ "U_P702_MY2021_Rx" SG_ 962 AdbMde3_D_Rq 1;
BA_ "GenSigSendType" SG_ 962 AdbMde3_D_Rq 3;
BA_ "U_P702_MY2021_Rx" SG_ 962 AdbIntns3_D_Rq 1;
BA_ "GenSigSendType" SG_ 962 AdbIntns3_D_Rq 3;
BA_ "U_P702_MY2021_Rx" SG_ 962 AdbBrdr3Up_An_Rq 1;
BA_ "GenSigStartValue" SG_ 962 AdbBrdr3Up_An_Rq 509;
BA_ "GenSigStartValueInteger" SG_ 962 AdbBrdr3Up_An_Rq 510;
BA_ "U_P702_MY2021_Rx" SG_ 962 AdbBrdr3Right_An_Rq 1;
BA_ "GenSigStartValue" SG_ 962 AdbBrdr3Right_An_Rq 2046;
BA_ "GenSigStartValueInteger" SG_ 962 AdbBrdr3Right_An_Rq 2046;
BA_ "U_P702_MY2021_Rx" SG_ 962 AdbBrdr3Low_An_Rq 1;
BA_ "GenSigStartValue" SG_ 962 AdbBrdr3Low_An_Rq 509;
BA_ "GenSigStartValueInteger" SG_ 962 AdbBrdr3Low_An_Rq 510;
BA_ "U_P702_MY2021_Rx" SG_ 962 AdbBrdr3Left_An_Rq 1;
BA_ "GenSigStartValue" SG_ 962 AdbBrdr3Left_An_Rq 2046;
BA_ "GenSigStartValueInteger" SG_ 962 AdbBrdr3Left_An_Rq 2046;
BA_ "U_P702_MY2021_Rx" SG_ 962 AdbBrdr3CritRigh_T_Stat 1;
BA_ "U_P702_MY2021_Rx" SG_ 962 AdbBrdr3CritLeft_T_Stat 1;
BA_ "GenSigSendType" SG_ 961 AdbBrdr2DistRigh_D_Stat 3;
BA_ "U_P702_MY2021_Rx" SG_ 961 AdbBrdr2DistRigh_D_Stat 1;
BA_ "GenSigSendType" SG_ 961 AdbBrdr2DistLeft_D_Stat 3;
BA_ "U_P702_MY2021_Rx" SG_ 961 AdbBrdr2DistLeft_D_Stat 1;
BA_ "U_P702_MY2021_Rx" SG_ 961 AdbMde2_D_Rq 1;
BA_ "GenSigSendType" SG_ 961 AdbMde2_D_Rq 3;
BA_ "U_P702_MY2021_Rx" SG_ 961 AdbIntns2_D_Rq 1;
BA_ "GenSigSendType" SG_ 961 AdbIntns2_D_Rq 3;
BA_ "U_P702_MY2021_Rx" SG_ 961 AdbBrdr2Up_An_Rq 1;
BA_ "GenSigStartValue" SG_ 961 AdbBrdr2Up_An_Rq 509;
BA_ "GenSigStartValueInteger" SG_ 961 AdbBrdr2Up_An_Rq 510;
BA_ "U_P702_MY2021_Rx" SG_ 961 AdbBrdr2Right_An_Rq 1;
BA_ "GenSigStartValue" SG_ 961 AdbBrdr2Right_An_Rq 2046;
BA_ "GenSigStartValueInteger" SG_ 961 AdbBrdr2Right_An_Rq 2046;
BA_ "U_P702_MY2021_Rx" SG_ 961 AdbBrdr2Low_An_Rq 1;
BA_ "GenSigStartValue" SG_ 961 AdbBrdr2Low_An_Rq 509;
BA_ "GenSigStartValueInteger" SG_ 961 AdbBrdr2Low_An_Rq 510;
BA_ "U_P702_MY2021_Rx" SG_ 961 AdbBrdr2Left_An_Rq 1;
BA_ "GenSigStartValue" SG_ 961 AdbBrdr2Left_An_Rq 2046;
BA_ "GenSigStartValueInteger" SG_ 961 AdbBrdr2Left_An_Rq 2046;
BA_ "U_P702_MY2021_Rx" SG_ 961 AdbBrdr2CritRigh_T_Stat 1;
BA_ "U_P702_MY2021_Rx" SG_ 961 AdbBrdr2CritLeft_T_Stat 1;
BA_ "GenSigSendType" SG_ 394 HaDsply_No_Cs 3;
BA_ "ContentDependant" SG_ 394 HaDsply_No_Cs 1;
BA_ "MetaData" SG_ 394 HaDsply_No_Cs 1;
BA_ "GenSigSendType" SG_ 394 HaDsply_No_Cnt 3;
BA_ "ContentDependant" SG_ 394 HaDsply_No_Cnt 1;
BA_ "MetaData" SG_ 394 HaDsply_No_Cnt 1;
BA_ "GenSigSendType" SG_ 394 AccStopStat_D_Dsply 3;
BA_ "GenSigSendType" SG_ 394 AccTrgDist2_D_Dsply 3;
BA_ "CrossOver_InfoCAN" SG_ 394 AccTrgDist2_D_Dsply 1;
BA_ "GenSigSendType" SG_ 394 AccStopRes_B_Dsply 3;
BA_ "CrossOver_InfoCAN" SG_ 394 AccStopRes_B_Dsply 1;
BA_ "GenSigSendType" SG_ 394 TjaWarn_D_Rq 3;
BA_ "GenSigSendType" SG_ 394 Tja_D_Stat 3;
BA_ "GenSigSendType" SG_ 394 TjaMsgTxt_D_Dsply 3;
BA_ "GenSigSendType" SG_ 394 IaccLamp_D_Rq 3;
BA_ "GenSigSendType" SG_ 394 AccMsgTxt_D2_Rq 3;
BA_ "GenSigSendType" SG_ 394 FcwDeny_B_Dsply 3;
BA_ "CrossOver_InfoCAN" SG_ 394 FcwDeny_B_Dsply 1;
BA_ "ECGUsedRxSignal" SG_ 394 FcwMemStat_B_Actl 1;
BA_ "GenSigSendType" SG_ 394 FcwMemStat_B_Actl 3;
BA_ "CrossOver_InfoCAN" SG_ 394 FcwMemStat_B_Actl 1;
BA_ "GenSigSendType" SG_ 394 AccTGap_B_Dsply 3;
BA_ "CrossOver_InfoCAN" SG_ 394 AccTGap_B_Dsply 1;
BA_ "GenSigSendType" SG_ 394 CadsAlignIncplt_B_Actl 3;
BA_ "CrossOver_InfoCAN" SG_ 394 CadsAlignIncplt_B_Actl 1;
BA_ "GenSigSendType" SG_ 394 AccFllwMde_B_Dsply 3;
BA_ "CrossOver_InfoCAN" SG_ 394 AccFllwMde_B_Dsply 1;
BA_ "GenSigSendType" SG_ 394 CadsRadrBlck_B_Actl 3;
BA_ "CrossOver_InfoCAN" SG_ 394 CadsRadrBlck_B_Actl 1;
BA_ "GenSigSendType" SG_ 394 CmbbPostEvnt_B_Dsply 3;
BA_ "CrossOver_InfoCAN" SG_ 394 CmbbPostEvnt_B_Dsply 1;
BA_ "GenSigSendType" SG_ 394 AccStopMde_B_Dsply 3;
BA_ "CrossOver_InfoCAN" SG_ 394 AccStopMde_B_Dsply 1;
BA_ "ECGUsedRxSignal" SG_ 394 FcwMemSens_D_Actl 1;
BA_ "GenSigSendType" SG_ 394 FcwMemSens_D_Actl 3;
BA_ "CrossOver_InfoCAN" SG_ 394 FcwMemSens_D_Actl 1;
BA_ "GenSigSendType" SG_ 394 FcwMsgTxt_D_Rq 3;
BA_ "CrossOver_InfoCAN" SG_ 394 FcwMsgTxt_D_Rq 1;
BA_ "GenSigSendType" SG_ 394 AccWarn_D_Dsply 3;
BA_ "CrossOver_InfoCAN" SG_ 394 AccWarn_D_Dsply 1;
BA_ "GenSigSendType" SG_ 394 FcwVisblWarn_B_Rq 3;
BA_ "CrossOver_InfoCAN" SG_ 394 FcwVisblWarn_B_Rq 1;
BA_ "ECGUsedRxSignal" SG_ 394 FcwAudioWarn_B_Rq 1;
BA_ "GenSigSendType" SG_ 394 FcwAudioWarn_B_Rq 3;
BA_ "CrossOver_InfoCAN" SG_ 394 FcwAudioWarn_B_Rq 1;
BA_ "GenSigSendType" SG_ 394 AccTGap_D_Dsply 3;
BA_ "GenSigStartValue" SG_ 394 AccTGap_D_Dsply 3;
BA_ "GenSigStartValueInteger" SG_ 394 AccTGap_D_Dsply 3;
BA_ "CrossOver_InfoCAN" SG_ 394 AccTGap_D_Dsply 1;
BA_ "GenSigSendType" SG_ 394 AccMemEnbl_B_RqDrv 3;
BA_ "GenSigStartValue" SG_ 394 AccMemEnbl_B_RqDrv 1;
BA_ "GenSigStartValueInteger" SG_ 394 AccMemEnbl_B_RqDrv 1;
BA_ "CrossOver_InfoCAN" SG_ 394 AccMemEnbl_B_RqDrv 1;
BA_ "U_P702_MY2021_Rx" SG_ 391 CmbbBrkDecel_No_Cnt 1;
BA_ "U_CX727_MY2021_Rx" SG_ 391 CmbbBrkDecel_No_Cnt 1;
BA_ "MetaData" SG_ 391 CmbbBrkDecel_No_Cnt 1;
BA_ "U_P702_MY2021_Rx" SG_ 391 CmbbBrkDecel_No_Cs 1;
BA_ "U_CX727_MY2021_Rx" SG_ 391 CmbbBrkDecel_No_Cs 1;
BA_ "MetaData" SG_ 391 CmbbBrkDecel_No_Cs 1;
BA_ "U_P702_MY2021_Rx" SG_ 391 CmbbBrkDecel_A_Rq 1;
BA_ "U_CX727_MY2021_Rx" SG_ 391 CmbbBrkDecel_A_Rq 1;
BA_ "GenSigStartValueInteger" SG_ 391 CmbbBrkDecel_A_Rq 5129;
BA_ "ECGUsedRxSignal" SG_ 391 CmbbBrkPrchg_D_Rq 1;
BA_ "U_P702_MY2021_Rx" SG_ 391 CmbbBrkPrchg_D_Rq 1;
BA_ "U_CX727_MY2021_Rx" SG_ 391 CmbbBrkPrchg_D_Rq 1;
BA_ "ECGUsedRxSignal" SG_ 391 CmbbBrkDecel_B_Rq 1;
BA_ "U_P702_MY2021_Rx" SG_ 391 CmbbBrkDecel_B_Rq 1;
BA_ "U_CX727_MY2021_Rx" SG_ 391 CmbbBrkDecel_B_Rq 1;
BA_ "U_P702_MY2021_Rx" SG_ 391 CmbbBaSens_D_Rq 1;
BA_ "U_CX727_MY2021_Rx" SG_ 391 CmbbBaSens_D_Rq 1;
BA_ "U_P702_MY2021_Rx" SG_ 390 AccBrkTot_A_Rq 1;
BA_ "U_CX727_MY2021_Rx" SG_ 390 AccBrkTot_A_Rq 1;
BA_ "GenSigStartValueInteger" SG_ 390 AccBrkTot_A_Rq 5129;
BA_ "U_T6_MCA_MY2020_Rx" SG_ 390 AccPrpl_A_Pred 1;
BA_ "U_P702_MY2021_Rx" SG_ 390 AccPrpl_A_Pred 1;
BA_ "U_T6_MCA_MY2020_Rx" SG_ 390 AccVeh_V_Trg 1;
BA_ "U_P702_MY2021_Rx" SG_ 390 AccVeh_V_Trg 1;
BA_ "U_P702_MY2021_Rx" SG_ 390 AccBrkPrkEl_B_Rq 1;
BA_ "U_CX727_MY2021_Rx" SG_ 390 AccBrkPrkEl_B_Rq 1;
BA_ "U_P702_MY2021_Rx" SG_ 390 CmbbDeny_B_Actl 1;
BA_ "U_CX727_MY2021_Rx" SG_ 390 CmbbDeny_B_Actl 1;
BA_ "U_T6_MCA_MY2020_Rx" SG_ 390 CmbbEngTqMn_B_Rq 1;
BA_ "U_P702_MY2021_Rx" SG_ 390 CmbbEngTqMn_B_Rq 1;
BA_ "U_T6_MCA_MY2020_Rx" SG_ 390 AccPrpl_A_Rq 1;
BA_ "U_P702_MY2021_Rx" SG_ 390 AccPrpl_A_Rq 1;
BA_ "U_T6_MCA_MY2020_Rx" SG_ 390 AccDeny_B_Rq 1;
BA_ "U_P702_MY2021_Rx" SG_ 390 AccDeny_B_Rq 1;
BA_ "U_T6_MCA_MY2020_Rx" SG_ 390 AccResumEnbl_B_Rq 1;
BA_ "U_P702_MY2021_Rx" SG_ 390 AccResumEnbl_B_Rq 1;
BA_ "WakeupSignal" SG_ 390 AccResumEnbl_B_Rq 1;
BA_ "U_T6_MCA_MY2020_Rx" SG_ 390 AccCancl_B_Rq 1;
BA_ "U_P702_MY2021_Rx" SG_ 390 AccCancl_B_Rq 1;
BA_ "U_P702_MY2021_Rx" SG_ 390 AccBrkPrchg_B_Rq 1;
BA_ "U_CX727_MY2021_Rx" SG_ 390 AccBrkPrchg_B_Rq 1;
BA_ "U_P702_MY2021_Rx" SG_ 390 AccBrkDecel_B_Rq 1;
BA_ "U_CX727_MY2021_Rx" SG_ 390 AccBrkDecel_B_Rq 1;
BA_ "U_T6_MCA_MY2020_Rx" SG_ 390 AccStopStat_B_Rq 1;
BA_ "U_P702_MY2021_Rx" SG_ 390 AccStopStat_B_Rq 1;
BA_ "U_CX727_MY2021_Rx" SG_ 390 AccStopStat_B_Rq 1;
BA_ "U_P702_MY2021_Tx" SG_ 1441 TCCM_GWOnBoardTester 1;
BA_ "GenSigStartValue" SG_ 1441 TCCM_GWOnBoardTester 255;
BA_ "ContentDependant" SG_ 1441 TCCM_GWOnBoardTester 1;
BA_ "GenSigStartValueInteger" SG_ 1441 TCCM_GWOnBoardTester 255;
BA_ "U_P702_MY2021_Tx" SG_ 1441 TCCM_GWNMProxy 1;
BA_ "GenSigStartValue" SG_ 1441 TCCM_GWNMProxy 255;
BA_ "ContentDependant" SG_ 1441 TCCM_GWNMProxy 1;
BA_ "GenSigStartValueInteger" SG_ 1441 TCCM_GWNMProxy 255;
BA_ "U_P702_MY2021_Tx" SG_ 1441 TCCM_AutoSarNMReserved4 1;
BA_ "GenSigStartValue" SG_ 1441 TCCM_AutoSarNMReserved4 255;
BA_ "ContentDependant" SG_ 1441 TCCM_AutoSarNMReserved4 1;
BA_ "GenSigStartValueInteger" SG_ 1441 TCCM_AutoSarNMReserved4 255;
BA_ "U_P702_MY2021_Tx" SG_ 1441 TCCM_AutoSarNMReserved3 1;
BA_ "GenSigStartValue" SG_ 1441 TCCM_AutoSarNMReserved3 255;
BA_ "ContentDependant" SG_ 1441 TCCM_AutoSarNMReserved3 1;
BA_ "GenSigStartValueInteger" SG_ 1441 TCCM_AutoSarNMReserved3 255;
BA_ "U_P702_MY2021_Tx" SG_ 1441 TCCM_AutoSarNMReserved2 1;
BA_ "GenSigStartValue" SG_ 1441 TCCM_AutoSarNMReserved2 255;
BA_ "ContentDependant" SG_ 1441 TCCM_AutoSarNMReserved2 1;
BA_ "GenSigStartValueInteger" SG_ 1441 TCCM_AutoSarNMReserved2 255;
BA_ "U_P702_MY2021_Tx" SG_ 1441 TCCM_AutoSarNMReserved1 1;
BA_ "GenSigStartValue" SG_ 1441 TCCM_AutoSarNMReserved1 255;
BA_ "ContentDependant" SG_ 1441 TCCM_AutoSarNMReserved1 1;
BA_ "GenSigStartValueInteger" SG_ 1441 TCCM_AutoSarNMReserved1 255;
BA_ "U_P702_MY2021_Tx" SG_ 1441 TCCM_AutoSarNMNodeId 1;
BA_ "GenSigStartValue" SG_ 1441 TCCM_AutoSarNMNodeId 161;
BA_ "ContentDependant" SG_ 1441 TCCM_AutoSarNMNodeId 1;
BA_ "GenSigStartValueInteger" SG_ 1441 TCCM_AutoSarNMNodeId 161;
BA_ "U_P702_MY2021_Tx" SG_ 1441 TCCM_AutoSarNMControl 1;
BA_ "ContentDependant" SG_ 1441 TCCM_AutoSarNMControl 1;
BA_ "GenSigSendType" SG_ 1787 TesterPhysicalResSODCMD 3;
BA_ "GenSigSendType" SG_ 1779 TesterPhysicalReqSODCMD 3;
BA_ "GenSigSendType" SG_ 1786 TesterPhysicalResSODCMC 3;
BA_ "GenSigSendType" SG_ 1778 TesterPhysicalReqSODCMC 3;
BA_ "GenSigSendType" SG_ 942 PrkAidRdiusRight_L_Dsply 3;
BA_ "GenSigSendType" SG_ 942 PrkAidRdiusLeft_L_Dsply 3;
BA_ "GenSigSendType" SG_ 942 PrkAidDrvDir_D_Stat 3;
BA_ "GenSigSendType" SG_ 942 PrkAidAcsyRear_D_Stat 3;
BA_ "GenSigSendType" SG_ 942 PrkAidAcsyFront_D_Stat 3;
BA_ "GenSigSendType" SG_ 930 BalrWndwRight_B_Stat 3;
BA_ "GenSigSendType" SG_ 930 BalrSnsRight_D_Falt 3;
BA_ "GenSigSendType" SG_ 930 WndwPsngrRear_D_RqBalrr 3;
BA_ "GenSigSendType" SG_ 930 WndwPsngr_D_RqBalrr 3;
BA_ "GenSigSendType" SG_ 930 WndwDrvRear_D_RqBalrr 3;
BA_ "GenSigSendType" SG_ 930 WndwDrv_D_RqBalrr 3;
BA_ "GenSigSendType" SG_ 930 BalrRight_D_Stat 3;
BA_ "GenSigStartValue" SG_ 930 BalrRight_D_Stat 2;
BA_ "GenSigStartValueInteger" SG_ 930 BalrRight_D_Stat 2;
BA_ "GenSigSendType" SG_ 930 BalrMdeSelRight_B_Stat 3;
BA_ "GenSigSendType" SG_ 930 BalrMdeRight_D_Stat 3;
BA_ "GenSigStartValue" SG_ 930 BalrMdeRight_D_Stat 1;
BA_ "GenSigStartValueInteger" SG_ 930 BalrMdeRight_D_Stat 1;
BA_ "GenSigSendType" SG_ 930 BalrLckRight_B_Stat 3;
BA_ "GenSigSendType" SG_ 930 BalrChimeRight_D_Rq 3;
BA_ "GenSigSendType" SG_ 930 CamraRearOn_B_RqBalrr 3;
BA_ "GenSigSendType" SG_ 930 DrLckCnt_No_ActlBalrr 3;
BA_ "GenSigSendType" SG_ 930 DrLckActv_B_RqBalrr 3;
BA_ "GenSigSendType" SG_ 929 BalrChimeLeft_D_Rq 3;
BA_ "GenSigSendType" SG_ 929 BalrLeft_D_Stat 3;
BA_ "GenSigStartValue" SG_ 929 BalrLeft_D_Stat 2;
BA_ "GenSigStartValueInteger" SG_ 929 BalrLeft_D_Stat 2;
BA_ "GenSigSendType" SG_ 929 BalrWndwLeft_B_Stat 3;
BA_ "GenSigSendType" SG_ 929 WndwPsngrRear_D_RqBalrl 3;
BA_ "GenSigSendType" SG_ 929 WndwPsngr_D_RqBalrl 3;
BA_ "GenSigSendType" SG_ 929 WndwDrvRear_D_RqBalrl 3;
BA_ "GenSigSendType" SG_ 929 WndwDrv_D_RqBalrl 3;
BA_ "GenSigSendType" SG_ 929 BalrSnsLeft_D_Falt 3;
BA_ "GenSigSendType" SG_ 929 BalrMdeSelLeft_B_Stat 3;
BA_ "GenSigSendType" SG_ 929 BalrMdeLeft_D_Stat 3;
BA_ "GenSigStartValue" SG_ 929 BalrMdeLeft_D_Stat 1;
BA_ "GenSigStartValueInteger" SG_ 929 BalrMdeLeft_D_Stat 1;
BA_ "GenSigSendType" SG_ 929 BalrLckLeft_B_Stat 3;
BA_ "GenSigSendType" SG_ 929 CamraRearOn_B_RqBalrl 3;
BA_ "GenSigSendType" SG_ 929 DrLckCnt_No_ActlBalrl 3;
BA_ "GenSigSendType" SG_ 929 DrLckActv_B_RqBalrl 3;
BA_ "CrossOver_InfoCAN" SG_ 402 ApaMdeStat_D_RqDrv 1;
BA_ "CrossOver_InfoCAN" SG_ 402 CamraZoomMan_D_Rq 1;
BA_ "CrossOver_InfoCAN" SG_ 402 CamraOvrlStat_D_Rq 1;
BA_ "CrossOver_InfoCAN" SG_ 402 CamraOvrlDyn_D_Rq 1;
BA_ "CrossOver_InfoCAN" SG_ 402 CamAutoTowbarZoom 1;
BA_ "CrossOver_InfoCAN" SG_ 402 DistanceBarSetting 1;
BA_ "U_P702_MY2021_Rx" SG_ 924 DcacOut_Pw_Mx 1;
BA_ "GenSigStartValue" SG_ 924 DcacOut_Pw_Mx 2046;
BA_ "U_P702_MY2021_Rx" SG_ 924 DcacOut2_Pw_Actl 1;
BA_ "GenSigStartValue" SG_ 924 DcacOut2_Pw_Actl 8190;
BA_ "U_P702_MY2021_Rx" SG_ 924 DcacOut1_Pw_Actl 1;
BA_ "GenSigStartValue" SG_ 924 DcacOut1_Pw_Actl 8190;
BA_ "U_P702_MY2021_Rx" SG_ 924 DcacIn_Pw_Mx 1;
BA_ "GenSigStartValue" SG_ 924 DcacIn_Pw_Mx 2046;
BA_ "GenSigStartValue" SG_ 923 DcacIn_U2_Actl 4094;
BA_ "U_P702_MY2021_Rx" SG_ 923 DcacIn_U_Actl 1;
BA_ "GenSigStartValue" SG_ 923 DcacIn_U_Actl 4094;
BA_ "U_P702_MY2021_Rx" SG_ 923 DcacIn_I_Actl 1;
BA_ "GenSigStartValue" SG_ 923 DcacIn_I_Actl 2046;
BA_ "U_P702_MY2021_Rx" SG_ 923 Dcac_Te_Actl 1;
BA_ "GenSigStartValue" SG_ 923 Dcac_Te_Actl 254;
BA_ "GenSigSendType" SG_ 1998 TesterPhysicalResSODR 3;
BA_ "GenSigSendType" SG_ 1996 TesterPhysicalResSODL 3;
BA_ "GenSigSendType" SG_ 1988 TesterPhysicalReqSODL 3;
BA_ "U_P702_MY2021_Rx" SG_ 922 DcacPlugPrsnt_B_Stat 1;
BA_ "GenSigStartValue" SG_ 922 DcacPlugPrsnt_B_Stat 1;
VAL_ 90 TrnGsmNtmState_D_Actl 3 "Faulty" 2 "Neutral_Tow_Mode" 1 "Car_Wash_Mode" 0 "None" ;
VAL_ 90 DrQltyDrv_D_StatGsm 7 "Faulty" 6 "NoDataExists" 5 "NotUsed2" 4 "NotUsed1" 3 "ClosedDegraded" 2 "OpenDegraded" 1 "ClosedOkay" 0 "OpenOkay" ;
VAL_ 90 TrnBtsiOvrrd_B_Stat 1 "Override" 0 "Null" ;
VAL_ 90 GsmGearMsgTxt_D_Rq 3 "Message3" 2 "Message2" 1 "Message1" 0 "NoMessage" ;
VAL_ 90 TrnRng_D_RqGsm 15 "Fault" 14 "UnknownPosition" 13 "Undefined_2" 12 "Undefined_1" 11 "_6" 10 "_5" 9 "_4" 8 "_3" 7 "_2" 6 "_1" 5 "Low" 4 "Sport_DriveSport" 3 "Drive" 2 "Neutral" 1 "Reverse" 0 "Park" ;
VAL_ 90 PrkBrkActv_D_RqGsmGear 3 "NotUsed" 2 "RequestParkBrakeEngage" 1 "NoRequest" 0 "Null" ;
VAL_ 90 TrnValidGearRq_D_Stat 3 "Valid_Request" 2 "Valid_Degraded_Request" 1 "Invalid_Request" 0 "No_Request" ;
VAL_ 90 TrnGearButtn_U_Actl 255 "Fault" ;
VAL_ 90 TrnGearButtn_B_ActlR2 1 "Yes" 0 "No" ;
VAL_ 90 TrnGearButtn_B_ActlR1 1 "Yes" 0 "No" ;
VAL_ 90 TrnGearButtn_B_ActlR0 1 "Yes" 0 "No" ;
VAL_ 90 TrnGearButtn_B_ActlP2 1 "Yes" 0 "No" ;
VAL_ 90 TrnGearButtn_B_ActlP1 1 "Yes" 0 "No" ;
VAL_ 90 TrnGearButtn_B_ActlP0 1 "Yes" 0 "No" ;
VAL_ 90 TrnGearButtn_B_ActlN2 1 "Yes" 0 "No" ;
VAL_ 90 TrnGearButtn_B_ActlN1 1 "Yes" 0 "No" ;
VAL_ 90 TrnGearButtn_B_ActlN0 1 "Yes" 0 "No" ;
VAL_ 90 TrnGearButtn_B_ActlM2 1 "Yes" 0 "No" ;
VAL_ 90 TrnGearButtn_B_ActlM1 1 "Yes" 0 "No" ;
VAL_ 90 TrnGearButtn_B_ActlM0 1 "Yes" 0 "No" ;
VAL_ 90 TrnGearButtn_B_ActlD2 1 "Yes" 0 "No" ;
VAL_ 90 TrnGearButtn_B_ActlD1 1 "Yes" 0 "No" ;
VAL_ 90 TrnGearButtn_B_ActlD0 1 "Yes" 0 "No" ;
VAL_ 90 TrnGear_D_RqDrv 31 "Fault" 30 "NotUsed_25" 29 "NotUsed_24" 28 "NotUsed_23" 27 "NotUsed_22" 26 "Return_to_Park" 25 "NotUsed_20" 24 "NotUsed_19" 23 "NotUsed_18" 22 "NotUsed_17" 21 "Return_To_Park" 20 "NotUsed_15" 19 "NotUsed_14" 18 "NotUsed_13" 17 "NotUsed_12" 16 "Manual" 15 "Not_Used11" 14 "Not_Used10" 13 "NotUsed_9" 12 "NotUsed_8" 11 "NotUsed_7" 10 "NotUsed_6" 9 "NotUsed_5" 8 "Drive" 7 "NotUsed_4" 6 "NotUsed_3" 5 "NotUsed_2" 4 "Neutral" 3 "NotUsed_1" 2 "Reverse" 1 "Park" 0 "No_Gear" ;
VAL_ 90 BrkSwtchPos_B_ActlGsm 1 "Yes" 0 "No" ;
VAL_ 1091 ParkLampTrlrOut_B_Stat 1 "Out" 0 "Null" ;
VAL_ 1091 TrlrLampCtl_D_Stat 3 "NotUsed" 2 "TrlrLampCnnctDrvFailure" 1 "TrlrLampNotCnnctDrvFailure" 0 "Null" ;
VAL_ 1091 TrlrBattChrg_D_Stat 3 "Reverse" 2 "Normal" 1 "Low" 0 "Null" ;
VAL_ 1091 StopLampTrlrOut_B_Stat 1 "Out" 0 "Null" ;
VAL_ 1091 TurnLampTrlrRr_B_Stat 1 "Out" 0 "Null" ;
VAL_ 1091 TurnLampTrlrRl_B_Stat 1 "Out" 0 "Null" ;
VAL_ 1091 TrlrLampCnnct_B_Actl 1 "Yes" 0 "No" ;
VAL_ 138 SteWhlRelCalib_An_Sns 32767 "Fault" 32766 "NoDataExists" ;
VAL_ 131 AccButtnGapDecPress 1 "Button_Pressed" 0 "Button_Not_Pressed" ;
VAL_ 131 HeadLghtHiCtrl_D_RqAhb 7 "NotUsed2" 6 "NotUsed1" 5 "Auto_HiBeam" 4 "Auto_LoBeam" 3 "Flash" 2 "Man_HiBeam" 1 "Man_LoBeam" 0 "Null" ;
VAL_ 131 AhbStat_B_Dsply 1 "On" 0 "Off" ;
VAL_ 131 WiprFrontSwtch_D_Stat 15 "NotUsed6" 14 "NotUsed5" 13 "NotUsed4" 12 "NotUsed3" 11 "NotUsed2" 10 "NotUsed1" 9 "PositionNotDetermined" 8 "High" 7 "Low" 6 "Position6" 5 "Position5" 4 "Position4" 3 "Position3" 2 "Position2" 1 "Position1" 0 "Off" ;
VAL_ 131 HeadLghtHiOn_B_StatAhb 1 "On" 0 "Off" ;
VAL_ 131 HeadLghtHiFlash_D_Actl 3 "NotUsed" 2 "High" 1 "Flash_to_Pass" 0 "Null" ;
VAL_ 131 TjaButtnOnOffPress 1 "Pressed" 0 "Not_Pressed" ;
VAL_ 131 AccButtnGapTogglePress 1 "Pressed" 0 "Not_Pressed" ;
VAL_ 131 HeadLghtHiFlash_D_Stat 3 "NotUsed" 2 "High" 1 "Flash_to_Pass" 0 "Null" ;
VAL_ 131 WiprFront_D_Stat 15 "NO_DATA_EXISTS" 14 "STALLED" 13 "RESERVED" 12 "AUTO_ADJUST" 11 "COURTESYWIPE" 10 "AUTO_HIGH" 9 "AUTO_LOW" 8 "WASH" 7 "MIST_FLICK" 6 "MAN_HIGH" 5 "MAN_LOW" 4 "MAN_INT_ON" 3 "MAN_INT_OFF" 2 "OFF_MOVING" 1 "AUTO_OFF" 0 "OFF" ;
VAL_ 131 TurnLghtSwtch_D_Stat 3 "Unused_Treat_As_Off" 2 "Right" 1 "Left" 0 "Off" ;
VAL_ 131 LghtAmb_D_Sns 7 "No_Data_Exists" 6 "Unused2" 5 "Unused1" 4 "Tunnel_Off" 3 "Tunnel_On" 2 "Twilight" 1 "Light" 0 "Dark" ;
VAL_ 131 AccButtnGapIncPress 1 "Button_Pressed" 0 "Button_Not_Pressed" ;
VAL_ 131 AslButtnOnOffPress 1 "Button_Pressed" 0 "Button_Not_Pressed" ;
VAL_ 131 AslButtnOnOffCnclPress 1 "Button_Pressed" 0 "Button_Not_Pressed" ;
VAL_ 131 CcButtnOnPress 1 "Button_Pressed" 0 "Button_Not_Pressed" ;
VAL_ 131 CcButtnOnOffPress 1 "Button_Pressed" 0 "Button_Not_Pressed" ;
VAL_ 131 CcButtnOnOffCnclPress 1 "Button_Pressed" 0 "Button_Not_Pressed" ;
VAL_ 131 CcButtnOffPress 1 "Button_Pressed" 0 "Button_Not_Pressed" ;
VAL_ 131 CcAsllButtnResPress 1 "Button_Pressed" 0 "Button_Not_Pressed" ;
VAL_ 131 CcAslButtnSetPress 1 "Button_Pressed" 0 "Button_Not_Pressed" ;
VAL_ 131 CcAslButtnSetIncPress 1 "Button_Pressed" 0 "Button_Not_Pressed" ;
VAL_ 131 CcAslButtnSetDecPress 1 "Button_Pressed" 0 "Button_Not_Pressed" ;
VAL_ 131 CcAslButtnResIncPress 1 "Button_Pressed" 0 "Button_Not_Pressed" ;
VAL_ 131 CcAslButtnResDecPress 1 "Button_Pressed" 0 "Button_Not_Pressed" ;
VAL_ 131 CcAslButtnOnPress 1 "Button_Pressed" 0 "Button_Not_Pressed" ;
VAL_ 131 CcAslButtnOnOffCncl 1 "Button_Pressed" 0 "Button_Not_Pressed" ;
VAL_ 131 CcAslButtnOffCnclPress 1 "Button_Pressed" 0 "Button_Not_Pressed" ;
VAL_ 131 CcAslButtnIndxIncPress 1 "Button_Pressed" 0 "Button_Not_Pressed" ;
VAL_ 131 CcAslButtnIndxDecPress 1 "Button_Pressed" 0 "Button_Not_Pressed" ;
VAL_ 131 CcAslButtnDeny_B_Actl 1 "Yes" 0 "No" ;
VAL_ 131 CcAslButtnCnclResPress 1 "Button_Pressed" 0 "Button_Not_Pressed" ;
VAL_ 131 CcAslButtnCnclPress 1 "Button_Pressed" 0 "Button_Not_Pressed" ;
VAL_ 131 LaSwtchPos_D_Stat 3 "Fault" 2 "Unused" 1 "Pressed" 0 "Open" ;
VAL_ 787 DrTgateChime2_D_Rq 7 "NotUsed3" 6 "NotUsed2" 5 "NotUsed1" 4 "Long_Repeated" 3 "Fast" 2 "Short" 1 "Long" 0 "Off" ;
VAL_ 787 DrTGate_D_Rq 3 "NotUsed" 2 "Closing" 1 "Opening" 0 "Not_Moving" ;
VAL_ 787 PwLftgtIntSw_B_Stat 1 "Pressed" 0 "Null" ;
VAL_ 787 Power_Liftgate_Mode_Stt 2 "Unused" 3 "Not_Supported" 1 "Enabled" 0 "Disabled" ;
VAL_ 953 BattRgenLoDChrg_D_Rq 3 "DoNotCare" 2 "Retain" 1 "Closed" 0 "Open" ;
VAL_ 953 BattRgenLoChrg_D_Rq 3 "DoNotCare" 2 "Retain" 1 "Closed" 0 "Open" ;
VAL_ 953 ChrgCordLck_B_Stat 1 "Unlock" 0 "Null" ;
VAL_ 953 WakeAlarm3_D_Stat 3 "PublisherReset" 2 "Wake" 1 "AlarmRunning" 0 "AlarmOff" ;
VAL_ 953 WakeAlarm2_D_Stat 3 "PublisherReset" 2 "Wake" 1 "AlarmRunning" 0 "AlarmOff" ;
VAL_ 953 WakeAlarm1_D_Stat 3 "PublisherReset" 2 "Wake" 1 "AlarmRunning" 0 "AlarmOff" ;
VAL_ 953 WakeAlarm0_D_Stat 3 "PublisherReset" 2 "Wake" 1 "AlarmRunning" 0 "AlarmOff" ;
VAL_ 1093 TrlBrkInitOut_D_Stat 3 "Heavy" 2 "Medium" 1 "Light" 0 "Null" ;
VAL_ 1093 TrlrBrkMde_D_Actl 1 "Electric_Over_Hydraulic" 0 "Electric" ;
VAL_ 1093 TrlrBrkDsply_B_Rq 1 "Yes" 0 "No" ;
VAL_ 1093 TrlrBrkDcnnt_B_Actl 1 "Yes" 0 "No" ;
VAL_ 1093 TrlrBrkActCnnct_B_Actl 1 "Yes" 0 "No" ;
VAL_ 1093 StopLamp_B_RqTrlrBrk 1 "Yes" 0 "No" ;
VAL_ 1093 TrlrBrkCtl_B_Falt 1 "Yes" 0 "No" ;
VAL_ 1093 TrlrBrkActCirct_B_Falt 1 "Yes" 0 "No" ;
VAL_ 792 ElTrip_L_Dsply 65535 "Fault" 65534 "No_Data_Exists" ;
VAL_ 792 ElLongTerm_L_Dsply 16777215 "Fault" 16777214 "No_Data_Exists" ;
VAL_ 968 SlMde_D_Rq 3 "IsaNotConfigured" 2 "Manual_Mode" 1 "Auto_Mode" 0 "Null" ;
VAL_ 968 IsaOffst_D_Rq 15 "Faulty" 14 "Null" 13 "Thirteen" 12 "Twelve" 11 "Eleven" 10 "Ten" 9 "Nine" 8 "Eight" 7 "Seven" 6 "Six" 5 "Five" 4 "Four" 3 "Three" 2 "Two" 1 "One" 0 "Zero" ;
VAL_ 819 Memory_3_SwPsngr_Stat 1 "Pressed" 0 "Null" ;
VAL_ 819 Memory_2_SwPsngr_Stat 1 "Pressed" 0 "Null" ;
VAL_ 819 Memory_1_SwPsngr_Stat 1 "Pressed" 0 "Null" ;
VAL_ 819 BLISLEDStatPassSide 3 "Fault" 2 "Unused" 1 "On" 0 "Off" ;
VAL_ 819 WndwPsngrSide_D_Stat 3 "BothWindow_Operating" 2 "RearWindow_Operating" 1 "FrontWindow_Operating" 0 "NoWindows_Operating" ;
VAL_ 819 Pasngr_Lock_Sw_Stat 3 "Invalid" 2 "Unlock" 1 "Lock" 0 "Null" ;
VAL_ 819 ChildLckFdbckRp_B_Stat 1 "Locked" 0 "Unlock" ;
VAL_ 818 BLISLEDStatDriverSide 3 "Fault" 2 "Unused" 1 "On" 0 "Off" ;
VAL_ 818 WndwDrvSide_D_Stat 3 "BothWindow_Operating" 2 "RearWindow_Operating" 1 "FrontWindow_Operating" 0 "NoWindows_Operating" ;
VAL_ 818 KeyCylSwDrvDr_D_Stat 3 "NotUsed" 2 "Unlock" 1 "Lock" 0 "Null" ;
VAL_ 818 Driver_Lock_Sw_Stat 3 "Invalid" 2 "Unlock" 1 "Lock" 0 "Null" ;
VAL_ 818 ChildLckPw_D_Rq 1 "Active" 0 "Null" ;
VAL_ 818 ChildLckFdbckRd_B_Stat 1 "Locked" 0 "Unlock" ;
VAL_ 818 RvrseMirrorChime_B_Rq 1 "Yes" 0 "No" ;
VAL_ 806 SnowPlowMde_B_Enbl 1 "Enable" 0 "Disable" ;
VAL_ 806 StopStrtDrvMde_B_RqBtn 1 "Pressed" 0 "Not_Pressed" ;
VAL_ 806 ClimtHeat_D_Rq 7 "NotUsed4" 6 "NotUsed3" 5 "HtrCoreClntFlwOnly" 4 "PtcHtrTestMde" 3 "Defrost_Defog" 2 "FastTempPullDownHeatingReq" 1 "OpportunisticHeatingReq" 0 "NoHeatingRequest" ;
VAL_ 806 ClimtCool_D_Rq 7 "NotUsed4" 6 "NotUsed3" 5 "NotUsed2" 4 "ElACTestMde" 3 "Defrost_Defog" 2 "FastTempPullDownCoolReq" 1 "OpportunisticCoolingReq" 0 "NoCoolingRequest" ;
VAL_ 806 HvacEvap_Te_Actl 1023 "Fault" ;
VAL_ 806 HvacAirCond_B_Rq 1 "Yes" 0 "No" ;
VAL_ 806 ClimtPw_B_Rq 1 "Yes" 0 "No" ;
VAL_ 765 Mc_VehTimeFrmtUsrSel_St 2 "24h_mode" 1 "12h_mode" 0 "Invalid" ;
VAL_ 765 Running_Board_Cmd 3 "Unused" 2 "Manually_Deployed" 1 "All_Enabled" 0 "All_Disabled" ;
VAL_ 765 EngExhMdeQuiet_D2_Rq 7 "NotUsed_3" 6 "NotUsed_2" 5 "NotUsed_1" 4 "Track" 3 "Sport" 2 "Normal" 1 "Stealth" 0 "Null" ;
VAL_ 765 EdmSailMde_B_RqDrv 1 "On" 0 "Off" ;
VAL_ 765 DrvInputRequired_B_Rq 1 "Yes" 0 "No" ;
VAL_ 765 AwdRnge_D_ActlIpc 7 "Unknown" 6 "High_Range_2wd" 5 "High_Range_Auto" 4 "High_Range_Locked" 3 "Neutral" 2 "Low_Range_2wd" 1 "Low_Range_Auto" 0 "Low_Range_Locked" ;
VAL_ 765 BalrSwtch_D_Stat 3 "NotUsed" 2 "Pressed" 1 "NotPressed" 0 "Null" ;
VAL_ 765 BalrMde_D_Rq 3 "High" 2 "Medium" 1 "Low" 0 "Null" ;
VAL_ 765 WaitToStartLamp_D_Falt 3 "NotUsed" 2 "Wait_to_start_lamp_failed" 1 "Diagnosis_not_ready" 0 "Wait_to_start_lamp_OK" ;
VAL_ 765 EsaOn_B_Rq 1 "On" 0 "Off" ;
VAL_ 765 BttOn_B_Rq 1 "On" 0 "Off" ;
VAL_ 765 Btt_L_Actl 127 "Faulty" 126 "NoDataExists" ;
VAL_ 765 SelDrvMdeTxtReset_B_Rq 1 "Yes" 0 "No" ;
VAL_ 765 SelDrvMdeDsply_B_Avail 1 "Available" 0 "NotAvailable" ;
VAL_ 765 Mc_VehUntTrpCoUsrSel_St 0 "TripComputer_metric" 1 "TripComputer_imperial" ;
VAL_ 765 Mc_VehUnitTempUsrSel_St 0 "Temperature_deg_c" 1 "Temperature_deg_f" ;
VAL_ 765 Mc_VehLangUsrSel_St 32 "Indian_English" 31 "Thai" 30 "Slovak" 29 "Arabic" 28 "Taiwanese" 27 "Mandarin_Chinese" 26 "Korean" 25 "AU_English" 24 "Japanese" 23 "Braz_Portuguese" 22 "EU_Portuguese" 21 "Finish" 20 "Norwegian" 19 "Danish" 18 "Swedish" 17 "Hungarian" 16 "Greek" 15 "Czech" 14 "Polish" 13 "Flemish" 12 "Dutch" 11 "Russian" 10 "Turkish" 9 "Mex_Spanish" 8 "EU_Spanish" 7 "Cana_French" 6 "EU_French" 5 "Italian" 4 "German" 3 "NA_English" 2 "UK_English" 1 "Unknown" 0 "Invalid" ;
VAL_ 934 CtaAlrtLeft2_D_Stat 7 "NotUsed3" 6 "NotUsed2" 5 "NotUsed1" 4 "AlertZone4" 3 "AlertZone3" 2 "AlertZone2" 1 "AlertZone1" 0 "Off" ;
VAL_ 934 CtaBrkLeftMsgTxt_B_Rq 1 "Enable" 0 "Disable" ;
VAL_ 934 CtaLeftBrkDecel_B_Rq 1 "Enable" 0 "Disable" ;
VAL_ 934 CtaLeftBrkEnbl_B_Rq 1 "Enable" 0 "Disable" ;
VAL_ 934 BttLeft_D_Stat 7 "NotUsed" 6 "Disabled" 5 "Off" 4 "OffTemp" 3 "NotConnected" 2 "Pending" 1 "Connected" 0 "NotDetermined" ;
VAL_ 934 BttLeft_D_RqDrv 3 "NotUsed" 2 "Request" 1 "NoRequest" 0 "Null" ;
VAL_ 934 CtaSnsLeft_D_Stat 3 "Invalid" 2 "System_Failure" 1 "Blocked" 0 "Clear" ;
VAL_ 934 SodDetctLeft_D_Stat 4 "Sensor_Blocked" 3 "Sensor_Fault" 2 "Flash_On" 1 "Alert_On" 0 "AlertOff_FlashOff_SensrClr" ;
VAL_ 934 CtaLeft_D_Stat 7 "NotUsed_3" 6 "NotUsed_2" 5 "NotUsed_1" 4 "Invalid" 3 "Disabled" 2 "On" 1 "Trailer_Tow_Off" 0 "Off" ;
VAL_ 934 CtaAlrtLeft_D_Stat 1 "On" 0 "Off" ;
VAL_ 934 SodLeft_D_Stat 7 "NotUsed_3" 6 "NotUsed_2" 5 "NotUsed_1" 4 "Invalid" 3 "Disabled" 2 "On" 1 "Trailer_Tow_Off" 0 "Off" ;
VAL_ 934 SodSnsLeft_D_Stat 3 "Second_Warning_Audio" 2 "System_Failure" 1 "Blocked" 0 "Clear" ;
VAL_ 934 SodAlrtLeft_D_Stat 3 "Bulb_Proveout" 2 "Flash" 1 "On" 0 "Off" ;
VAL_ 1072 LscmbbStat_B_Actl 1 "On" 0 "Off" ;
VAL_ 1072 HaDsplyCpblty_B_Stat 1 "Available" 0 "NotAvailable" ;
VAL_ 1072 AccDeny_B_RqIpc 1 "Yes" 0 "No" ;
VAL_ 1072 DrvSlipCtlMde_D_Rq 3 "App_Specific_Off_Mode_3" 2 "App_Specific_Off_Mode_2" 1 "App_Specific_Off_Mode_1" 0 "Default_Mode" ;
VAL_ 1072 EngIdlShutDown_B_RqDrv 1 "Inhibit" 0 "No_Inibit" ;
VAL_ 1072 HsaMde_D_Rq 3 "Undefined" 2 "Manual" 1 "Automatic" 0 "Off" ;
VAL_ 1072 NtrlTowMdeEnbl_B_RqDrv 1 "Yes" 0 "No" ;
VAL_ 1072 BulbChkActv_B_Stat 1 "Active" 0 "Inactive" ;
VAL_ 1072 ParkDetect_Stat 1 "Park" 0 "Not_Park" ;
VAL_ 1072 ReducedGuard_D_Rq 3 "NotUsed" 2 "On" 1 "Off" 0 "Null" ;
VAL_ 1072 TrlrBrkMde_D_Rq 1 "ElectricOverHydraulic" 0 "Electric" ;
VAL_ 1072 TRLR_SWAY_CONFIG_CMD 1 "On" 0 "Off" ;
VAL_ 1072 TRAILER_BRAKE_CONFIG 1 "Yes" 0 "No" ;
VAL_ 1072 Power_Liftgate_Mode_Cmd 1 "Enable" 0 "Disable" ;
VAL_ 1072 AccEnbl_B_RqDrv 1 "Adaptive_Cruise" 0 "Normal_Cruise" ;
VAL_ 1072 OdometerMasterValue 16777215 "Invalid" ;
VAL_ 1072 EngOilLife_B_RqReset 1 "Yes" 0 "No" ;
VAL_ 1072 ePRNDL_MODE 1 "On" 0 "Off" ;
VAL_ 1072 DrvSlipCtlMde_B_Rq2 1 "Pressed" 0 "Not_Pressed" ;
VAL_ 1072 MetricActv_B_Actl 1 "Active" 0 "Inactive" ;
VAL_ 1072 KeyTypeChngMykey_D_Rq 3 "Search_PE_BackupSlot" 2 "Clear_All_MyKeys" 1 "Request_New_MyKey" 0 "None" ;
VAL_ 1072 ManRgen_D_Rq 3 "NotUsed2" 2 "NotUsed1" 1 "CustInitManExhFilterClean" 0 "No_Customer_Request" ;
VAL_ 909 IgnPsswrdDsply_B_Rq 1 "Active" 0 "Inactive" ;
VAL_ 909 ElPwPoint_D_Rq 3 "On" 2 "Off2" 1 "Off1" 0 "Null" ;
VAL_ 909 PoliceIdlMde_D_Stat 15 "NotUsed_7" 14 "NotUsed_6" 13 "NotUsed_5" 12 "NotUsed_4" 11 "NotUsed_3" 10 "UtilityIdleActive" 9 "PepsActive" 8 "Decommissioned" 7 "ActiveFault" 6 "ArmFault" 5 "PrearmedFault" 4 "OffFault" 3 "Active" 2 "Arm" 1 "Prearmed" 0 "Off" ;
VAL_ 909 DrLatchMsgTxt_D_Rq 7 "Message7" 6 "Message6" 5 "Message5" 4 "Message4" 3 "Message3" 2 "Message2" 1 "Message1" 0 "NoMessage" ;
VAL_ 909 SecurityMsgTxt_D_Rq 3 "Message3" 2 "Message2" 1 "Message1" 0 "NoMessage" ;
VAL_ 909 PrmtrAlrmEvnt_D_Stat 15 "Diag_Tamper" 14 "Trailer" 13 "Shock_Sensor" 12 "Post_Crash" 11 "Panic" 10 "Intrusion" 9 "Inclination" 8 "Ign_Tamper" 7 "LG_Door" 6 "Decklid" 5 "Hood" 4 "PR_Door" 3 "PF_Door" 2 "DR_Door" 1 "DF_Door" 0 "Null" ;
VAL_ 909 HeadLghtHiPrmsn_D_Stat 3 "CancelAndSuppress" 2 "Cancel" 1 "Hold" 0 "AllowChange" ;
VAL_ 909 SteWhlLckMsgTxt_D_Rq 3 "NotUsed" 2 "Message_2" 1 "Message_1" 0 "No_Message" ;
VAL_ 909 immoMsgTxt_D_Rq 15 "Immo_Msg_15" 14 "Immo_Msg_14" 13 "Immo_Msg_13" 12 "Immo_Msg_12" 11 "Immo_Msg_11" 10 "Immo_Msg_10" 9 "Immo_Msg_9" 8 "Immo_Msg_8" 7 "Immo_Msg_7" 6 "Immo_Msg_6" 5 "Immo_Msg_5" 4 "Immo_Msg_4" 3 "Immo_Msg_3" 2 "Immo_Msg_2" 1 "Immo_Msg_1" 0 "Immo_Msg_0_Null" ;
VAL_ 909 PrsnlDevcChrgEnbl_B_Rq 1 "Active" 0 "Inactive" ;
VAL_ 909 TracKeyMde_D_Stat 3 "NotUsed" 2 "NotActive" 1 "Active" 0 "ModeNotDetermined" ;
VAL_ 909 PEBackupSlot_Stats 3 "No_Valid_FOB_In_Slot" 2 "MyKey_FOB_In_Slot" 1 "Standard_FOB_In_Slot" 0 "Null" ;
VAL_ 909 KeyMykeyTot_No_Cnt 13 "Thirteen" 12 "Twelve" 11 "Eleven" 10 "Ten" 9 "Nine" 8 "Eight" 7 "Seven" 6 "Six" 5 "Five" 4 "Four" 3 "Three" 2 "Two" 1 "One" 0 "Zero" 15 "Invalid" 14 "Unlimited" ;
VAL_ 909 KeyAdmnTot_No_Cnt 13 "Thirteen" 12 "Twelve" 11 "Eleven" 10 "Ten" 9 "Nine" 8 "Eight" 7 "Seven" 6 "Six" 5 "Five" 4 "Four" 3 "Three" 2 "Two" 1 "One" 0 "Zero" 15 "Invalid" 14 "Unlimited" ;
VAL_ 963 Illuminated_Entry_Stat 3 "Invalid" 2 "Unknown" 1 "On" 0 "Off" ;
VAL_ 963 Dr_Courtesy_Light_Stat 3 "Invalid" 2 "Unknown" 1 "On" 0 "Off" ;
VAL_ 963 Courtesy_Delay_Status 3 "Invalid" 2 "Unknown" 1 "On" 0 "Off" ;
VAL_ 963 ImpactEvntFdbck_D_Stat 3 "NotUsed" 2 "EventComplete" 1 "EventInProgress" 0 "Normal" ;
VAL_ 963 WrlssAcsyChrgInhbt_B_Rq 1 "Yes" 0 "No" ;
VAL_ 963 PudLampPsngr_D_Rq 3 "Ramp_Down" 2 "Ramp_Up" 1 "On" 0 "Off" ;
VAL_ 963 HeadLampLoOut_B_Stat 1 "Out" 0 "Null" ;
VAL_ 963 HeadLghtHiFdbck_D_Stat 3 "NotUsed" 2 "Cancel" 1 "Hold" 0 "Allow_Change" ;
VAL_ 963 PudLampDrv_D_Rq 3 "Ramp_Down" 2 "Ramp_Up" 1 "On" 0 "Off" ;
VAL_ 963 TrnNotInPrkChime_B_Rq 1 "On" 0 "Off" ;
VAL_ 963 PrkLightChime_B_Rq 1 "On" 0 "Off" ;
VAL_ 963 KeyInIgnWarn_B_Cmd 1 "On" 0 "Off" ;
VAL_ 963 HomeSafeLtChime_B_Rq 1 "On" 0 "Off" ;
VAL_ 963 StopLghtOn_B_Stat 1 "On" 0 "Off" ;
VAL_ 963 RvrseLghtOn_B_Stat 1 "On" 0 "Off" ;
VAL_ 963 PrkLght_D_Stat 3 "Park_Both" 2 "Park_Right" 1 "Park_Left" 0 "Off" ;
VAL_ 963 HeadLghtSwtch_D_Stat 3 "Autolamp" 2 "Headlamp" 1 "Parklamp" 0 "Off" ;
VAL_ 963 HeadLampLoFrOn_B_Stat 1 "Low" 0 "Not_Low" ;
VAL_ 963 HeadLampLoFlOn_B_Stat 1 "Low" 0 "Not_Low" ;
VAL_ 963 HeadLampLoActv_B_Stat 1 "On" 0 "Off" ;
VAL_ 963 Headlamp_On_Wrning_Cmd 1 "On" 0 "Off" ;
VAL_ 963 Park_Brake_Chime_Rqst 1 "On" 0 "Off" ;
VAL_ 963 HeadLghtHiOn_B_Stat 1 "On" 0 "Off" ;
VAL_ 963 BrkWarnInd_B_Rq 1 "On" 0 "Off" ;
VAL_ 963 Brk_Fluid_Lvl_Low 3 "Invalid" 2 "Unknown" 1 "Low" 0 "OK" ;
VAL_ 963 ReducedGuard_D_Stat 3 "NotUsed" 2 "Alarm_On" 1 "Alarm_Off_Previously_On" 0 "Alarm_Off" ;
VAL_ 963 Perimeter_Alarm_Status 3 "Activated" 2 "Armed" 1 "Prearmed" 0 "Disarmed" ;
VAL_ 963 Courtesy_BSave_Stat 3 "Invalid" 2 "Unknown" 1 "No_Effect" 0 "Off" ;
VAL_ 963 DrTgateLck_D_Stat 3 "NotUsed" 2 "Unlock" 1 "Lock" 0 "Null" ;
VAL_ 963 WndwGlbl_D_Cmd 7 "NotUsed3" 6 "NotUsed2" 5 "NotUsed1" 4 "GLEARN" 3 "GCLOSE" 2 "GOPEN" 1 "GSTOP" 0 "Null" ;
VAL_ 963 PudLamp_D_Rq 3 "RAMP_DOWN" 2 "RAMP_UP" 1 "ON" 0 "OFF" ;
VAL_ 963 DayRnngLampOn_B_Stat 1 "On" 0 "Off" ;
VAL_ 963 PerimeterAlarmChimeRq 1 "On" 0 "Off" ;
VAL_ 145 VehYawWActl_D_Qf 3 "OK" 2 "Not_Within_Specifications" 1 "No_Data_Exists" 0 "Faulty" ;
VAL_ 145 VehRolWActl_D_Qf 3 "OK" 2 "Not_Within_Specifications" 1 "No_Data_Exists" 0 "Faulty" ;
VAL_ 145 VehYaw_W_Actl 65535 "Faulty" 65534 "NoDataExists" ;
VAL_ 145 VehRol_W_Actl 65535 "Faulty" 65534 "NoDataExists" ;
VAL_ 76 FirstRowBuckleMid 3 "Unknown" 2 "Unbelted" 1 "Belted" 0 "Faulty" ;
VAL_ 76 SecondRowBucklePsngr 3 "Unknown" 2 "Unbelted" 1 "Belted" 0 "Faulty" ;
VAL_ 76 SecondRowBuckleMid 3 "Unknown" 2 "Unbelted" 1 "Belted" 0 "Faulty" ;
VAL_ 76 SecondRowBuckleDriver 3 "Unknown" 2 "Unbelted" 1 "Belted" 0 "Faulty" ;
VAL_ 76 FirstRowBuckleDriver 3 "Unknown" 2 "Unbelted" 1 "Belted" 0 "Faulty" ;
VAL_ 76 RILReq 3 "Not_Used" 2 "Plant_Mode" 1 "On" 0 "Off" ;
VAL_ 76 FirstRowBucklePsngr 3 "Unknown" 2 "Unbelted" 1 "Belted" 0 "Faulty" ;
VAL_ 76 RstrnImpactEvntStatus 7 "Invalid" 6 "Not_Used_4" 5 "Threshold_2_Exceeded" 4 "Not_Used_3" 3 "Threshold_1_Exceeded" 2 "Not_Used_2" 1 "Not_Used_1" 0 "Normal" ;
VAL_ 76 PsngrFrntDetct_D_Actl 3 "Unknown" 2 "Empty" 0 "Faulty" 1 "Occupied" ;
VAL_ 76 EDRTriggerEvntSync 1 "Threshold_Exceeded" 0 "Normal" ;
VAL_ 76 PassRstrnInd_Req 3 "ABOnNotIllum_OffNotIllum" 2 "AirbagOnNot_Illum_OffIllum" 1 "AirbagOn_Illum_OffNotIllum" 0 "AirbagOn_Illum_Off_Illum" ;
VAL_ 65 immoControlCmd_T1 0 "IDLE" 1 "MOTIVE_START_RQST" 2 "NONMOTIVE_START_RQST" 3 "RQST_TARGET1_IDBLOCK1" 4 "RQST_TARGET1_IDBLOCK2" 5 "Unused" 6 "ECHO_TARGET1_IDBLOCK2" 7 "SHUTDOWN" ;
VAL_ 1076 HILL_DESC_SW 1 "On" 0 "Off" ;
VAL_ 1076 AutoRgen_D_Rq 3 "NotUsed" 2 "AutExhFilterCleanOFF" 1 "AutExhFilterCleanON" 0 "No_Mode_Selected" ;
VAL_ 1076 W2S_LAMP_OK 1 "Yes" 0 "No" ;
VAL_ 1076 OdoTripRx_B_Actl 1 "Yes" 0 "No" ;
VAL_ 1076 DrvSlipCtlMde_B_RqMyKey 1 "On" 0 "Off" ;
VAL_ 1076 FuelLvlWarn_D_Actl 3 "NotUsed" 2 "VeryLow" 1 "Low" 0 "OK" ;
VAL_ 1076 FuelSecndActv_B_Actl 1 "Yes" 0 "No" ;
VAL_ 1076 FUEL_SENSOR_NUM 1 "Dual_Sensors" 0 "Single_Sensor" ;
VAL_ 862 AutoStpHvacDelta_I_Est 255 "Fault" ;
VAL_ 862 HvacBlwrFront_D_Stat 31 "Not_Used" 20 "Full_On" 19 "95_Percent" 18 "90_Percent" 17 "85_Percent" 16 "80_Percent" 15 "75_Percent" 14 "70_Percent" 13 "65_Percent" 12 "60_Percent" 11 "55_Percent" 10 "50_Percent" 9 "45_Percent" 8 "40_Percent" 7 "35_Percent" 6 "30_Percent" 5 "25_Percent" 4 "20_Percent" 3 "15_Percent" 2 "10_Percent" 1 "5_Percent" 0 "Off" ;
VAL_ 862 CabnAmb_Te_Actl 255 "Fault" ;
VAL_ 862 ClimtThrmlLoad_No_Actl 255 "Fault" ;
VAL_ 931 PtWakeReas_D_Stat 15 "NotUsed_9" 14 "NotUsed_8" 13 "NotUsed_7" 12 "NotUsed_6" 11 "NotUsed_5" 10 "NotUsed_4" 9 "NotUsed_3" 8 "NotUsed_2" 7 "NotUsed_1" 6 "ElapsedTime" 5 "ThirdPartyWakeup" 4 "DoorAjar" 3 "EarlyWake" 2 "NonMotiveStart" 1 "MotiveStart" 0 "Null" ;
VAL_ 931 VehOnSrc_D_Stat 15 "NotUsed_11" 14 "NotUsed_10" 13 "NotUsed_9" 12 "NotUsed_8" 11 "NotUsed_7" 10 "NotUsed_6" 9 "NotUsed_5" 8 "NotUsed_4" 7 "SecureIdle" 6 "FleetVehicleInhibit" 5 "StolenVehicleInhibit" 4 "OverTheAir" 3 "RemoteParkAssist" 2 "RemoteStart" 1 "Manual" 0 "Off" ;
VAL_ 931 EngStrtActv_B_Stat 1 "Active" 0 "Inactive" ;
VAL_ 931 EngStrt_B_Rq 1 "Request" 0 "NoRequest" ;
VAL_ 931 DrvInCtl_B_Stat 1 "Yes" 0 "No" ;
VAL_ 931 AdvStrt_D_Stat 15 "NotUsed_15" 14 "NotUsed_14" 13 "NotUsed_13" 12 "NotUsed_12" 11 "NotUsed_11" 10 "NotUsed_10" 9 "NotUsed_9" 8 "NotUsed_8" 7 "NotUsed_7" 6 "NotUsed_6" 5 "NotUsed_5" 4 "NotUsed_4" 3 "NotUsed_3" 2 "NotUsed_2" 1 "NotUsed_1" 0 "NoAction" ;
VAL_ 931 CrnkInhbt_B_Stat 1 "Inhibit" 0 "NoInhibit" ;
VAL_ 931 IgnPreOffActv_B_Stat 1 "Active" 0 "Inactive" ;
VAL_ 578 PtLatchActv_B_RqBcm 1 "On" 0 "Off" ;
VAL_ 578 immoSecureIdleMode 3 "NotUsed2" 2 "NotUsed1" 1 "Active" 0 "Inactive" ;
VAL_ 578 ReFuelSwtchStat_D_Actl 3 "NotUsed2" 2 "NotUsed1" 1 "On" 0 "Off" ;
VAL_ 578 FuelPumpPwr_D_Stat 7 "NotUsed3" 6 "NotUsed2" 5 "NotUsed1" 4 "Power_Off_Default" 3 "Power_Off_Command" 2 "Power_Off_Service" 1 "Power_Off_Impact" 0 "Power_On" ;
VAL_ 578 BattULo_U_Actl 255 "Fault" ;
VAL_ 578 PrkLckCtl_B_Enbl 1 "Enable" 0 "Disable" ;
VAL_ 578 PrkLckCtlMsgTxt_D_Rq 3 "BTSI_DI_3" 2 "BTSI_DI_2" 1 "BTSI_DI_1" 0 "Null_BTSI_DI" ;
VAL_ 578 BrkTrnShifLck_B_Stat 1 "Shift" 0 "NoShift" ;
VAL_ 578 PrkLckCtlUnlck_D_Stat 3 "Trans_And_Steer_Unlckd" 2 "Steering_Unlckd" 1 "Transmission_Unlckd" 0 "Null" ;
VAL_ 578 PrkLckCtlTow_B_Enbl 1 "Enable" 0 "Disable" ;
VAL_ 578 DriverCrankingReq 1 "Crank_Request" 0 "No_Crank_Request" ;
VAL_ 578 EngOff_T_Actl 65535 "Invalid" ;
VAL_ 578 DcacElPw_D_Rq 3 "NotUsed" 2 "AC_HighPower_Requested" 1 "AC_LowPower_Requested" 0 "AC_Power_NotRequested" ;
VAL_ 578 BattULo_I_Actl 16383 "Fault" ;
VAL_ 947 ValetMode_D_Mem 1 "On" 0 "Off" ;
VAL_ 947 DrStatDrvErrCnt_B_Stat 1 "Yes" 0 "No" ;
VAL_ 947 TurnLghtRight_D_Rq 3 "Seq" 2 "On" 1 "Off" 0 "Null" ;
VAL_ 947 TurnLghtRightOn_B_Stat 1 "On" 0 "Off" ;
VAL_ 947 TurnLghtLeftOn_B_Stat 1 "On" 0 "Off" ;
VAL_ 947 FogLghtRearOn_B_Stat 1 "On" 0 "Off" ;
VAL_ 947 Backlit_LED_Status 15 "Unused3" 14 "Unused2" 13 "Unused1" 12 "Night_12" 11 "Night_11" 10 "Night_10" 9 "Night_9" 8 "Night_8" 7 "Night_7" 6 "Night_6" 5 "Night_5" 4 "Night_4" 3 "Night_3" 2 "Night_2" 1 "Night_1" 0 "Off" ;
VAL_ 947 TurnLghtLeft_D_Rq 3 "Seq" 2 "On" 1 "Off" 0 "Null" ;
VAL_ 947 FogLghtFrontOn_B_Stat 1 "On" 0 "Off" ;
VAL_ 947 IgnKeyType_D_Actl 15 "Invalid" 14 "Unknown" 3 "Key_Not_Prgrm_Read_Failure" 2 "Key_In_Ign_My_Key" 1 "Key_In_Ign_Standard_Key" 0 "Key_Read_In_Progress" ;
VAL_ 947 Parklamp_Status 3 "Invalid" 2 "Unknown" 1 "On" 0 "Off" ;
VAL_ 947 Litval 255 "Invalid" 254 "Unknown" 5 "Day" 4 "Twilight_4" 3 "Twilight_3" 2 "Twilight_2" 1 "Twilight_1" 0 "Night" ;
VAL_ 947 Key_In_Ignition_Stat 1 "In" 0 "Out" ;
VAL_ 947 Ignition_Status 0 "Unknown" 1 "Off" 15 "Invalid" 8 "Start" 4 "Run" 2 "Accessory" ;
VAL_ 947 Dimming_Lvl 255 "Invalid" 254 "Unknown" 18 "Day_6" 17 "Day_5" 16 "Day_4" 15 "Day_3" 14 "Day_2" 13 "Day_1" 12 "Night_12" 11 "Night_11" 10 "Night_10" 9 "Night_9" 8 "Night_8" 7 "Night_7" 6 "Night_6" 5 "Night_5" 4 "Night_4" 3 "Night_3" 2 "Night_2" 1 "Night_1" 0 "Off" ;
VAL_ 947 Day_Night_Status 3 "NotUsed" 2 "Night" 1 "Day" 0 "Null" ;
VAL_ 947 Remote_Start_Status 3 "Invalid" 2 "Unknown" 1 "Remote" 0 "Null" ;
VAL_ 947 DrStatTgate_B_Actl 1 "Ajar" 0 "Closed" ;
VAL_ 947 DrStatRr_B_Actl 1 "Ajar" 0 "Closed" ;
VAL_ 947 DrStatRl_B_Actl 1 "Ajar" 0 "Closed" ;
VAL_ 947 DrStatPsngr_B_Actl 1 "Ajar" 0 "Closed" ;
VAL_ 947 DrStatInnrTgate_B_Actl 1 "Ajar" 0 "Closed" ;
VAL_ 947 DrStatHood_B_Actl 1 "Ajar" 0 "Closed" ;
VAL_ 947 DrStatDrv_B_Actl 1 "Ajar" 0 "Closed" ;
VAL_ 947 PrkBrkActv_B_Actl 1 "Active" 0 "Inactive" ;
VAL_ 947 LifeCycMde_D_Actl 3 "Transport" 2 "NotUsed" 1 "Factory" 0 "Normal" ;
VAL_ 947 Delay_Accy 1 "On" 0 "Off" ;
VAL_ 947 CrashEvnt_D_Stat 3 "Invalid" 2 "Fuel_Cutoff_Event" 1 "Deploy_Event" 0 "No_Event" ;
VAL_ 947 FuelPmpInhbt_B_Stat 1 "Inhibit" 0 "No_Inibit" ;
VAL_ 947 BodySrvcRqd_B_Rq 1 "Yes" 0 "No" ;
VAL_ 1084 BattULoState_D_Qlty 3 "OK" 2 "Not_Within_Specifications" 1 "Eval_In_Progress" 0 "Fault" ;
VAL_ 1084 BSFault 1 "Fault" 0 "No_Fault" ;
VAL_ 1084 BattULo2_Te_Actl 127 "Fault" ;
VAL_ 1068 EngStrtInhbt_B_RqBatt 1 "Start_Inhibit" 0 "Dont_Care" ;
VAL_ 1068 BattULoChrg_D_Rq 3 "Low_Battery_Temperature" 2 "Charging_Requested" 1 "Chrg_Requested_HighCurrent" 0 "No_Request" ;
VAL_ 1068 PwSysULoFalt_D_Stat 15 "Not_Used_6" 14 "LowBatterySOC" 13 "PSS_Shed2_Contin" 12 "Not_Used_4" 11 "Not_Used_3" 10 "Not_Used_2" 9 "BattMonitoringSensorFault" 8 "LowBattVoltDuringPwSrcOn" 7 "LowBatt2_PowerSaveMode" 6 "LowBatt1_Warning" 5 "Overvoltage" 4 "Fault_NoOutput" 3 "Fault_ReducedOutput" 2 "Fault_Nonspecific" 1 "Cluster_Proveout" 0 "No_Fault" ;
VAL_ 1068 Shed_T_Eng_Off_B 1 "Active" 0 "Inactive" ;
VAL_ 1068 Shed_Feature_Group_ID 16 "PtcHeater" 14 "HtdMirr" 13 "HvacRearBlwr_Third" 12 "HvacRearBlwr_Second" 11 "HvacRearBlwr_First" 31 "All LSHED1 Features" 10 "Htd_Windscrn" 9 "SpltHtdBcklight_HtdMirr" 8 "HtdBcklight_HtdMirr" 7 "HtdCoolSeat_FrtDriver" 6 "HtdCoolSeat_FrtPass" 5 "HtdCoolSeat_RearPass" 4 "HtdCoolSeat_RearDriver" 3 "SmartTrlrTowBattCharge" 2 "Htd_StrWhl" 1 "Htd_Washer_Fluid" 0 "No_LSHED1_Features" 15 "Engine_Coolant_Fan" ;
VAL_ 1068 Shed_Drain_Eng_Off_B 1 "Active" 0 "Inactive" ;
VAL_ 1068 Shed_Level_Req 7 "Unused_2" 6 "Loads_On" 5 "SHED_ENG_OFF" 4 "SOON_ENG_OFF" 3 "SHED2_CONTIN" 2 "SHED2_TRANS" 1 "SHED1" 0 "NO_SHED" ;
VAL_ 1068 ULoRgenTestMde_B_Rq 1 "Request" 0 "NoRequest" ;
VAL_ 1068 ChargeMode 7 "Undefined_2" 6 "Undefined_1" 5 "Battery_Identify" 4 "Battery_Refresh" 3 "SlowRegenAllowNoDischarge" 2 "Fast_Regen_Allowed" 1 "Slow_Regen_Allowed" 0 "Conventional_Charging" ;
VAL_ 1068 IdleSpeedIncrease_El 1 "Yes" 0 "No" ;
VAL_ 1068 Batt_Lo_SoC_B 1 "Active" 0 "Inactive" ;
VAL_ 1068 PeriodicElLoad_B_Stat 1 "Active" 0 "Inactive" ;
VAL_ 1068 Batt_Crit_SoC_B 1 "Active" 0 "Inactive" ;
VAL_ 146 VehVert2_A_Actl 8191 "Faulty" 8190 "NoDataExists" ;
VAL_ 146 VehLong2_A_Actl 8191 "Faulty" 8190 "NoDataExists" ;
VAL_ 146 VehLat2_A_Actl 8191 "Faulty" 8190 "NoDataExists" ;
VAL_ 146 VehVertAActl_D_Qf 3 "OK" 2 "Not_Within_Specifications" 1 "No_Data_Exists" 0 "Faulty" ;
VAL_ 146 VehLongAActl_D_Qf 3 "OK" 2 "Not_Within_Specifications" 1 "No_Data_Exists" 0 "Faulty" ;
VAL_ 146 VehLatAActl_D_Qf 3 "OK" 2 "Not_Within_Specifications" 1 "No_Data_Exists" 0 "Faulty" ;
VAL_ 997 PersIndexCcm_D_Actl 7 "Unused_3" 6 "Unused_2" 5 "Unused_1" 4 "Vehicle" 3 "PERS_4" 2 "PERS_3" 1 "PERS_2" 0 "PERS_1" ;
VAL_ 983 CmbbObjRelLong_V_Actl 1023 "Faulty" 1022 "NoDataExists" ;
VAL_ 983 CmbbObjRelLat_V_Actl 511 "Faulty" 510 "NoDataExists" ;
VAL_ 983 CmbbObjDistLong_L_Actl 1023 "Faulty" 1022 "NoDataExists" ;
VAL_ 983 CmbbObjDistLat_L_Actl 511 "Faulty" 510 "NoDataExists" ;
VAL_ 983 CmbbObjConfdnc_D_Stat 3 "High" 2 "Medium" 1 "Low" 0 "NotDetermined" ;
VAL_ 983 CmbbObjColl_T_Actl 127 "Faulty" 126 "NoDataExists" ;
VAL_ 983 CmbbObjClass_D_Stat 15 "NotUsed_9" 14 "NotUsed_8" 13 "NotUsed_7" 12 "NotUsed_6" 11 "NotUsed_5" 10 "NotUsed_4" 9 "NotUsed_3" 8 "NotUsed_2" 7 "NotUsed_1" 6 "Unclassified_Vehicle" 5 "Bicycle" 4 "Pedestrian" 3 "Truck" 2 "Motorcycle" 1 "Vehicle" 0 "Undetermined" ;
VAL_ 983 EsaEnbl_D2_Rq 3 "NotConfigured" 2 "Enabled" 1 "Pending" 0 "Disabled" ;
VAL_ 980 AdbBrdr1DistRigh_D_Stat 15 "DistGreater800m" 14 "Dist700mTo800m" 13 "Dist600mTo700m" 12 "Dist500mTo600m" 11 "Dist400mTo500m" 10 "Dist300mTo400m" 9 "Dist200mTo300m" 8 "Dist175mTo200m" 7 "Dist150mTo175m" 6 "Dist125mTo150m" 5 "Dist100mTo125m" 4 "Dist75mTo100m" 3 "Dist50mTo75m" 2 "Dist25mTo50m" 1 "Dist15mTo25m" 0 "Dist0mTo15m" ;
VAL_ 980 AdbBrdr1DistLeft_D_Stat 15 "DistGreater800m" 14 "Dist700mTo800m" 13 "Dist600mTo700m" 12 "Dist500mTo600m" 11 "Dist400mTo500m" 10 "Dist300mTo400m" 9 "Dist200mTo300m" 8 "Dist175mTo200m" 7 "Dist150mTo175m" 6 "Dist125mTo150m" 5 "Dist100mTo125m" 4 "Dist75mTo100m" 3 "Dist50mTo75m" 2 "Dist25mTo50m" 1 "Dist15mTo25m" 0 "Dist0mTo15m" ;
VAL_ 980 AdbMde1_D_Rq 3 "MarkerLightFlashing" 2 "MarkerLightConstant" 1 "Spot" 0 "None" ;
VAL_ 980 AdbIntns1_D_Rq 3 "Maximum" 2 "Medium" 1 "Low" 0 "Off" ;
VAL_ 980 AdbBrdr1Up_An_Rq 511 "Faulty" 510 "NoDataExists" ;
VAL_ 980 AdbBrdr1Right_An_Rq 2047 "Faulty" 2046 "NoDataExists" ;
VAL_ 980 AdbBrdr1Low_An_Rq 511 "Faulty" 510 "NoDataExists" ;
VAL_ 980 AdbBrdr1Left_An_Rq 2047 "Faulty" 2046 "NoDataExists" ;
VAL_ 976 SuspClkSync_No_Actl 255 "Faulty" 254 "NoDataExists" ;
VAL_ 976 SrpSigValid_B_Stat 1 "True" 0 "False" ;
VAL_ 976 SrpHghtRight_L_Actl 511 "Faulty" 510 "NoDataExists" ;
VAL_ 976 SrpHghtLeft_L_Actl 511 "Faulty" 510 "NoDataExists" ;
VAL_ 976 SrpEventRight_D_Stat 3 "Faulty" 2 "Bump" 1 "Pothole" 0 "NoEvent" ;
VAL_ 976 SrpEventLeft_D_Stat 3 "Faulty" 2 "Bump" 1 "Pothole" 0 "NoEvent" ;
VAL_ 976 SrpDistRight_L_Actl 511 "Faulty" 510 "NoDataExists" ;
VAL_ 976 SrpDistLeft_L_Actl 511 "Faulty" 510 "NoDataExists" ;
VAL_ 973 LaSysOffStat_D_Dsply 3 "Level_3" 2 "Level_2" 1 "Level_1" 0 "Level_0" ;
VAL_ 973 TsrVl2PrmntMsgTxt_D_Rq 3 "NotUsed" 2 "ShowPermanentlyWithSupp" 1 "ShowPermanentlyWithoutSupp" 0 "DoNotShowSignPermanent" ;
VAL_ 973 TsrVl1PrmntMsgTxt_D_Rq 3 "NotUsed" 2 "ShowPermanentlyWithSupp" 1 "ShowPermanentlyWithoutSupp" 0 "DoNotShowSignPermanent" ;
VAL_ 973 TsrVl2RstrcMsgTxt2_D_Rq 7 "NotUsed" 6 "Time" 5 "Trailer" 4 "Snow" 3 "RainWet" 2 "NoRecognizableRestrictn" 1 "NoSpeedLimitRestrictn" 0 "Null" ;
VAL_ 973 TsrVl1RstrcMsgTxt2_D_Rq 7 "NotUsed" 6 "Time" 5 "Trailer" 4 "Snow" 3 "RainWet" 2 "NoRecognizableRestrictn" 1 "NoSpeedLimitRestrictn" 0 "Null" ;
VAL_ 973 TsrOvtkMsgTxt2_D_Rq 15 "NotUsed5" 14 "NotUsed4" 13 "NotUsed3" 12 "NotUsed2" 11 "NotUsed1" 10 "LimForTrucksCancelled" 9 "LimForTrucksWoQlfdRstrc" 8 "LimForTrucksWithoutRstrc" 7 "LimAllCancelled" 6 "LimAllWithRstrcTime" 5 "LimAllWithRstrcTrailer" 4 "LimAllWithRstrcSnow" 3 "LimAllWithRstrcRain" 2 "LimAllWithoutQlfdRstrc" 1 "LimAllWithoutRestriction" 0 "OvertakingAllowed" ;
VAL_ 973 WwaWarn_B_Rq 1 "On" 0 "Off" ;
VAL_ 973 TsrVlUnitMsgTxt_D_Rq 3 "NoDataExists" 2 "Mph" 1 "Kph" 0 "Null" ;
VAL_ 973 TsrVLim2MsgTxt_D_Rq 255 "NoLimit" 254 "NotUsed2" 253 "NotUsed1" 252 "NotToBeDisplayed" 251 "LimitCancelled" 31 "1F_FA_Message31_250" 30 "Message30" 29 "Message29" 28 "Message28" 27 "Message27" 26 "Message26" 25 "Message25" 24 "Message24" 23 "Message23" 22 "Message22" 21 "Message21" 20 "Message20" 19 "Message19" 18 "Message18" 17 "Message17" 16 "Message16" 15 "Message15" 14 "Message14" 13 "Message13" 12 "Message12" 11 "Message11" 10 "Message10" 9 "Message9" 8 "Message8" 7 "Message7" 6 "Message6" 5 "Message5" 4 "Message4" 3 "Message3" 2 "Message2" 1 "Message1" 0 "Null" ;
VAL_ 973 TsrVLim1MsgTxt_D_Rq 255 "NoLimit" 254 "NotUsed2" 253 "NotUsed1" 252 "NotToBeDisplayed" 251 "LimitCancelled" 31 "1F_FA_Message31_250" 30 "Message30" 29 "Message29" 28 "Message28" 27 "Message27" 26 "Message26" 25 "Message25" 24 "Message24" 23 "Message23" 22 "Message22" 21 "Message21" 20 "Message20" 19 "Message19" 18 "Message18" 17 "Message17" 16 "Message16" 15 "Message15" 14 "Message14" 13 "Message13" 12 "Message12" 11 "Message11" 10 "Message10" 9 "Message9" 8 "Message8" 7 "Message7" 6 "Message6" 5 "Message5" 4 "Message4" 3 "Message3" 2 "Message2" 1 "Message1" 0 "Null" ;
VAL_ 973 TsrVl2StatMsgTxt_D_Rq 3 "LimitOutdated" 2 "LimitReiable" 1 "LimitChanged" 0 "Null" ;
VAL_ 973 TsrVl2RstrcMsgTxt_D_Rq 3 "NotUsed" 2 "NoRecognizableRestriction" 1 "NoSpeedLimitRestriction" 0 "Null" ;
VAL_ 973 TsrVl1StatMsgTxt_D_Rq 3 "LimitOutdated" 2 "LimitReiable" 1 "LimitChanged" 0 "Null" ;
VAL_ 973 TsrVl1RstrcMsgTxt_D_Rq 3 "NotUsed" 2 "NoRecognizableRestriction" 1 "NoSpeedLimitRestriction" 0 "Null" ;
VAL_ 973 TsrStatMsgTxt_D_Rq 7 "NotUsed" 6 "NoDataExists" 5 "TSR_Error" 4 "Available_NavigationOnly" 3 "Available_CameraOnly" 2 "Available_FusionMode" 1 "TSR_Off" 0 "Null" ;
VAL_ 973 TsrOvtkStatMsgTxt_D_Rq 3 "LimitOutdated" 2 "LimitReiable" 1 "LimitChanged" 0 "Null" ;
VAL_ 973 TsrOvtkMsgTxt_D_Rq 7 "LimForTrucksCancelled" 6 "LimForTrucksWoQlfdRstrc" 5 "LimForTrucksWithoutRstrc" 4 "LimAllCancelled" 3 "LimAllWithoutQlfdRstrc" 2 "LimAllWithoutRestriction" 1 "OvertakingAllowed" 0 "Null" ;
VAL_ 973 TsrOswWarnMsgTxt_D_Rq 3 "NotUsed" 2 "True" 1 "False" 0 "Null" ;
VAL_ 973 TsrMsgTxt_D_Rq 15 "NotUsed6" 14 "NotUsed5" 13 "NotUsed4" 12 "NotUsed3" 11 "NotUsed2" 10 "NotUsed1" 9 "RecgnzdSignNotUsblForDsply" 8 "LimitedSystemPerformance" 7 "OffRoad" 6 "RegionNotSupported" 5 "CountryNotSupported" 4 "WrngNavDatIncompDatCarrier" 3 "NoNavDataAvailable" 2 "NoNavAvailableSwitchedOff" 1 "NoInformationAllOK" 0 "Null" ;
VAL_ 970 LkaDrvOvrrd_D_Rq 3 "Level_3" 2 "Level_2" 1 "Level_1" 0 "Level_0" ;
VAL_ 970 LkaActvStats_D2_Req 7 "NotUsed" 6 "LkaIncrIntervRight" 5 "LkaSupprRight" 4 "LkaStandIntervRight" 3 "LkaSupprLeft" 2 "LkaStandIntervLeft" 1 "LkaIncrIntervLeft" 0 "LkaNoInterv" ;
VAL_ 970 LaRefAng_No_Req 4095 "Fault" ;
VAL_ 970 LaRampType_B_Req 1 "Quick" 0 "Smooth" ;
VAL_ 970 LaCurvature_No_Calc 4095 "Fault" ;
VAL_ 970 LdwActvStats_D_Req 7 "LDW_Suppress_Right_Left" 6 "Not_Used2" 5 "LDW_Suppress_Right" 4 "LDW_Warning_Right" 3 "LDW_Suppress_Left" 2 "LDW_Warning_Left" 1 "LDW_DemoVibration" 0 "LDW_Idle" ;
VAL_ 970 LdwActvIntns_D_Req 3 "High" 2 "Medium" 1 "Low" 0 "None" ;
VAL_ 962 AdbBrdr3DistRigh_D_Stat 15 "DistGreater800m" 14 "Dist700mTo800m" 13 "Dist600mTo700m" 12 "Dist500mTo600m" 11 "Dist400mTo500m" 10 "Dist300mTo400m" 9 "Dist200mTo300m" 8 "Dist175mTo200m" 7 "Dist150mTo175m" 6 "Dist125mTo150m" 5 "Dist100mTo125m" 4 "Dist75mTo100m" 3 "Dist50mTo75m" 2 "Dist25mTo50m" 1 "Dist15mTo25m" 0 "Dist0mTo15m" ;
VAL_ 962 AdbBrdr3DistLeft_D_Stat 15 "DistGreater800m" 14 "Dist700mTo800m" 13 "Dist600mTo700m" 12 "Dist500mTo600m" 11 "Dist400mTo500m" 10 "Dist300mTo400m" 9 "Dist200mTo300m" 8 "Dist175mTo200m" 7 "Dist150mTo175m" 6 "Dist125mTo150m" 5 "Dist100mTo125m" 4 "Dist75mTo100m" 3 "Dist50mTo75m" 2 "Dist25mTo50m" 1 "Dist15mTo25m" 0 "Dist0mTo15m" ;
VAL_ 962 AdbMde3_D_Rq 3 "MarkerLightFlashing" 2 "MarkerLightConstant" 1 "Spot" 0 "None" ;
VAL_ 962 AdbIntns3_D_Rq 3 "Maximum" 2 "Medium" 1 "Low" 0 "Off" ;
VAL_ 962 AdbBrdr3Up_An_Rq 511 "Faulty" 510 "NoDataExists" ;
VAL_ 962 AdbBrdr3Right_An_Rq 2047 "Faulty" 2046 "NoDataExists" ;
VAL_ 962 AdbBrdr3Low_An_Rq 511 "Faulty" 510 "NoDataExists" ;
VAL_ 962 AdbBrdr3Left_An_Rq 2047 "Faulty" 2046 "NoDataExists" ;
VAL_ 961 AdbBrdr2DistRigh_D_Stat 15 "DistGreater800m" 14 "Dist700mTo800m" 13 "Dist600mTo700m" 12 "Dist500mTo600m" 11 "Dist400mTo500m" 10 "Dist300mTo400m" 9 "Dist200mTo300m" 8 "Dist175mTo200m" 7 "Dist150mTo175m" 6 "Dist125mTo150m" 5 "Dist100mTo125m" 4 "Dist75mTo100m" 3 "Dist50mTo75m" 2 "Dist25mTo50m" 1 "Dist15mTo25m" 0 "Dist0mTo15m" ;
VAL_ 961 AdbBrdr2DistLeft_D_Stat 15 "DistGreater800m" 14 "Dist700mTo800m" 13 "Dist600mTo700m" 12 "Dist500mTo600m" 11 "Dist400mTo500m" 10 "Dist300mTo400m" 9 "Dist200mTo300m" 8 "Dist175mTo200m" 7 "Dist150mTo175m" 6 "Dist125mTo150m" 5 "Dist100mTo125m" 4 "Dist75mTo100m" 3 "Dist50mTo75m" 2 "Dist25mTo50m" 1 "Dist15mTo25m" 0 "Dist0mTo15m" ;
VAL_ 961 AdbMde2_D_Rq 3 "MarkerLightFlashing" 2 "MarkerLightConstant" 1 "Spot" 0 "None" ;
VAL_ 961 AdbIntns2_D_Rq 3 "Maximum" 2 "Medium" 1 "Low" 0 "Off" ;
VAL_ 961 AdbBrdr2Up_An_Rq 511 "Faulty" 510 "NoDataExists" ;
VAL_ 961 AdbBrdr2Right_An_Rq 2047 "Faulty" 2046 "NoDataExists" ;
VAL_ 961 AdbBrdr2Low_An_Rq 511 "Faulty" 510 "NoDataExists" ;
VAL_ 961 AdbBrdr2Left_An_Rq 2047 "Faulty" 2046 "NoDataExists" ;
VAL_ 394 AccStopStat_D_Dsply 3 "PressResume" 2 "Stopped" 1 "ResumeReady" 0 "NoDisplay" ;
VAL_ 394 AccTrgDist2_D_Dsply 15 "DIST_ACTIVE_13_Farthest" 14 "DIST_ACTIVE_12" 13 "DIST_ACTIVE_11" 12 "DIST_ACTIVE_10" 11 "DIST_ACTIVE_9" 10 "DIST_ACTIVE_8" 9 "DIST_ACTIVE_7" 8 "DIST_ACTIVE_6" 7 "DIST_ACTIVE_5" 6 "DIST_ACTIVE_4" 5 "DIST_ACTIVE_3" 4 "DIST_ACTIVE_2" 3 "DIST_ACTIVE_1_Closest" 2 "DIST_ACTIVE_No_Target" 1 "DIST_STANDBY" 0 "DIST_OFF" ;
VAL_ 394 AccStopRes_B_Dsply 1 "Yes" 0 "No" ;
VAL_ 394 TjaWarn_D_Rq 7 "HardTakeOverEyesOff" 6 "SoftTakeOverEyesOff" 5 "HaLaneDeptWarningLeft" 4 "HaLaneDeptWarningRight" 3 "HardTakeOverLevel2" 2 "HardTakeOverLevel1" 1 "TrafficJamAssistCancel" 0 "NoWarning" ;
VAL_ 394 Tja_D_Stat 7 "NotUsed_1" 6 "ActiveWarningRight" 5 "ActiveWarningLeft" 4 "ActiveInterventionRight" 3 "ActiveInterventionLeft" 2 "Active" 1 "Standby" 0 "Off" ;
VAL_ 394 TjaMsgTxt_D_Dsply 7 "NotUsed_4" 6 "NotUsed_3" 5 "NotUsed_2" 4 "NotUsed_1" 3 "TurnOnAdaptCruiseControl" 2 "TrafficJamAssistSelected" 1 "TrafficJamAssistUnavailabl" 0 "NoMessage" ;
VAL_ 394 IaccLamp_D_Rq 3 "NotUsed_2" 2 "NotUsed_1" 1 "DisplayIaccIcon" 0 "DoNotDisplayIaccIcon" ;
VAL_ 394 AccMsgTxt_D2_Rq 15 "Brakes_Warm" 14 "NCC_Enabled_Warning" 13 "IACC_TJA_Selected" 12 "ACC_TJA_Selected" 11 "IACC_Selected" 10 "Press_Brake_To_Hold" 9 "Only_Following_In_Low_Spd" 8 "TJA_Unavailable" 7 "Shift_Down" 6 "IACC_Unavailable" 5 "ACC_Selected" 4 "ACC_Overridden" 3 "Brake_Capacity_Warning" 2 "ACC_Cancelled" 1 "ACC_Unavailable" 0 "No_Text" ;
VAL_ 394 FcwDeny_B_Dsply 1 "Yes" 0 "No" ;
VAL_ 394 FcwMemStat_B_Actl 1 "On" 0 "Off" ;
VAL_ 394 AccTGap_B_Dsply 1 "Yes" 0 "No" ;
VAL_ 394 CadsAlignIncplt_B_Actl 1 "Yes" 0 "No" ;
VAL_ 394 AccFllwMde_B_Dsply 1 "Yes" 0 "No" ;
VAL_ 394 CadsRadrBlck_B_Actl 1 "Yes" 0 "No" ;
VAL_ 394 CmbbPostEvnt_B_Dsply 1 "Yes" 0 "No" ;
VAL_ 394 AccStopMde_B_Dsply 1 "Yes" 0 "No" ;
VAL_ 394 FcwMemSens_D_Actl 3 "FCW_Sensitivity_3" 2 "FCW_Sensitivity_2" 1 "FCW_Sensitivity_1" 0 "Not_Used" ;
VAL_ 394 FcwMsgTxt_D_Rq 7 "Undefined_3" 6 "Undefined_2" 5 "Low_Visibility" 4 "Unavailable_DueTo_LowSpeed" 3 "Available" 2 "Unavailable" 1 "Off" 0 "No_Text" ;
VAL_ 394 AccWarn_D_Dsply 3 "BrakeReleaseWarn_In_StopMd" 2 "Brake_Capacity_Warning" 1 "Cancel_Warning" 0 "No_Warning" ;
VAL_ 394 FcwVisblWarn_B_Rq 1 "On" 0 "Off" ;
VAL_ 394 FcwAudioWarn_B_Rq 1 "On" 0 "Off" ;
VAL_ 394 AccTGap_D_Dsply 7 "Undefined_2" 6 "Undefined_1" 5 "Time_Gap_5" 4 "Time_Gap_4" 3 "Time_Gap_3" 2 "Time_Gap_2" 1 "Time_Gap_1" 0 "Not_Used" ;
VAL_ 394 AccMemEnbl_B_RqDrv 1 "Adaptive_Cruise" 0 "Normal_Cruise" ;
VAL_ 391 HudBlk3_B_Rq 1 "Yes" 0 "No" ;
VAL_ 391 HudBlk2_B_Rq 1 "Yes" 0 "No" ;
VAL_ 391 HudBlk1_B_Rq 1 "Yes" 0 "No" ;
VAL_ 391 HudFlashRate_D_Actl 3 "Unused" 2 "Flash_4Hz_50Prct_DutyCycle" 1 "On" 0 "Off" ;
VAL_ 391 CmbbBrkPrchg_D_Rq 3 "Undefined" 2 "Level_2_PreCharge_Request" 1 "Level_1_PreCharge_Request" 0 "No_PreCharge_Request" ;
VAL_ 391 CmbbBrkDecel_B_Rq 1 "Yes" 0 "No" ;
VAL_ 391 CmbbBaSens_D_Rq 3 "Level_3" 2 "Level_2" 1 "Level_1" 0 "Normal" ;
VAL_ 390 AccBrkPulse_B_Rq 1 "True" 0 "False" ;
VAL_ 390 AccAutoResum_D_Rq 3 "NotUsed" 2 "Active" 1 "Pending" 0 "Off" ;
VAL_ 390 AccBrkPrkEl_B_Rq 1 "Yes" 0 "No" ;
VAL_ 390 Cmbb_B_Enbl 1 "Yes" 0 "No" ;
VAL_ 390 CmbbOvrrd_B_RqDrv 1 "Yes" 0 "No" ;
VAL_ 390 CmbbDeny_B_Actl 1 "Yes" 0 "No" ;
VAL_ 390 CmbbEngTqMn_B_Rq 1 "Yes" 0 "No" ;
VAL_ 390 AccDeny_B_Rq 1 "Yes" 0 "No" ;
VAL_ 390 AccResumEnbl_B_Rq 1 "Yes" 0 "No" ;
VAL_ 390 AccCancl_B_Rq 1 "Yes" 0 "No" ;
VAL_ 390 AccBrkPrchg_B_Rq 1 "Yes" 0 "No" ;
VAL_ 390 AccBrkDecel_B_Rq 1 "Active" 0 "Inactive" ;
VAL_ 390 AccStopStat_B_Rq 1 "Yes" 0 "No" ;
VAL_ 942 PrkAidDrvDir_D_Stat 7 "NotUsed_2" 6 "NotUsed_1" 5 "BackwardNegative" 4 "ForwardNegative" 3 "BackwardPositive" 2 "ForwardPositive" 1 "NoMotion" 0 "DirectionNotKnown" ;
VAL_ 942 PrkAidAcsyRear_D_Stat 3 "NotUsed" 2 "On" 1 "Off" 0 "Null" ;
VAL_ 942 PrkAidAcsyFront_D_Stat 3 "NotUsed" 2 "On" 1 "Off" 0 "Null" ;
VAL_ 930 BalrWndwRight_B_Stat 1 "Enable" 0 "Disable" ;
VAL_ 930 BalrSnsRight_D_Falt 3 "Invalid" 2 "SystemFailure" 1 "Blocked" 0 "Clear" ;
VAL_ 930 WndwPsngrRear_D_RqBalrr 3 "NotUsed" 2 "Stop" 1 "AutoUp" 0 "NoRequest" ;
VAL_ 930 WndwPsngr_D_RqBalrr 3 "NotUsed" 2 "Stop" 1 "AutoUp" 0 "NoRequest" ;
VAL_ 930 WndwDrvRear_D_RqBalrr 3 "NotUsed" 2 "Stop" 1 "AutoUp" 0 "NoRequest" ;
VAL_ 930 WndwDrv_D_RqBalrr 3 "NotUsed" 2 "Stop" 1 "AutoUp" 0 "NoRequest" ;
VAL_ 930 BalrRight_D_Stat 3 "Inhibited" 2 "Disabled" 1 "On" 0 "Off" ;
VAL_ 930 BalrMdeSelRight_B_Stat 1 "Enable" 0 "Disable" ;
VAL_ 930 BalrMdeRight_D_Stat 3 "NotUsed" 2 "High" 1 "Medium" 0 "Low" ;
VAL_ 930 BalrLckRight_B_Stat 1 "Enable" 0 "Disable" ;
VAL_ 930 BalrChimeRight_D_Rq 3 "NotUsed" 2 "Soft" 1 "Normal" 0 "Off" ;
VAL_ 930 CamraRearOn_B_RqBalrr 1 "Active" 0 "Inactive" ;
VAL_ 930 DrLckActv_B_RqBalrr 1 "Active" 0 "Null" ;
VAL_ 929 BalrChimeLeft_D_Rq 3 "NotUsed" 2 "Soft" 1 "Normal" 0 "Off" ;
VAL_ 929 BalrLeft_D_Stat 3 "Inhibited" 2 "Disabled" 1 "On" 0 "Off" ;
VAL_ 929 BalrWndwLeft_B_Stat 1 "Enable" 0 "Disable" ;
VAL_ 929 WndwPsngrRear_D_RqBalrl 3 "NotUsed" 2 "Stop" 1 "AutoUp" 0 "NoRequest" ;
VAL_ 929 WndwPsngr_D_RqBalrl 3 "NotUsed" 2 "Stop" 1 "AutoUp" 0 "NoRequest" ;
VAL_ 929 WndwDrvRear_D_RqBalrl 3 "NotUsed" 2 "Stop" 1 "AutoUp" 0 "NoRequest" ;
VAL_ 929 WndwDrv_D_RqBalrl 3 "NotUsed" 2 "Stop" 1 "AutoUp" 0 "NoRequest" ;
VAL_ 929 BalrSnsLeft_D_Falt 3 "Invalid" 2 "SystemFailure" 1 "Blocked" 0 "Clear" ;
VAL_ 929 BalrMdeSelLeft_B_Stat 1 "Enable" 0 "Disable" ;
VAL_ 929 BalrMdeLeft_D_Stat 3 "NotUsed" 2 "High" 1 "Medium" 0 "Low" ;
VAL_ 929 BalrLckLeft_B_Stat 1 "Enable" 0 "Disable" ;
VAL_ 929 CamraRearOn_B_RqBalrl 1 "Active" 0 "Inactive" ;
VAL_ 929 DrLckActv_B_RqBalrl 1 "Active" 0 "Null" ;
VAL_ 402 PrkAidSwtch_D_RqMnu 1 "Pressed" 0 "Not_Pressed" ;
VAL_ 402 ApaSwtch_D_RqMnu 3 "NotUsed2" 2 "NotUsed1" 1 "Pressed" 0 "Not_Pressed" ;
VAL_ 402 ApaMdeStat_D_RqDrv 7 "Faulty" 6 "Off" 5 "NotUsed2" 4 "NotUsed1" 3 "POA" 2 "PPA" 1 "SAPP" 0 "Inactive" ;
VAL_ 402 CamraViewSplit_B_Rq 1 "On" 0 "Off" ;
VAL_ 402 CamraZoomMan_D_Rq 7 "Unknown" 6 "Invalid" 5 "Zoom_Level_V" 4 "Zoom_Level_IV" 3 "Zoom_Level_III" 2 "Zoom_Level_II" 1 "Zoom_Level_I" 0 "Off" ;
VAL_ 402 CamraOvrlStat_D_Rq 1 "On" 0 "Off" ;
VAL_ 402 CamraOvrlDyn_D_Rq 1 "On" 0 "Off" ;
VAL_ 402 CamAutoTowbarZoom 1 "On" 0 "Off" ;
VAL_ 402 DistanceBarSetting 1 "On" 0 "Off" ;
VAL_ 924 DcacOut_Pw_Mx 2047 "Faulty" 2046 "NoDataExists" ;
VAL_ 924 DcacOut2_Pw_Actl 8191 "Faulty" 8190 "NoDataExists" ;
VAL_ 924 DcacOut1_Pw_Actl 8191 "Faulty" 8190 "NoDataExists" ;
VAL_ 924 DcacIn_Pw_Mx 2047 "Faulty" 2046 "NoDataExists" ;
VAL_ 923 DcacIn_U2_Actl 4095 "Faulty" 4094 "NoDataExists" ;
VAL_ 923 DcacIn_U_Actl 4095 "Fault" 4094 "NoDataExists" ;
VAL_ 923 DcacIn_I_Actl 2047 "Faulty" 2046 "NoDataExists" ;
VAL_ 923 Dcac_Te_Actl 255 "Faulty" 254 "NoDataExists" ;
VAL_ 922 DcacBp2BrkrOpn_B_Falt 1 "Faulted" 0 "NotFaulted" ;
VAL_ 922 DcacBp1BrkrOpn_B_Falt 1 "Faulted" 0 "NotFaulted" ;
VAL_ 922 DcacIpRcBrkrOpn_B_Falt 1 "Faulted" 0 "NotFaulted" ;
VAL_ 922 DcacRdy_D2_Stat 3 "Faulted" 2 "RecoverableFault" 1 "Active" 0 "Idle" ;
VAL_ 922 DcacOvrld_B_Falt 1 "Faulted" 0 "NotFaulted" ;
VAL_ 922 DcacOverTe_B_Falt 1 "Faulted" 0 "NotFaulted" ;
VAL_ 922 DcacGfci_B_Falt 1 "Faulted" 0 "NotFaulted" ;
VAL_ 922 DcacErr_B_Stat 1 "Faulted" 0 "NotFaulted" ;
VAL_ 922 DcacAcUDetct_B_Falt 1 "Faulted" 0 "NotFaulted" ;
VAL_ 922 DcacPlugPrsnt_B_Stat 1 "Yes" 0 "No" ;
VAL_ 922 DcacClntFlw_D_Rq 3 "High" 2 "Medium" 1 "Low" 0 "Off" ;
VAL_ 922 CoolFanDcac_D_Rq 3 "High" 2 "Medium" 1 "Low" 0 "Off" ;
